VERSION "HINBNNNYYNNNYYNNNNNNNNNNNNYNNNYYYNNYNNNNNN/4//%%/4/'%**4NNN///"

NS_ :

BS_:

BU_: VirtualNMTMaster Master LadderDrive ControlPanel SupportFront SupportRear TTGateway

BO_ 1420 SSDO_012: 8 SupportFront
 SG_ supported_drive_modes_6502 m0 : 32|32@1+ (1,0) [0|4294967295] "" Vector__XXX
 SG_ SubIndex_6502 m25858M : 24|8@1+ (1,0) [0|0] "" Vector__XXX
 SG_ motor_service_period_6407 m0 : 32|32@1+ (1,0) [0|4294967295] "" Vector__XXX
 SG_ SubIndex_6407 m25607M : 24|8@1+ (1,0) [0|0] "" Vector__XXX
 SG_ motor_type_6402 m0 : 32|16@1+ (1,0) [0|65535] "" Vector__XXX
 SG_ SubIndex_6402 m25602M : 24|8@1+ (1,0) [0|0] "" Vector__XXX
 SG_ bitmask_60FE_02 m2 : 32|32@1+ (1,0) [0|4294967295] "" Vector__XXX
 SG_ physical_outputs_60FE_01 m1 : 32|32@1+ (1,0) [0|4294967295] "" Vector__XXX
 SG_ NrOfObjects_60FE_00 m0 : 32|8@1+ (1,0) [0|255] "" Vector__XXX
 SG_ SubIndex_60FE m24830M : 24|8@1+ (1,0) [0|2] "" Vector__XXX
 SG_ digital_inputs_60FD m0 : 32|32@1+ (1,0) [0|4294967295] "" Vector__XXX
 SG_ SubIndex_60FD m24829M : 24|8@1+ (1,0) [0|0] "" Vector__XXX
 SG_ polarity_607E m0 : 32|8@1+ (1,0) [0|255] "" Vector__XXX
 SG_ SubIndex_607E m24702M : 24|8@1+ (1,0) [0|0] "" Vector__XXX
 SG_ position_window_6067 m0 : 32|32@1+ (1,0) [0|4294967295] "" Vector__XXX
 SG_ SubIndex_6067 m24679M : 24|8@1+ (1,0) [0|0] "" Vector__XXX
 SG_ position_actual_value_6064 m0 : 32|32@1- (1,0) [-2147483648|2147483647] "" Vector__XXX
 SG_ SubIndex_6064 m24676M : 24|8@1+ (1,0) [0|0] "" Vector__XXX
 SG_ position_actual_value_6063 m0 : 32|32@1- (1,0) [-2147483648|2147483647] "" Vector__XXX
 SG_ SubIndex_6063 m24675M : 24|8@1+ (1,0) [0|0] "" Vector__XXX
 SG_ position_demand_value_6062 m0 : 32|32@1- (1,0) [-2147483648|2147483647] "" Vector__XXX
 SG_ SubIndex_6062 m24674M : 24|8@1+ (1,0) [0|0] "" Vector__XXX
 SG_ modes_of_operation_display_6061 m0 : 32|8@1- (1,0) [-128|127] "" Vector__XXX
 SG_ SubIndex_6061 m24673M : 24|8@1+ (1,0) [0|0] "" Vector__XXX
 SG_ modes_of_operation_6060 m0 : 32|8@1- (1,0) [-128|127] "" Vector__XXX
 SG_ SubIndex_6060 m24672M : 24|8@1+ (1,0) [0|0] "" Vector__XXX
 SG_ fault_reaction_option_code_605E m0 : 32|16@1- (1,0) [-32768|32767] "" Vector__XXX
 SG_ SubIndex_605E m24670M : 24|8@1+ (1,0) [0|0] "" Vector__XXX
 SG_ stop_option_code_605D m0 : 32|16@1- (1,0) [-32768|32767] "" Vector__XXX
 SG_ SubIndex_605D m24669M : 24|8@1+ (1,0) [0|0] "" Vector__XXX
 SG_ disable_operation_option_co_0001 m0 : 32|16@1- (1,0) [-32768|32767] "" Vector__XXX
 SG_ SubIndex_605C m24668M : 24|8@1+ (1,0) [0|0] "" Vector__XXX
 SG_ shutdown_option_code_605B m0 : 32|16@1- (1,0) [-32768|32767] "" Vector__XXX
 SG_ SubIndex_605B m24667M : 24|8@1+ (1,0) [0|0] "" Vector__XXX
 SG_ quick_stop_option_code_605A m0 : 32|16@1- (1,0) [-32768|32767] "" Vector__XXX
 SG_ SubIndex_605A m24666M : 24|8@1+ (1,0) [0|0] "" Vector__XXX
 SG_ delta_time_6049_02 m2 : 32|16@1+ (1,0) [0|65535] "" Vector__XXX
 SG_ delta_speed_6049_01 m1 : 32|32@1+ (1,0) [0|4294967295] "" Vector__XXX
 SG_ NrOfObjects_6049_00 m0 : 32|8@1+ (1,0) [0|255] "" Vector__XXX
 SG_ SubIndex_6049 m24649M : 24|8@1+ (1,0) [0|2] "" Vector__XXX
 SG_ delta_time_6048_02 m2 : 32|16@1+ (1,0) [0|65535] "" Vector__XXX
 SG_ delta_speed_6048_01 m1 : 32|32@1+ (1,0) [0|4294967295] "" Vector__XXX
 SG_ NrOfObjects_6048_00 m0 : 32|8@1+ (1,0) [0|255] "" Vector__XXX
 SG_ SubIndex_6048 m24648M : 24|8@1+ (1,0) [0|2] "" Vector__XXX
 SG_ vl_velocity_max_amount_6046_02 m2 : 32|32@1+ (1,0) [0|4294967295] "" Vector__XXX
 SG_ vl_velocity_min_amount_6046_01 m1 : 32|32@1+ (1,0) [0|4294967295] "" Vector__XXX
 SG_ vl_velocity_min_max_amount__0001 m0 : 32|8@1+ (1,0) [0|255] "" Vector__XXX
 SG_ SubIndex_6046 m24646M : 24|8@1+ (1,0) [0|2] "" Vector__XXX
 SG_ vl_control_effort_6044 m0 : 32|16@1- (1,0) [-32768|32767] "" Vector__XXX
 SG_ SubIndex_6044 m24644M : 24|8@1+ (1,0) [0|0] "" Vector__XXX
 SG_ vl_velocity_demand_6043 m0 : 32|16@1- (1,0) [-32768|32767] "" Vector__XXX
 SG_ SubIndex_6043 m24643M : 24|8@1+ (1,0) [0|0] "" Vector__XXX
 SG_ vl_target_velocity_6042 m0 : 32|16@1- (1,0) [-32768|32767] "" Vector__XXX
 SG_ SubIndex_6042 m24642M : 24|8@1+ (1,0) [0|0] "" Vector__XXX
 SG_ statusword_6041 m0 : 32|16@1+ (1,0) [0|65535] "" Vector__XXX
 SG_ SubIndex_6041 m24641M : 24|8@1+ (1,0) [0|0] "" Vector__XXX
 SG_ controlword_6040 m0 : 32|16@1+ (1,0) [0|65535] "" Vector__XXX
 SG_ SubIndex_6040 m24640M : 24|8@1+ (1,0) [0|0] "" Vector__XXX
 SG_ error_code_603F m0 : 32|16@1+ (1,0) [0|65535] "" Vector__XXX
 SG_ SubIndex_603F m24639M : 24|8@1+ (1,0) [0|0] "" Vector__XXX
 SG_ abort_connection_option_cod_0001 m0 : 32|16@1- (1,0) [-32768|3] "" Vector__XXX
 SG_ SubIndex_6007 m24583M : 24|8@1+ (1,0) [0|0] "" Vector__XXX
 SG_ NrOfMappedObjects_1A06_00 m0 : 32|8@1+ (1,0) [0|8] "" Vector__XXX
 SG_ SubIndex_1A06 m6662M : 24|8@1+ (1,0) [0|0] "" Vector__XXX
 SG_ NrOfMappedObjects_1A05_00 m0 : 32|8@1+ (1,0) [0|8] "" Vector__XXX
 SG_ SubIndex_1A05 m6661M : 24|8@1+ (1,0) [0|0] "" Vector__XXX
 SG_ NrOfMappedObjects_1A04_00 m0 : 32|8@1+ (1,0) [0|8] "" Vector__XXX
 SG_ SubIndex_1A04 m6660M : 24|8@1+ (1,0) [0|0] "" Vector__XXX
 SG_ NrOfMappedObjects_1A03_00 m0 : 32|8@1+ (1,0) [0|8] "" Vector__XXX
 SG_ SubIndex_1A03 m6659M : 24|8@1+ (1,0) [0|0] "" Vector__XXX
 SG_ NrOfMappedObjects_1A02_00 m0 : 32|8@1+ (1,0) [0|8] "" Vector__XXX
 SG_ SubIndex_1A02 m6658M : 24|8@1+ (1,0) [0|0] "" Vector__XXX
 SG_ NrOfMappedObjects_1A01_00 m0 : 32|8@1+ (1,0) [0|8] "" Vector__XXX
 SG_ SubIndex_1A01 m6657M : 24|8@1+ (1,0) [0|0] "" Vector__XXX
 SG_ mappedObj2_1A00_02 m2 : 32|32@1+ (1,0) [0|4294967295] "" Vector__XXX
 SG_ mappedObj1_1A00_01 m1 : 32|32@1+ (1,0) [0|4294967295] "" Vector__XXX
 SG_ NrOfMappedObjects_1A00_00 m0 : 32|8@1+ (1,0) [0|8] "" Vector__XXX
 SG_ SubIndex_1A00 m6656M : 24|8@1+ (1,0) [0|2] "" Vector__XXX
 SG_ EventTimer_1806_05 m5 : 32|16@1+ (1,0) [0|65535] "" Vector__XXX
 SG_ TransmissionType_1806_02 m2 : 32|8@1+ (1,0) [0|255] "" Vector__XXX
 SG_ COB_ID_1806_01 m1 : 32|32@1+ (1,0) [128|4294967295] "" Vector__XXX
 SG_ NrOfEntries_1806_00 m0 : 32|8@1+ (1,0) [2|5] "" Vector__XXX
 SG_ SubIndex_1806 m6150M : 24|8@1+ (1,0) [0|5] "" Vector__XXX
 SG_ EventTimer_1805_05 m5 : 32|16@1+ (1,0) [0|65535] "" Vector__XXX
 SG_ TransmissionType_1805_02 m2 : 32|8@1+ (1,0) [0|255] "" Vector__XXX
 SG_ COB_ID_1805_01 m1 : 32|32@1+ (1,0) [128|4294967295] "" Vector__XXX
 SG_ NrOfEntries_1805_00 m0 : 32|8@1+ (1,0) [2|5] "" Vector__XXX
 SG_ SubIndex_1805 m6149M : 24|8@1+ (1,0) [0|5] "" Vector__XXX
 SG_ EventTimer_1804_05 m5 : 32|16@1+ (1,0) [0|65535] "" Vector__XXX
 SG_ TransmissionType_1804_02 m2 : 32|8@1+ (1,0) [0|255] "" Vector__XXX
 SG_ COB_ID_1804_01 m1 : 32|32@1+ (1,0) [128|4294967295] "" Vector__XXX
 SG_ NrOfEntries_1804_00 m0 : 32|8@1+ (1,0) [2|5] "" Vector__XXX
 SG_ SubIndex_1804 m6148M : 24|8@1+ (1,0) [0|5] "" Vector__XXX
 SG_ EventTimer_1803_05 m5 : 32|16@1+ (1,0) [0|65535] "" Vector__XXX
 SG_ TransmissionType_1803_02 m2 : 32|8@1+ (1,0) [0|255] "" Vector__XXX
 SG_ COB_ID_1803_01 m1 : 32|32@1+ (1,0) [128|4294967295] "" Vector__XXX
 SG_ NrOfEntries_1803_00 m0 : 32|8@1+ (1,0) [2|5] "" Vector__XXX
 SG_ SubIndex_1803 m6147M : 24|8@1+ (1,0) [0|5] "" Vector__XXX
 SG_ EventTimer_1802_05 m5 : 32|16@1+ (1,0) [0|65535] "" Vector__XXX
 SG_ TransmissionType_1802_02 m2 : 32|8@1+ (1,0) [0|255] "" Vector__XXX
 SG_ COB_ID_1802_01 m1 : 32|32@1+ (1,0) [128|4294967295] "" Vector__XXX
 SG_ NrOfEntries_1802_00 m0 : 32|8@1+ (1,0) [2|5] "" Vector__XXX
 SG_ SubIndex_1802 m6146M : 24|8@1+ (1,0) [0|5] "" Vector__XXX
 SG_ EventTimer_1801_05 m5 : 32|16@1+ (1,0) [0|65535] "" Vector__XXX
 SG_ TransmissionType_1801_02 m2 : 32|8@1+ (1,0) [0|255] "" Vector__XXX
 SG_ COB_ID_1801_01 m1 : 32|32@1+ (1,0) [128|4294967295] "" Vector__XXX
 SG_ NrOfEntries_1801_00 m0 : 32|8@1+ (1,0) [2|5] "" Vector__XXX
 SG_ SubIndex_1801 m6145M : 24|8@1+ (1,0) [0|5] "" Vector__XXX
 SG_ EventTimer_1800_05 m5 : 32|16@1+ (1,0) [0|65535] "" Vector__XXX
 SG_ TransmissionType_1800_02 m2 : 32|8@1+ (1,0) [0|255] "" Vector__XXX
 SG_ COB_ID_1800_01 m1 : 32|32@1+ (1,0) [128|4294967295] "" Vector__XXX
 SG_ NrOfEntries_1800_00 m0 : 32|8@1+ (1,0) [2|5] "" Vector__XXX
 SG_ SubIndex_1800 m6144M : 24|8@1+ (1,0) [0|5] "" Vector__XXX
 SG_ NrOfMappedObjects_1607_00 m0 : 32|8@1+ (1,0) [0|8] "" Vector__XXX
 SG_ SubIndex_1607 m5639M : 24|8@1+ (1,0) [0|0] "" Vector__XXX
 SG_ NrOfMappedObjects_1606_00 m0 : 32|8@1+ (1,0) [0|8] "" Vector__XXX
 SG_ SubIndex_1606 m5638M : 24|8@1+ (1,0) [0|0] "" Vector__XXX
 SG_ NrOfMappedObjects_1605_00 m0 : 32|8@1+ (1,0) [0|8] "" Vector__XXX
 SG_ SubIndex_1605 m5637M : 24|8@1+ (1,0) [0|0] "" Vector__XXX
 SG_ NrOfMappedObjects_1604_00 m0 : 32|8@1+ (1,0) [0|8] "" Vector__XXX
 SG_ SubIndex_1604 m5636M : 24|8@1+ (1,0) [0|0] "" Vector__XXX
 SG_ NrOfMappedObjects_1603_00 m0 : 32|8@1+ (1,0) [0|8] "" Vector__XXX
 SG_ SubIndex_1603 m5635M : 24|8@1+ (1,0) [0|0] "" Vector__XXX
 SG_ NrOfMappedObjects_1602_00 m0 : 32|8@1+ (1,0) [0|8] "" Vector__XXX
 SG_ SubIndex_1602 m5634M : 24|8@1+ (1,0) [0|0] "" Vector__XXX
 SG_ NrOfMappedObjects_1601_00 m0 : 32|8@1+ (1,0) [0|8] "" Vector__XXX
 SG_ SubIndex_1601 m5633M : 24|8@1+ (1,0) [0|0] "" Vector__XXX
 SG_ mappedObj2_1600_02 m2 : 32|32@1+ (1,0) [0|4294967295] "" Vector__XXX
 SG_ mappedObj1_1600_01 m1 : 32|32@1+ (1,0) [0|4294967295] "" Vector__XXX
 SG_ NrOfMappedObjects_1600_00 m0 : 32|8@1+ (1,0) [0|8] "" Vector__XXX
 SG_ SubIndex_1600 m5632M : 24|8@1+ (1,0) [0|2] "" Vector__XXX
 SG_ TransmissionType_1407_02 m2 : 32|8@1+ (1,0) [0|255] "" Vector__XXX
 SG_ COB_ID_1407_01 m1 : 32|32@1+ (1,0) [128|4294967295] "" Vector__XXX
 SG_ NrOfEntries_1407_00 m0 : 32|8@1+ (1,0) [2|5] "" Vector__XXX
 SG_ SubIndex_1407 m5127M : 24|8@1+ (1,0) [0|2] "" Vector__XXX
 SG_ TransmissionType_1406_02 m2 : 32|8@1+ (1,0) [0|255] "" Vector__XXX
 SG_ COB_ID_1406_01 m1 : 32|32@1+ (1,0) [128|4294967295] "" Vector__XXX
 SG_ NrOfEntries_1406_00 m0 : 32|8@1+ (1,0) [2|5] "" Vector__XXX
 SG_ SubIndex_1406 m5126M : 24|8@1+ (1,0) [0|2] "" Vector__XXX
 SG_ TransmissionType_1405_02 m2 : 32|8@1+ (1,0) [0|255] "" Vector__XXX
 SG_ COB_ID_1405_01 m1 : 32|32@1+ (1,0) [128|4294967295] "" Vector__XXX
 SG_ NrOfEntries_1405_00 m0 : 32|8@1+ (1,0) [2|5] "" Vector__XXX
 SG_ SubIndex_1405 m5125M : 24|8@1+ (1,0) [0|2] "" Vector__XXX
 SG_ TransmissionType_1404_02 m2 : 32|8@1+ (1,0) [0|255] "" Vector__XXX
 SG_ COB_ID_1404_01 m1 : 32|32@1+ (1,0) [128|4294967295] "" Vector__XXX
 SG_ NrOfEntries_1404_00 m0 : 32|8@1+ (1,0) [2|5] "" Vector__XXX
 SG_ SubIndex_1404 m5124M : 24|8@1+ (1,0) [0|2] "" Vector__XXX
 SG_ TransmissionType_1403_02 m2 : 32|8@1+ (1,0) [0|255] "" Vector__XXX
 SG_ COB_ID_1403_01 m1 : 32|32@1+ (1,0) [128|4294967295] "" Vector__XXX
 SG_ NrOfEntries_1403_00 m0 : 32|8@1+ (1,0) [2|5] "" Vector__XXX
 SG_ SubIndex_1403 m5123M : 24|8@1+ (1,0) [0|2] "" Vector__XXX
 SG_ TransmissionType_1402_02 m2 : 32|8@1+ (1,0) [0|255] "" Vector__XXX
 SG_ COB_ID_1402_01 m1 : 32|32@1+ (1,0) [128|4294967295] "" Vector__XXX
 SG_ NrOfEntries_1402_00 m0 : 32|8@1+ (1,0) [2|5] "" Vector__XXX
 SG_ SubIndex_1402 m5122M : 24|8@1+ (1,0) [0|2] "" Vector__XXX
 SG_ TransmissionType_1401_02 m2 : 32|8@1+ (1,0) [0|255] "" Vector__XXX
 SG_ COB_ID_1401_01 m1 : 32|32@1+ (1,0) [128|4294967295] "" Vector__XXX
 SG_ NrOfEntries_1401_00 m0 : 32|8@1+ (1,0) [2|5] "" Vector__XXX
 SG_ SubIndex_1401 m5121M : 24|8@1+ (1,0) [0|2] "" Vector__XXX
 SG_ TransmissionType_1400_02 m2 : 32|8@1+ (1,0) [0|255] "" Vector__XXX
 SG_ COB_ID_1400_01 m1 : 32|32@1+ (1,0) [128|4294967295] "" Vector__XXX
 SG_ NrOfEntries_1400_00 m0 : 32|8@1+ (1,0) [2|5] "" Vector__XXX
 SG_ SubIndex_1400 m5120M : 24|8@1+ (1,0) [0|2] "" Vector__XXX
 SG_ Serial_number_1018_04 m4 : 32|32@1+ (1,0) [0|4294967295] "" Vector__XXX
 SG_ Revision_number_1018_03 m3 : 32|32@1+ (1,0) [0|4294967295] "" Vector__XXX
 SG_ Product_Code_1018_02 m2 : 32|32@1+ (1,0) [0|4294967295] "" Vector__XXX
 SG_ Vendor_Id_1018_01 m1 : 32|32@1+ (1,0) [0|4294967295] "" Vector__XXX
 SG_ number_of_entries_1018_00 m0 : 32|8@1+ (1,0) [1|4] "" Vector__XXX
 SG_ SubIndex_1018 m4120M : 24|8@1+ (1,0) [0|4] "" Vector__XXX
 SG_ Producer_Heartbeat_Time_1017 m0 : 32|16@1+ (1,0) [0|65535] "" Vector__XXX
 SG_ SubIndex_1017 m4119M : 24|8@1+ (1,0) [0|0] "" Vector__XXX
 SG_ Consumer_heartbeat_time_1016_7E m126 : 32|32@1+ (1,0) [0|4294967295] "" Vector__XXX
 SG_ Consumer_heartbeat_time_1016_7D m125 : 32|32@1+ (1,0) [0|4294967295] "" Vector__XXX
 SG_ Consumer_heartbeat_time_1016_7C m124 : 32|32@1+ (1,0) [0|4294967295] "" Vector__XXX
 SG_ Consumer_heartbeat_time_1016_7B m123 : 32|32@1+ (1,0) [0|4294967295] "" Vector__XXX
 SG_ Consumer_heartbeat_time_1016_7A m122 : 32|32@1+ (1,0) [0|4294967295] "" Vector__XXX
 SG_ Consumer_heartbeat_time_1016_79 m121 : 32|32@1+ (1,0) [0|4294967295] "" Vector__XXX
 SG_ Consumer_heartbeat_time_1016_78 m120 : 32|32@1+ (1,0) [0|4294967295] "" Vector__XXX
 SG_ Consumer_heartbeat_time_1016_77 m119 : 32|32@1+ (1,0) [0|4294967295] "" Vector__XXX
 SG_ Consumer_heartbeat_time_1016_76 m118 : 32|32@1+ (1,0) [0|4294967295] "" Vector__XXX
 SG_ Consumer_heartbeat_time_1016_75 m117 : 32|32@1+ (1,0) [0|4294967295] "" Vector__XXX
 SG_ Consumer_heartbeat_time_1016_74 m116 : 32|32@1+ (1,0) [0|4294967295] "" Vector__XXX
 SG_ Consumer_heartbeat_time_1016_73 m115 : 32|32@1+ (1,0) [0|4294967295] "" Vector__XXX
 SG_ Consumer_heartbeat_time_1016_72 m114 : 32|32@1+ (1,0) [0|4294967295] "" Vector__XXX
 SG_ Consumer_heartbeat_time_1016_71 m113 : 32|32@1+ (1,0) [0|4294967295] "" Vector__XXX
 SG_ Consumer_heartbeat_time_1016_70 m112 : 32|32@1+ (1,0) [0|4294967295] "" Vector__XXX
 SG_ Consumer_heartbeat_time_1016_6F m111 : 32|32@1+ (1,0) [0|4294967295] "" Vector__XXX
 SG_ Consumer_heartbeat_time_1016_6E m110 : 32|32@1+ (1,0) [0|4294967295] "" Vector__XXX
 SG_ Consumer_heartbeat_time_1016_6D m109 : 32|32@1+ (1,0) [0|4294967295] "" Vector__XXX
 SG_ Consumer_heartbeat_time_1016_6C m108 : 32|32@1+ (1,0) [0|4294967295] "" Vector__XXX
 SG_ Consumer_heartbeat_time_1016_6B m107 : 32|32@1+ (1,0) [0|4294967295] "" Vector__XXX
 SG_ Consumer_heartbeat_time_1016_6A m106 : 32|32@1+ (1,0) [0|4294967295] "" Vector__XXX
 SG_ Consumer_heartbeat_time_1016_69 m105 : 32|32@1+ (1,0) [0|4294967295] "" Vector__XXX
 SG_ Consumer_heartbeat_time_1016_68 m104 : 32|32@1+ (1,0) [0|4294967295] "" Vector__XXX
 SG_ Consumer_heartbeat_time_1016_67 m103 : 32|32@1+ (1,0) [0|4294967295] "" Vector__XXX
 SG_ Consumer_heartbeat_time_1016_66 m102 : 32|32@1+ (1,0) [0|4294967295] "" Vector__XXX
 SG_ Consumer_heartbeat_time_1016_65 m101 : 32|32@1+ (1,0) [0|4294967295] "" Vector__XXX
 SG_ Consumer_heartbeat_time_1016_64 m100 : 32|32@1+ (1,0) [0|4294967295] "" Vector__XXX
 SG_ Consumer_heartbeat_time_1016_63 m99 : 32|32@1+ (1,0) [0|4294967295] "" Vector__XXX
 SG_ Consumer_heartbeat_time_1016_62 m98 : 32|32@1+ (1,0) [0|4294967295] "" Vector__XXX
 SG_ Consumer_heartbeat_time_1016_61 m97 : 32|32@1+ (1,0) [0|4294967295] "" Vector__XXX
 SG_ Consumer_heartbeat_time_1016_60 m96 : 32|32@1+ (1,0) [0|4294967295] "" Vector__XXX
 SG_ Consumer_heartbeat_time_1016_5F m95 : 32|32@1+ (1,0) [0|4294967295] "" Vector__XXX
 SG_ Consumer_heartbeat_time_1016_5E m94 : 32|32@1+ (1,0) [0|4294967295] "" Vector__XXX
 SG_ Consumer_heartbeat_time_1016_5D m93 : 32|32@1+ (1,0) [0|4294967295] "" Vector__XXX
 SG_ Consumer_heartbeat_time_1016_5C m92 : 32|32@1+ (1,0) [0|4294967295] "" Vector__XXX
 SG_ Consumer_heartbeat_time_1016_5B m91 : 32|32@1+ (1,0) [0|4294967295] "" Vector__XXX
 SG_ Consumer_heartbeat_time_1016_5A m90 : 32|32@1+ (1,0) [0|4294967295] "" Vector__XXX
 SG_ Consumer_heartbeat_time_1016_59 m89 : 32|32@1+ (1,0) [0|4294967295] "" Vector__XXX
 SG_ Consumer_heartbeat_time_1016_58 m88 : 32|32@1+ (1,0) [0|4294967295] "" Vector__XXX
 SG_ Consumer_heartbeat_time_1016_57 m87 : 32|32@1+ (1,0) [0|4294967295] "" Vector__XXX
 SG_ Consumer_heartbeat_time_1016_56 m86 : 32|32@1+ (1,0) [0|4294967295] "" Vector__XXX
 SG_ Consumer_heartbeat_time_1016_55 m85 : 32|32@1+ (1,0) [0|4294967295] "" Vector__XXX
 SG_ Consumer_heartbeat_time_1016_54 m84 : 32|32@1+ (1,0) [0|4294967295] "" Vector__XXX
 SG_ Consumer_heartbeat_time_1016_53 m83 : 32|32@1+ (1,0) [0|4294967295] "" Vector__XXX
 SG_ Consumer_heartbeat_time_1016_52 m82 : 32|32@1+ (1,0) [0|4294967295] "" Vector__XXX
 SG_ Consumer_heartbeat_time_1016_51 m81 : 32|32@1+ (1,0) [0|4294967295] "" Vector__XXX
 SG_ Consumer_heartbeat_time_1016_50 m80 : 32|32@1+ (1,0) [0|4294967295] "" Vector__XXX
 SG_ Consumer_heartbeat_time_1016_4F m79 : 32|32@1+ (1,0) [0|4294967295] "" Vector__XXX
 SG_ Consumer_heartbeat_time_1016_4E m78 : 32|32@1+ (1,0) [0|4294967295] "" Vector__XXX
 SG_ Consumer_heartbeat_time_1016_4D m77 : 32|32@1+ (1,0) [0|4294967295] "" Vector__XXX
 SG_ Consumer_heartbeat_time_1016_4C m76 : 32|32@1+ (1,0) [0|4294967295] "" Vector__XXX
 SG_ Consumer_heartbeat_time_1016_4B m75 : 32|32@1+ (1,0) [0|4294967295] "" Vector__XXX
 SG_ Consumer_heartbeat_time_1016_4A m74 : 32|32@1+ (1,0) [0|4294967295] "" Vector__XXX
 SG_ Consumer_heartbeat_time_1016_49 m73 : 32|32@1+ (1,0) [0|4294967295] "" Vector__XXX
 SG_ Consumer_heartbeat_time_1016_48 m72 : 32|32@1+ (1,0) [0|4294967295] "" Vector__XXX
 SG_ Consumer_heartbeat_time_1016_47 m71 : 32|32@1+ (1,0) [0|4294967295] "" Vector__XXX
 SG_ Consumer_heartbeat_time_1016_46 m70 : 32|32@1+ (1,0) [0|4294967295] "" Vector__XXX
 SG_ Consumer_heartbeat_time_1016_45 m69 : 32|32@1+ (1,0) [0|4294967295] "" Vector__XXX
 SG_ Consumer_heartbeat_time_1016_44 m68 : 32|32@1+ (1,0) [0|4294967295] "" Vector__XXX
 SG_ Consumer_heartbeat_time_1016_43 m67 : 32|32@1+ (1,0) [0|4294967295] "" Vector__XXX
 SG_ Consumer_heartbeat_time_1016_42 m66 : 32|32@1+ (1,0) [0|4294967295] "" Vector__XXX
 SG_ Consumer_heartbeat_time_1016_41 m65 : 32|32@1+ (1,0) [0|4294967295] "" Vector__XXX
 SG_ Consumer_heartbeat_time_1016_40 m64 : 32|32@1+ (1,0) [0|4294967295] "" Vector__XXX
 SG_ Consumer_heartbeat_time_1016_3F m63 : 32|32@1+ (1,0) [0|4294967295] "" Vector__XXX
 SG_ Consumer_heartbeat_time_1016_3E m62 : 32|32@1+ (1,0) [0|4294967295] "" Vector__XXX
 SG_ Consumer_heartbeat_time_1016_3D m61 : 32|32@1+ (1,0) [0|4294967295] "" Vector__XXX
 SG_ Consumer_heartbeat_time_1016_3C m60 : 32|32@1+ (1,0) [0|4294967295] "" Vector__XXX
 SG_ Consumer_heartbeat_time_1016_3B m59 : 32|32@1+ (1,0) [0|4294967295] "" Vector__XXX
 SG_ Consumer_heartbeat_time_1016_3A m58 : 32|32@1+ (1,0) [0|4294967295] "" Vector__XXX
 SG_ Consumer_heartbeat_time_1016_39 m57 : 32|32@1+ (1,0) [0|4294967295] "" Vector__XXX
 SG_ Consumer_heartbeat_time_1016_38 m56 : 32|32@1+ (1,0) [0|4294967295] "" Vector__XXX
 SG_ Consumer_heartbeat_time_1016_37 m55 : 32|32@1+ (1,0) [0|4294967295] "" Vector__XXX
 SG_ Consumer_heartbeat_time_1016_36 m54 : 32|32@1+ (1,0) [0|4294967295] "" Vector__XXX
 SG_ Consumer_heartbeat_time_1016_35 m53 : 32|32@1+ (1,0) [0|4294967295] "" Vector__XXX
 SG_ Consumer_heartbeat_time_1016_34 m52 : 32|32@1+ (1,0) [0|4294967295] "" Vector__XXX
 SG_ Consumer_heartbeat_time_1016_33 m51 : 32|32@1+ (1,0) [0|4294967295] "" Vector__XXX
 SG_ Consumer_heartbeat_time_1016_32 m50 : 32|32@1+ (1,0) [0|4294967295] "" Vector__XXX
 SG_ Consumer_heartbeat_time_1016_31 m49 : 32|32@1+ (1,0) [0|4294967295] "" Vector__XXX
 SG_ Consumer_heartbeat_time_1016_30 m48 : 32|32@1+ (1,0) [0|4294967295] "" Vector__XXX
 SG_ Consumer_heartbeat_time_1016_2F m47 : 32|32@1+ (1,0) [0|4294967295] "" Vector__XXX
 SG_ Consumer_heartbeat_time_1016_2E m46 : 32|32@1+ (1,0) [0|4294967295] "" Vector__XXX
 SG_ Consumer_heartbeat_time_1016_2D m45 : 32|32@1+ (1,0) [0|4294967295] "" Vector__XXX
 SG_ Consumer_heartbeat_time_1016_2C m44 : 32|32@1+ (1,0) [0|4294967295] "" Vector__XXX
 SG_ Consumer_heartbeat_time_1016_2B m43 : 32|32@1+ (1,0) [0|4294967295] "" Vector__XXX
 SG_ Consumer_heartbeat_time_1016_2A m42 : 32|32@1+ (1,0) [0|4294967295] "" Vector__XXX
 SG_ Consumer_heartbeat_time_1016_29 m41 : 32|32@1+ (1,0) [0|4294967295] "" Vector__XXX
 SG_ Consumer_heartbeat_time_1016_28 m40 : 32|32@1+ (1,0) [0|4294967295] "" Vector__XXX
 SG_ Consumer_heartbeat_time_1016_27 m39 : 32|32@1+ (1,0) [0|4294967295] "" Vector__XXX
 SG_ Consumer_heartbeat_time_1016_26 m38 : 32|32@1+ (1,0) [0|4294967295] "" Vector__XXX
 SG_ Consumer_heartbeat_time_1016_25 m37 : 32|32@1+ (1,0) [0|4294967295] "" Vector__XXX
 SG_ Consumer_heartbeat_time_1016_24 m36 : 32|32@1+ (1,0) [0|4294967295] "" Vector__XXX
 SG_ Consumer_heartbeat_time_1016_23 m35 : 32|32@1+ (1,0) [0|4294967295] "" Vector__XXX
 SG_ Consumer_heartbeat_time_1016_22 m34 : 32|32@1+ (1,0) [0|4294967295] "" Vector__XXX
 SG_ Consumer_heartbeat_time_1016_21 m33 : 32|32@1+ (1,0) [0|4294967295] "" Vector__XXX
 SG_ Consumer_heartbeat_time_1016_20 m32 : 32|32@1+ (1,0) [0|4294967295] "" Vector__XXX
 SG_ Consumer_heartbeat_time_1016_1F m31 : 32|32@1+ (1,0) [0|4294967295] "" Vector__XXX
 SG_ Consumer_heartbeat_time_1016_1E m30 : 32|32@1+ (1,0) [0|4294967295] "" Vector__XXX
 SG_ Consumer_heartbeat_time_1016_1D m29 : 32|32@1+ (1,0) [0|4294967295] "" Vector__XXX
 SG_ Consumer_heartbeat_time_1016_1C m28 : 32|32@1+ (1,0) [0|4294967295] "" Vector__XXX
 SG_ Consumer_heartbeat_time_1016_1B m27 : 32|32@1+ (1,0) [0|4294967295] "" Vector__XXX
 SG_ Consumer_heartbeat_time_1016_1A m26 : 32|32@1+ (1,0) [0|4294967295] "" Vector__XXX
 SG_ Consumer_heartbeat_time_1016_19 m25 : 32|32@1+ (1,0) [0|4294967295] "" Vector__XXX
 SG_ Consumer_heartbeat_time_1016_18 m24 : 32|32@1+ (1,0) [0|4294967295] "" Vector__XXX
 SG_ Consumer_heartbeat_time_1016_17 m23 : 32|32@1+ (1,0) [0|4294967295] "" Vector__XXX
 SG_ Consumer_heartbeat_time_1016_16 m22 : 32|32@1+ (1,0) [0|4294967295] "" Vector__XXX
 SG_ Consumer_heartbeat_time_1016_15 m21 : 32|32@1+ (1,0) [0|4294967295] "" Vector__XXX
 SG_ Consumer_heartbeat_time_1016_14 m20 : 32|32@1+ (1,0) [0|4294967295] "" Vector__XXX
 SG_ Consumer_heartbeat_time_1016_13 m19 : 32|32@1+ (1,0) [0|4294967295] "" Vector__XXX
 SG_ Consumer_heartbeat_time_1016_12 m18 : 32|32@1+ (1,0) [0|4294967295] "" Vector__XXX
 SG_ Consumer_heartbeat_time_1016_11 m17 : 32|32@1+ (1,0) [0|4294967295] "" Vector__XXX
 SG_ Consumer_heartbeat_time_1016_10 m16 : 32|32@1+ (1,0) [0|4294967295] "" Vector__XXX
 SG_ Consumer_heartbeat_time_1016_0F m15 : 32|32@1+ (1,0) [0|4294967295] "" Vector__XXX
 SG_ Consumer_heartbeat_time_1016_0E m14 : 32|32@1+ (1,0) [0|4294967295] "" Vector__XXX
 SG_ Consumer_heartbeat_time_1016_0D m13 : 32|32@1+ (1,0) [0|4294967295] "" Vector__XXX
 SG_ Consumer_heartbeat_time_1016_0C m12 : 32|32@1+ (1,0) [0|4294967295] "" Vector__XXX
 SG_ Consumer_heartbeat_time_1016_0B m11 : 32|32@1+ (1,0) [0|4294967295] "" Vector__XXX
 SG_ Consumer_heartbeat_time_1016_0A m10 : 32|32@1+ (1,0) [0|4294967295] "" Vector__XXX
 SG_ Consumer_Heartbeat_Time_1016_09 m9 : 32|32@1+ (1,0) [0|4294967295] "" Vector__XXX
 SG_ Consumer_Heartbeat_Time_1016_08 m8 : 32|32@1+ (1,0) [0|4294967295] "" Vector__XXX
 SG_ Consumer_Heartbeat_Time_1016_07 m7 : 32|32@1+ (1,0) [0|4294967295] "" Vector__XXX
 SG_ Consumer_Heartbeat_Time_1016_06 m6 : 32|32@1+ (1,0) [0|4294967295] "" Vector__XXX
 SG_ Consumer_Heartbeat_Time_1016_05 m5 : 32|32@1+ (1,0) [0|4294967295] "" Vector__XXX
 SG_ Consumer_Heartbeat_Time_1016_04 m4 : 32|32@1+ (1,0) [0|4294967295] "" Vector__XXX
 SG_ Consumer_Heartbeat_Time_1016_03 m3 : 32|32@1+ (1,0) [0|4294967295] "" Vector__XXX
 SG_ Consumer_Heartbeat_Time_1016_02 m2 : 32|32@1+ (1,0) [0|4294967295] "" Vector__XXX
 SG_ Consumer_Heartbeat_Time_1016_01 m1 : 32|32@1+ (1,0) [0|4294967295] "" Vector__XXX
 SG_ Highest_sub_index_supported_1016 m0 : 32|8@1+ (1,0) [0|255] "" Vector__XXX
 SG_ SubIndex_1016 m4118M : 24|8@1+ (1,0) [0|126] "" Vector__XXX
 SG_ Save_all_Parameters_1010_01 m1 : 32|32@1+ (1,0) [0|4294967295] "" Vector__XXX
 SG_ Number_of_Entries_1010_00 m0 : 32|8@1+ (1,0) [0|255] "" Vector__XXX
 SG_ SubIndex_1010 m4112M : 24|8@1+ (1,0) [0|1] "" Vector__XXX
 SG_ Life_Time_Factor_100D m0 : 32|8@1+ (1,0) [0|255] "" Vector__XXX
 SG_ SubIndex_100D m4109M : 24|8@1+ (1,0) [0|0] "" Vector__XXX
 SG_ Guard_Time_100C m0 : 32|16@1+ (1,0) [0|65535] "" Vector__XXX
 SG_ SubIndex_100C m4108M : 24|8@1+ (1,0) [0|0] "" Vector__XXX
 SG_ Sync_Window_Length_1007 m0 : 32|32@1+ (1,0) [0|4294967295] "" Vector__XXX
 SG_ SubIndex_1007 m4103M : 24|8@1+ (1,0) [0|0] "" Vector__XXX
 SG_ Communication_Cycle_Period_1006 m0 : 32|32@1+ (1,0) [0|4294967295] "" Vector__XXX
 SG_ SubIndex_1006 m4102M : 24|8@1+ (1,0) [0|0] "" Vector__XXX
 SG_ COB_ID_SYNC_1005 m0 : 32|32@1+ (1,0) [128|4294967295] "" Vector__XXX
 SG_ SubIndex_1005 m4101M : 24|8@1+ (1,0) [0|0] "" Vector__XXX
 SG_ Manufacturer_Status_Registe_0005 m0 : 32|32@1+ (1,0) [0|4294967295] "" Vector__XXX
 SG_ SubIndex_1002 m4098M : 24|8@1+ (1,0) [0|0] "" Vector__XXX
 SG_ Error_Register_1001 m0 : 32|8@1+ (1,0) [0|255] "" Vector__XXX
 SG_ SubIndex_1001 m4097M : 24|8@1+ (1,0) [0|0] "" Vector__XXX
 SG_ Device_Type_1000 m0 : 32|32@1+ (1,0) [0|4294967295] "" Vector__XXX
 SG_ SubIndex_1000 m4096M : 24|8@1+ (1,0) [0|0] "" Vector__XXX
 SG_ Index m1M : 8|16@1+ (1,0) [4096|25861] "" Vector__XXX
 SG_ TransferType m1M : 1|1@1+ (1,0) [0|1] "" Vector__XXX
 SG_ NotUsedBytes m1 : 2|2@1+ (1,0) [0|3] "" Vector__XXX
 SG_ SizeIndicator m1 : 0|1@1+ (1,0) [0|1] "" Vector__XXX
 SG_ SCS M : 5|3@1+ (1,0) [0|6] "" Vector__XXX

BO_ 1548 CSDO_012: 8 Vector__XXX
 SG_ supported_drive_modes_6502 m0 : 32|32@1+ (1,0) [0|4294967295] ""  SupportFront
 SG_ SubIndex_6502 m25858M : 24|8@1+ (1,0) [0|0] ""  SupportFront
 SG_ motor_service_period_6407 m0 : 32|32@1+ (1,0) [0|4294967295] ""  SupportFront
 SG_ SubIndex_6407 m25607M : 24|8@1+ (1,0) [0|0] ""  SupportFront
 SG_ motor_type_6402 m0 : 32|16@1+ (1,0) [0|65535] ""  SupportFront
 SG_ SubIndex_6402 m25602M : 24|8@1+ (1,0) [0|0] ""  SupportFront
 SG_ bitmask_60FE_02 m2 : 32|32@1+ (1,0) [0|4294967295] ""  SupportFront
 SG_ physical_outputs_60FE_01 m1 : 32|32@1+ (1,0) [0|4294967295] ""  SupportFront
 SG_ NrOfObjects_60FE_00 m0 : 32|8@1+ (1,0) [0|255] ""  SupportFront
 SG_ SubIndex_60FE m24830M : 24|8@1+ (1,0) [0|2] ""  SupportFront
 SG_ digital_inputs_60FD m0 : 32|32@1+ (1,0) [0|4294967295] ""  SupportFront
 SG_ SubIndex_60FD m24829M : 24|8@1+ (1,0) [0|0] ""  SupportFront
 SG_ polarity_607E m0 : 32|8@1+ (1,0) [0|255] ""  SupportFront
 SG_ SubIndex_607E m24702M : 24|8@1+ (1,0) [0|0] ""  SupportFront
 SG_ position_window_6067 m0 : 32|32@1+ (1,0) [0|4294967295] ""  SupportFront
 SG_ SubIndex_6067 m24679M : 24|8@1+ (1,0) [0|0] ""  SupportFront
 SG_ position_actual_value_6064 m0 : 32|32@1- (1,0) [-2147483648|2147483647] ""  SupportFront
 SG_ SubIndex_6064 m24676M : 24|8@1+ (1,0) [0|0] ""  SupportFront
 SG_ position_actual_value_6063 m0 : 32|32@1- (1,0) [-2147483648|2147483647] ""  SupportFront
 SG_ SubIndex_6063 m24675M : 24|8@1+ (1,0) [0|0] ""  SupportFront
 SG_ position_demand_value_6062 m0 : 32|32@1- (1,0) [-2147483648|2147483647] ""  SupportFront
 SG_ SubIndex_6062 m24674M : 24|8@1+ (1,0) [0|0] ""  SupportFront
 SG_ modes_of_operation_display_6061 m0 : 32|8@1- (1,0) [-128|127] ""  SupportFront
 SG_ SubIndex_6061 m24673M : 24|8@1+ (1,0) [0|0] ""  SupportFront
 SG_ modes_of_operation_6060 m0 : 32|8@1- (1,0) [-128|127] ""  SupportFront
 SG_ SubIndex_6060 m24672M : 24|8@1+ (1,0) [0|0] ""  SupportFront
 SG_ fault_reaction_option_code_605E m0 : 32|16@1- (1,0) [-32768|32767] ""  SupportFront
 SG_ SubIndex_605E m24670M : 24|8@1+ (1,0) [0|0] ""  SupportFront
 SG_ stop_option_code_605D m0 : 32|16@1- (1,0) [-32768|32767] ""  SupportFront
 SG_ SubIndex_605D m24669M : 24|8@1+ (1,0) [0|0] ""  SupportFront
 SG_ disable_operation_option_co_0002 m0 : 32|16@1- (1,0) [-32768|32767] ""  SupportFront
 SG_ SubIndex_605C m24668M : 24|8@1+ (1,0) [0|0] ""  SupportFront
 SG_ shutdown_option_code_605B m0 : 32|16@1- (1,0) [-32768|32767] ""  SupportFront
 SG_ SubIndex_605B m24667M : 24|8@1+ (1,0) [0|0] ""  SupportFront
 SG_ quick_stop_option_code_605A m0 : 32|16@1- (1,0) [-32768|32767] ""  SupportFront
 SG_ SubIndex_605A m24666M : 24|8@1+ (1,0) [0|0] ""  SupportFront
 SG_ delta_time_6049_02 m2 : 32|16@1+ (1,0) [0|65535] ""  SupportFront
 SG_ delta_speed_6049_01 m1 : 32|32@1+ (1,0) [0|4294967295] ""  SupportFront
 SG_ NrOfObjects_6049_00 m0 : 32|8@1+ (1,0) [0|255] ""  SupportFront
 SG_ SubIndex_6049 m24649M : 24|8@1+ (1,0) [0|2] ""  SupportFront
 SG_ delta_time_6048_02 m2 : 32|16@1+ (1,0) [0|65535] ""  SupportFront
 SG_ delta_speed_6048_01 m1 : 32|32@1+ (1,0) [0|4294967295] ""  SupportFront
 SG_ NrOfObjects_6048_00 m0 : 32|8@1+ (1,0) [0|255] ""  SupportFront
 SG_ SubIndex_6048 m24648M : 24|8@1+ (1,0) [0|2] ""  SupportFront
 SG_ vl_velocity_max_amount_6046_02 m2 : 32|32@1+ (1,0) [0|4294967295] ""  SupportFront
 SG_ vl_velocity_min_amount_6046_01 m1 : 32|32@1+ (1,0) [0|4294967295] ""  SupportFront
 SG_ vl_velocity_min_max_amount__0002 m0 : 32|8@1+ (1,0) [0|255] ""  SupportFront
 SG_ SubIndex_6046 m24646M : 24|8@1+ (1,0) [0|2] ""  SupportFront
 SG_ vl_control_effort_6044 m0 : 32|16@1- (1,0) [-32768|32767] ""  SupportFront
 SG_ SubIndex_6044 m24644M : 24|8@1+ (1,0) [0|0] ""  SupportFront
 SG_ vl_velocity_demand_6043 m0 : 32|16@1- (1,0) [-32768|32767] ""  SupportFront
 SG_ SubIndex_6043 m24643M : 24|8@1+ (1,0) [0|0] ""  SupportFront
 SG_ vl_target_velocity_6042 m0 : 32|16@1- (1,0) [-32768|32767] ""  SupportFront
 SG_ SubIndex_6042 m24642M : 24|8@1+ (1,0) [0|0] ""  SupportFront
 SG_ statusword_6041 m0 : 32|16@1+ (1,0) [0|65535] ""  SupportFront
 SG_ SubIndex_6041 m24641M : 24|8@1+ (1,0) [0|0] ""  SupportFront
 SG_ controlword_6040 m0 : 32|16@1+ (1,0) [0|65535] ""  SupportFront
 SG_ SubIndex_6040 m24640M : 24|8@1+ (1,0) [0|0] ""  SupportFront
 SG_ error_code_603F m0 : 32|16@1+ (1,0) [0|65535] ""  SupportFront
 SG_ SubIndex_603F m24639M : 24|8@1+ (1,0) [0|0] ""  SupportFront
 SG_ abort_connection_option_cod_0002 m0 : 32|16@1- (1,0) [-32768|3] ""  SupportFront
 SG_ SubIndex_6007 m24583M : 24|8@1+ (1,0) [0|0] ""  SupportFront
 SG_ NrOfMappedObjects_1A06_00 m0 : 32|8@1+ (1,0) [0|8] ""  SupportFront
 SG_ SubIndex_1A06 m6662M : 24|8@1+ (1,0) [0|0] ""  SupportFront
 SG_ NrOfMappedObjects_1A05_00 m0 : 32|8@1+ (1,0) [0|8] ""  SupportFront
 SG_ SubIndex_1A05 m6661M : 24|8@1+ (1,0) [0|0] ""  SupportFront
 SG_ NrOfMappedObjects_1A04_00 m0 : 32|8@1+ (1,0) [0|8] ""  SupportFront
 SG_ SubIndex_1A04 m6660M : 24|8@1+ (1,0) [0|0] ""  SupportFront
 SG_ NrOfMappedObjects_1A03_00 m0 : 32|8@1+ (1,0) [0|8] ""  SupportFront
 SG_ SubIndex_1A03 m6659M : 24|8@1+ (1,0) [0|0] ""  SupportFront
 SG_ NrOfMappedObjects_1A02_00 m0 : 32|8@1+ (1,0) [0|8] ""  SupportFront
 SG_ SubIndex_1A02 m6658M : 24|8@1+ (1,0) [0|0] ""  SupportFront
 SG_ NrOfMappedObjects_1A01_00 m0 : 32|8@1+ (1,0) [0|8] ""  SupportFront
 SG_ SubIndex_1A01 m6657M : 24|8@1+ (1,0) [0|0] ""  SupportFront
 SG_ mappedObj2_1A00_02 m2 : 32|32@1+ (1,0) [0|4294967295] ""  SupportFront
 SG_ mappedObj1_1A00_01 m1 : 32|32@1+ (1,0) [0|4294967295] ""  SupportFront
 SG_ NrOfMappedObjects_1A00_00 m0 : 32|8@1+ (1,0) [0|8] ""  SupportFront
 SG_ SubIndex_1A00 m6656M : 24|8@1+ (1,0) [0|2] ""  SupportFront
 SG_ EventTimer_1806_05 m5 : 32|16@1+ (1,0) [0|65535] ""  SupportFront
 SG_ TransmissionType_1806_02 m2 : 32|8@1+ (1,0) [0|255] ""  SupportFront
 SG_ COB_ID_1806_01 m1 : 32|32@1+ (1,0) [128|4294967295] ""  SupportFront
 SG_ NrOfEntries_1806_00 m0 : 32|8@1+ (1,0) [2|5] ""  SupportFront
 SG_ SubIndex_1806 m6150M : 24|8@1+ (1,0) [0|5] ""  SupportFront
 SG_ EventTimer_1805_05 m5 : 32|16@1+ (1,0) [0|65535] ""  SupportFront
 SG_ TransmissionType_1805_02 m2 : 32|8@1+ (1,0) [0|255] ""  SupportFront
 SG_ COB_ID_1805_01 m1 : 32|32@1+ (1,0) [128|4294967295] ""  SupportFront
 SG_ NrOfEntries_1805_00 m0 : 32|8@1+ (1,0) [2|5] ""  SupportFront
 SG_ SubIndex_1805 m6149M : 24|8@1+ (1,0) [0|5] ""  SupportFront
 SG_ EventTimer_1804_05 m5 : 32|16@1+ (1,0) [0|65535] ""  SupportFront
 SG_ TransmissionType_1804_02 m2 : 32|8@1+ (1,0) [0|255] ""  SupportFront
 SG_ COB_ID_1804_01 m1 : 32|32@1+ (1,0) [128|4294967295] ""  SupportFront
 SG_ NrOfEntries_1804_00 m0 : 32|8@1+ (1,0) [2|5] ""  SupportFront
 SG_ SubIndex_1804 m6148M : 24|8@1+ (1,0) [0|5] ""  SupportFront
 SG_ EventTimer_1803_05 m5 : 32|16@1+ (1,0) [0|65535] ""  SupportFront
 SG_ TransmissionType_1803_02 m2 : 32|8@1+ (1,0) [0|255] ""  SupportFront
 SG_ COB_ID_1803_01 m1 : 32|32@1+ (1,0) [128|4294967295] ""  SupportFront
 SG_ NrOfEntries_1803_00 m0 : 32|8@1+ (1,0) [2|5] ""  SupportFront
 SG_ SubIndex_1803 m6147M : 24|8@1+ (1,0) [0|5] ""  SupportFront
 SG_ EventTimer_1802_05 m5 : 32|16@1+ (1,0) [0|65535] ""  SupportFront
 SG_ TransmissionType_1802_02 m2 : 32|8@1+ (1,0) [0|255] ""  SupportFront
 SG_ COB_ID_1802_01 m1 : 32|32@1+ (1,0) [128|4294967295] ""  SupportFront
 SG_ NrOfEntries_1802_00 m0 : 32|8@1+ (1,0) [2|5] ""  SupportFront
 SG_ SubIndex_1802 m6146M : 24|8@1+ (1,0) [0|5] ""  SupportFront
 SG_ EventTimer_1801_05 m5 : 32|16@1+ (1,0) [0|65535] ""  SupportFront
 SG_ TransmissionType_1801_02 m2 : 32|8@1+ (1,0) [0|255] ""  SupportFront
 SG_ COB_ID_1801_01 m1 : 32|32@1+ (1,0) [128|4294967295] ""  SupportFront
 SG_ NrOfEntries_1801_00 m0 : 32|8@1+ (1,0) [2|5] ""  SupportFront
 SG_ SubIndex_1801 m6145M : 24|8@1+ (1,0) [0|5] ""  SupportFront
 SG_ EventTimer_1800_05 m5 : 32|16@1+ (1,0) [0|65535] ""  SupportFront
 SG_ TransmissionType_1800_02 m2 : 32|8@1+ (1,0) [0|255] ""  SupportFront
 SG_ COB_ID_1800_01 m1 : 32|32@1+ (1,0) [128|4294967295] ""  SupportFront
 SG_ NrOfEntries_1800_00 m0 : 32|8@1+ (1,0) [2|5] ""  SupportFront
 SG_ SubIndex_1800 m6144M : 24|8@1+ (1,0) [0|5] ""  SupportFront
 SG_ NrOfMappedObjects_1607_00 m0 : 32|8@1+ (1,0) [0|8] ""  SupportFront
 SG_ SubIndex_1607 m5639M : 24|8@1+ (1,0) [0|0] ""  SupportFront
 SG_ NrOfMappedObjects_1606_00 m0 : 32|8@1+ (1,0) [0|8] ""  SupportFront
 SG_ SubIndex_1606 m5638M : 24|8@1+ (1,0) [0|0] ""  SupportFront
 SG_ NrOfMappedObjects_1605_00 m0 : 32|8@1+ (1,0) [0|8] ""  SupportFront
 SG_ SubIndex_1605 m5637M : 24|8@1+ (1,0) [0|0] ""  SupportFront
 SG_ NrOfMappedObjects_1604_00 m0 : 32|8@1+ (1,0) [0|8] ""  SupportFront
 SG_ SubIndex_1604 m5636M : 24|8@1+ (1,0) [0|0] ""  SupportFront
 SG_ NrOfMappedObjects_1603_00 m0 : 32|8@1+ (1,0) [0|8] ""  SupportFront
 SG_ SubIndex_1603 m5635M : 24|8@1+ (1,0) [0|0] ""  SupportFront
 SG_ NrOfMappedObjects_1602_00 m0 : 32|8@1+ (1,0) [0|8] ""  SupportFront
 SG_ SubIndex_1602 m5634M : 24|8@1+ (1,0) [0|0] ""  SupportFront
 SG_ NrOfMappedObjects_1601_00 m0 : 32|8@1+ (1,0) [0|8] ""  SupportFront
 SG_ SubIndex_1601 m5633M : 24|8@1+ (1,0) [0|0] ""  SupportFront
 SG_ mappedObj2_1600_02 m2 : 32|32@1+ (1,0) [0|4294967295] ""  SupportFront
 SG_ mappedObj1_1600_01 m1 : 32|32@1+ (1,0) [0|4294967295] ""  SupportFront
 SG_ NrOfMappedObjects_1600_00 m0 : 32|8@1+ (1,0) [0|8] ""  SupportFront
 SG_ SubIndex_1600 m5632M : 24|8@1+ (1,0) [0|2] ""  SupportFront
 SG_ TransmissionType_1407_02 m2 : 32|8@1+ (1,0) [0|255] ""  SupportFront
 SG_ COB_ID_1407_01 m1 : 32|32@1+ (1,0) [128|4294967295] ""  SupportFront
 SG_ NrOfEntries_1407_00 m0 : 32|8@1+ (1,0) [2|5] ""  SupportFront
 SG_ SubIndex_1407 m5127M : 24|8@1+ (1,0) [0|2] ""  SupportFront
 SG_ TransmissionType_1406_02 m2 : 32|8@1+ (1,0) [0|255] ""  SupportFront
 SG_ COB_ID_1406_01 m1 : 32|32@1+ (1,0) [128|4294967295] ""  SupportFront
 SG_ NrOfEntries_1406_00 m0 : 32|8@1+ (1,0) [2|5] ""  SupportFront
 SG_ SubIndex_1406 m5126M : 24|8@1+ (1,0) [0|2] ""  SupportFront
 SG_ TransmissionType_1405_02 m2 : 32|8@1+ (1,0) [0|255] ""  SupportFront
 SG_ COB_ID_1405_01 m1 : 32|32@1+ (1,0) [128|4294967295] ""  SupportFront
 SG_ NrOfEntries_1405_00 m0 : 32|8@1+ (1,0) [2|5] ""  SupportFront
 SG_ SubIndex_1405 m5125M : 24|8@1+ (1,0) [0|2] ""  SupportFront
 SG_ TransmissionType_1404_02 m2 : 32|8@1+ (1,0) [0|255] ""  SupportFront
 SG_ COB_ID_1404_01 m1 : 32|32@1+ (1,0) [128|4294967295] ""  SupportFront
 SG_ NrOfEntries_1404_00 m0 : 32|8@1+ (1,0) [2|5] ""  SupportFront
 SG_ SubIndex_1404 m5124M : 24|8@1+ (1,0) [0|2] ""  SupportFront
 SG_ TransmissionType_1403_02 m2 : 32|8@1+ (1,0) [0|255] ""  SupportFront
 SG_ COB_ID_1403_01 m1 : 32|32@1+ (1,0) [128|4294967295] ""  SupportFront
 SG_ NrOfEntries_1403_00 m0 : 32|8@1+ (1,0) [2|5] ""  SupportFront
 SG_ SubIndex_1403 m5123M : 24|8@1+ (1,0) [0|2] ""  SupportFront
 SG_ TransmissionType_1402_02 m2 : 32|8@1+ (1,0) [0|255] ""  SupportFront
 SG_ COB_ID_1402_01 m1 : 32|32@1+ (1,0) [128|4294967295] ""  SupportFront
 SG_ NrOfEntries_1402_00 m0 : 32|8@1+ (1,0) [2|5] ""  SupportFront
 SG_ SubIndex_1402 m5122M : 24|8@1+ (1,0) [0|2] ""  SupportFront
 SG_ TransmissionType_1401_02 m2 : 32|8@1+ (1,0) [0|255] ""  SupportFront
 SG_ COB_ID_1401_01 m1 : 32|32@1+ (1,0) [128|4294967295] ""  SupportFront
 SG_ NrOfEntries_1401_00 m0 : 32|8@1+ (1,0) [2|5] ""  SupportFront
 SG_ SubIndex_1401 m5121M : 24|8@1+ (1,0) [0|2] ""  SupportFront
 SG_ TransmissionType_1400_02 m2 : 32|8@1+ (1,0) [0|255] ""  SupportFront
 SG_ COB_ID_1400_01 m1 : 32|32@1+ (1,0) [128|4294967295] ""  SupportFront
 SG_ NrOfEntries_1400_00 m0 : 32|8@1+ (1,0) [2|5] ""  SupportFront
 SG_ SubIndex_1400 m5120M : 24|8@1+ (1,0) [0|2] ""  SupportFront
 SG_ Serial_number_1018_04 m4 : 32|32@1+ (1,0) [0|4294967295] ""  SupportFront
 SG_ Revision_number_1018_03 m3 : 32|32@1+ (1,0) [0|4294967295] ""  SupportFront
 SG_ Product_Code_1018_02 m2 : 32|32@1+ (1,0) [0|4294967295] ""  SupportFront
 SG_ Vendor_Id_1018_01 m1 : 32|32@1+ (1,0) [0|4294967295] ""  SupportFront
 SG_ number_of_entries_1018_00 m0 : 32|8@1+ (1,0) [1|4] ""  SupportFront
 SG_ SubIndex_1018 m4120M : 24|8@1+ (1,0) [0|4] ""  SupportFront
 SG_ Producer_Heartbeat_Time_1017 m0 : 32|16@1+ (1,0) [0|65535] ""  SupportFront
 SG_ SubIndex_1017 m4119M : 24|8@1+ (1,0) [0|0] ""  SupportFront
 SG_ Consumer_heartbeat_time_1016_7E m126 : 32|32@1+ (1,0) [0|4294967295] ""  SupportFront
 SG_ Consumer_heartbeat_time_1016_7D m125 : 32|32@1+ (1,0) [0|4294967295] ""  SupportFront
 SG_ Consumer_heartbeat_time_1016_7C m124 : 32|32@1+ (1,0) [0|4294967295] ""  SupportFront
 SG_ Consumer_heartbeat_time_1016_7B m123 : 32|32@1+ (1,0) [0|4294967295] ""  SupportFront
 SG_ Consumer_heartbeat_time_1016_7A m122 : 32|32@1+ (1,0) [0|4294967295] ""  SupportFront
 SG_ Consumer_heartbeat_time_1016_79 m121 : 32|32@1+ (1,0) [0|4294967295] ""  SupportFront
 SG_ Consumer_heartbeat_time_1016_78 m120 : 32|32@1+ (1,0) [0|4294967295] ""  SupportFront
 SG_ Consumer_heartbeat_time_1016_77 m119 : 32|32@1+ (1,0) [0|4294967295] ""  SupportFront
 SG_ Consumer_heartbeat_time_1016_76 m118 : 32|32@1+ (1,0) [0|4294967295] ""  SupportFront
 SG_ Consumer_heartbeat_time_1016_75 m117 : 32|32@1+ (1,0) [0|4294967295] ""  SupportFront
 SG_ Consumer_heartbeat_time_1016_74 m116 : 32|32@1+ (1,0) [0|4294967295] ""  SupportFront
 SG_ Consumer_heartbeat_time_1016_73 m115 : 32|32@1+ (1,0) [0|4294967295] ""  SupportFront
 SG_ Consumer_heartbeat_time_1016_72 m114 : 32|32@1+ (1,0) [0|4294967295] ""  SupportFront
 SG_ Consumer_heartbeat_time_1016_71 m113 : 32|32@1+ (1,0) [0|4294967295] ""  SupportFront
 SG_ Consumer_heartbeat_time_1016_70 m112 : 32|32@1+ (1,0) [0|4294967295] ""  SupportFront
 SG_ Consumer_heartbeat_time_1016_6F m111 : 32|32@1+ (1,0) [0|4294967295] ""  SupportFront
 SG_ Consumer_heartbeat_time_1016_6E m110 : 32|32@1+ (1,0) [0|4294967295] ""  SupportFront
 SG_ Consumer_heartbeat_time_1016_6D m109 : 32|32@1+ (1,0) [0|4294967295] ""  SupportFront
 SG_ Consumer_heartbeat_time_1016_6C m108 : 32|32@1+ (1,0) [0|4294967295] ""  SupportFront
 SG_ Consumer_heartbeat_time_1016_6B m107 : 32|32@1+ (1,0) [0|4294967295] ""  SupportFront
 SG_ Consumer_heartbeat_time_1016_6A m106 : 32|32@1+ (1,0) [0|4294967295] ""  SupportFront
 SG_ Consumer_heartbeat_time_1016_69 m105 : 32|32@1+ (1,0) [0|4294967295] ""  SupportFront
 SG_ Consumer_heartbeat_time_1016_68 m104 : 32|32@1+ (1,0) [0|4294967295] ""  SupportFront
 SG_ Consumer_heartbeat_time_1016_67 m103 : 32|32@1+ (1,0) [0|4294967295] ""  SupportFront
 SG_ Consumer_heartbeat_time_1016_66 m102 : 32|32@1+ (1,0) [0|4294967295] ""  SupportFront
 SG_ Consumer_heartbeat_time_1016_65 m101 : 32|32@1+ (1,0) [0|4294967295] ""  SupportFront
 SG_ Consumer_heartbeat_time_1016_64 m100 : 32|32@1+ (1,0) [0|4294967295] ""  SupportFront
 SG_ Consumer_heartbeat_time_1016_63 m99 : 32|32@1+ (1,0) [0|4294967295] ""  SupportFront
 SG_ Consumer_heartbeat_time_1016_62 m98 : 32|32@1+ (1,0) [0|4294967295] ""  SupportFront
 SG_ Consumer_heartbeat_time_1016_61 m97 : 32|32@1+ (1,0) [0|4294967295] ""  SupportFront
 SG_ Consumer_heartbeat_time_1016_60 m96 : 32|32@1+ (1,0) [0|4294967295] ""  SupportFront
 SG_ Consumer_heartbeat_time_1016_5F m95 : 32|32@1+ (1,0) [0|4294967295] ""  SupportFront
 SG_ Consumer_heartbeat_time_1016_5E m94 : 32|32@1+ (1,0) [0|4294967295] ""  SupportFront
 SG_ Consumer_heartbeat_time_1016_5D m93 : 32|32@1+ (1,0) [0|4294967295] ""  SupportFront
 SG_ Consumer_heartbeat_time_1016_5C m92 : 32|32@1+ (1,0) [0|4294967295] ""  SupportFront
 SG_ Consumer_heartbeat_time_1016_5B m91 : 32|32@1+ (1,0) [0|4294967295] ""  SupportFront
 SG_ Consumer_heartbeat_time_1016_5A m90 : 32|32@1+ (1,0) [0|4294967295] ""  SupportFront
 SG_ Consumer_heartbeat_time_1016_59 m89 : 32|32@1+ (1,0) [0|4294967295] ""  SupportFront
 SG_ Consumer_heartbeat_time_1016_58 m88 : 32|32@1+ (1,0) [0|4294967295] ""  SupportFront
 SG_ Consumer_heartbeat_time_1016_57 m87 : 32|32@1+ (1,0) [0|4294967295] ""  SupportFront
 SG_ Consumer_heartbeat_time_1016_56 m86 : 32|32@1+ (1,0) [0|4294967295] ""  SupportFront
 SG_ Consumer_heartbeat_time_1016_55 m85 : 32|32@1+ (1,0) [0|4294967295] ""  SupportFront
 SG_ Consumer_heartbeat_time_1016_54 m84 : 32|32@1+ (1,0) [0|4294967295] ""  SupportFront
 SG_ Consumer_heartbeat_time_1016_53 m83 : 32|32@1+ (1,0) [0|4294967295] ""  SupportFront
 SG_ Consumer_heartbeat_time_1016_52 m82 : 32|32@1+ (1,0) [0|4294967295] ""  SupportFront
 SG_ Consumer_heartbeat_time_1016_51 m81 : 32|32@1+ (1,0) [0|4294967295] ""  SupportFront
 SG_ Consumer_heartbeat_time_1016_50 m80 : 32|32@1+ (1,0) [0|4294967295] ""  SupportFront
 SG_ Consumer_heartbeat_time_1016_4F m79 : 32|32@1+ (1,0) [0|4294967295] ""  SupportFront
 SG_ Consumer_heartbeat_time_1016_4E m78 : 32|32@1+ (1,0) [0|4294967295] ""  SupportFront
 SG_ Consumer_heartbeat_time_1016_4D m77 : 32|32@1+ (1,0) [0|4294967295] ""  SupportFront
 SG_ Consumer_heartbeat_time_1016_4C m76 : 32|32@1+ (1,0) [0|4294967295] ""  SupportFront
 SG_ Consumer_heartbeat_time_1016_4B m75 : 32|32@1+ (1,0) [0|4294967295] ""  SupportFront
 SG_ Consumer_heartbeat_time_1016_4A m74 : 32|32@1+ (1,0) [0|4294967295] ""  SupportFront
 SG_ Consumer_heartbeat_time_1016_49 m73 : 32|32@1+ (1,0) [0|4294967295] ""  SupportFront
 SG_ Consumer_heartbeat_time_1016_48 m72 : 32|32@1+ (1,0) [0|4294967295] ""  SupportFront
 SG_ Consumer_heartbeat_time_1016_47 m71 : 32|32@1+ (1,0) [0|4294967295] ""  SupportFront
 SG_ Consumer_heartbeat_time_1016_46 m70 : 32|32@1+ (1,0) [0|4294967295] ""  SupportFront
 SG_ Consumer_heartbeat_time_1016_45 m69 : 32|32@1+ (1,0) [0|4294967295] ""  SupportFront
 SG_ Consumer_heartbeat_time_1016_44 m68 : 32|32@1+ (1,0) [0|4294967295] ""  SupportFront
 SG_ Consumer_heartbeat_time_1016_43 m67 : 32|32@1+ (1,0) [0|4294967295] ""  SupportFront
 SG_ Consumer_heartbeat_time_1016_42 m66 : 32|32@1+ (1,0) [0|4294967295] ""  SupportFront
 SG_ Consumer_heartbeat_time_1016_41 m65 : 32|32@1+ (1,0) [0|4294967295] ""  SupportFront
 SG_ Consumer_heartbeat_time_1016_40 m64 : 32|32@1+ (1,0) [0|4294967295] ""  SupportFront
 SG_ Consumer_heartbeat_time_1016_3F m63 : 32|32@1+ (1,0) [0|4294967295] ""  SupportFront
 SG_ Consumer_heartbeat_time_1016_3E m62 : 32|32@1+ (1,0) [0|4294967295] ""  SupportFront
 SG_ Consumer_heartbeat_time_1016_3D m61 : 32|32@1+ (1,0) [0|4294967295] ""  SupportFront
 SG_ Consumer_heartbeat_time_1016_3C m60 : 32|32@1+ (1,0) [0|4294967295] ""  SupportFront
 SG_ Consumer_heartbeat_time_1016_3B m59 : 32|32@1+ (1,0) [0|4294967295] ""  SupportFront
 SG_ Consumer_heartbeat_time_1016_3A m58 : 32|32@1+ (1,0) [0|4294967295] ""  SupportFront
 SG_ Consumer_heartbeat_time_1016_39 m57 : 32|32@1+ (1,0) [0|4294967295] ""  SupportFront
 SG_ Consumer_heartbeat_time_1016_38 m56 : 32|32@1+ (1,0) [0|4294967295] ""  SupportFront
 SG_ Consumer_heartbeat_time_1016_37 m55 : 32|32@1+ (1,0) [0|4294967295] ""  SupportFront
 SG_ Consumer_heartbeat_time_1016_36 m54 : 32|32@1+ (1,0) [0|4294967295] ""  SupportFront
 SG_ Consumer_heartbeat_time_1016_35 m53 : 32|32@1+ (1,0) [0|4294967295] ""  SupportFront
 SG_ Consumer_heartbeat_time_1016_34 m52 : 32|32@1+ (1,0) [0|4294967295] ""  SupportFront
 SG_ Consumer_heartbeat_time_1016_33 m51 : 32|32@1+ (1,0) [0|4294967295] ""  SupportFront
 SG_ Consumer_heartbeat_time_1016_32 m50 : 32|32@1+ (1,0) [0|4294967295] ""  SupportFront
 SG_ Consumer_heartbeat_time_1016_31 m49 : 32|32@1+ (1,0) [0|4294967295] ""  SupportFront
 SG_ Consumer_heartbeat_time_1016_30 m48 : 32|32@1+ (1,0) [0|4294967295] ""  SupportFront
 SG_ Consumer_heartbeat_time_1016_2F m47 : 32|32@1+ (1,0) [0|4294967295] ""  SupportFront
 SG_ Consumer_heartbeat_time_1016_2E m46 : 32|32@1+ (1,0) [0|4294967295] ""  SupportFront
 SG_ Consumer_heartbeat_time_1016_2D m45 : 32|32@1+ (1,0) [0|4294967295] ""  SupportFront
 SG_ Consumer_heartbeat_time_1016_2C m44 : 32|32@1+ (1,0) [0|4294967295] ""  SupportFront
 SG_ Consumer_heartbeat_time_1016_2B m43 : 32|32@1+ (1,0) [0|4294967295] ""  SupportFront
 SG_ Consumer_heartbeat_time_1016_2A m42 : 32|32@1+ (1,0) [0|4294967295] ""  SupportFront
 SG_ Consumer_heartbeat_time_1016_29 m41 : 32|32@1+ (1,0) [0|4294967295] ""  SupportFront
 SG_ Consumer_heartbeat_time_1016_28 m40 : 32|32@1+ (1,0) [0|4294967295] ""  SupportFront
 SG_ Consumer_heartbeat_time_1016_27 m39 : 32|32@1+ (1,0) [0|4294967295] ""  SupportFront
 SG_ Consumer_heartbeat_time_1016_26 m38 : 32|32@1+ (1,0) [0|4294967295] ""  SupportFront
 SG_ Consumer_heartbeat_time_1016_25 m37 : 32|32@1+ (1,0) [0|4294967295] ""  SupportFront
 SG_ Consumer_heartbeat_time_1016_24 m36 : 32|32@1+ (1,0) [0|4294967295] ""  SupportFront
 SG_ Consumer_heartbeat_time_1016_23 m35 : 32|32@1+ (1,0) [0|4294967295] ""  SupportFront
 SG_ Consumer_heartbeat_time_1016_22 m34 : 32|32@1+ (1,0) [0|4294967295] ""  SupportFront
 SG_ Consumer_heartbeat_time_1016_21 m33 : 32|32@1+ (1,0) [0|4294967295] ""  SupportFront
 SG_ Consumer_heartbeat_time_1016_20 m32 : 32|32@1+ (1,0) [0|4294967295] ""  SupportFront
 SG_ Consumer_heartbeat_time_1016_1F m31 : 32|32@1+ (1,0) [0|4294967295] ""  SupportFront
 SG_ Consumer_heartbeat_time_1016_1E m30 : 32|32@1+ (1,0) [0|4294967295] ""  SupportFront
 SG_ Consumer_heartbeat_time_1016_1D m29 : 32|32@1+ (1,0) [0|4294967295] ""  SupportFront
 SG_ Consumer_heartbeat_time_1016_1C m28 : 32|32@1+ (1,0) [0|4294967295] ""  SupportFront
 SG_ Consumer_heartbeat_time_1016_1B m27 : 32|32@1+ (1,0) [0|4294967295] ""  SupportFront
 SG_ Consumer_heartbeat_time_1016_1A m26 : 32|32@1+ (1,0) [0|4294967295] ""  SupportFront
 SG_ Consumer_heartbeat_time_1016_19 m25 : 32|32@1+ (1,0) [0|4294967295] ""  SupportFront
 SG_ Consumer_heartbeat_time_1016_18 m24 : 32|32@1+ (1,0) [0|4294967295] ""  SupportFront
 SG_ Consumer_heartbeat_time_1016_17 m23 : 32|32@1+ (1,0) [0|4294967295] ""  SupportFront
 SG_ Consumer_heartbeat_time_1016_16 m22 : 32|32@1+ (1,0) [0|4294967295] ""  SupportFront
 SG_ Consumer_heartbeat_time_1016_15 m21 : 32|32@1+ (1,0) [0|4294967295] ""  SupportFront
 SG_ Consumer_heartbeat_time_1016_14 m20 : 32|32@1+ (1,0) [0|4294967295] ""  SupportFront
 SG_ Consumer_heartbeat_time_1016_13 m19 : 32|32@1+ (1,0) [0|4294967295] ""  SupportFront
 SG_ Consumer_heartbeat_time_1016_12 m18 : 32|32@1+ (1,0) [0|4294967295] ""  SupportFront
 SG_ Consumer_heartbeat_time_1016_11 m17 : 32|32@1+ (1,0) [0|4294967295] ""  SupportFront
 SG_ Consumer_heartbeat_time_1016_10 m16 : 32|32@1+ (1,0) [0|4294967295] ""  SupportFront
 SG_ Consumer_heartbeat_time_1016_0F m15 : 32|32@1+ (1,0) [0|4294967295] ""  SupportFront
 SG_ Consumer_heartbeat_time_1016_0E m14 : 32|32@1+ (1,0) [0|4294967295] ""  SupportFront
 SG_ Consumer_heartbeat_time_1016_0D m13 : 32|32@1+ (1,0) [0|4294967295] ""  SupportFront
 SG_ Consumer_heartbeat_time_1016_0C m12 : 32|32@1+ (1,0) [0|4294967295] ""  SupportFront
 SG_ Consumer_heartbeat_time_1016_0B m11 : 32|32@1+ (1,0) [0|4294967295] ""  SupportFront
 SG_ Consumer_heartbeat_time_1016_0A m10 : 32|32@1+ (1,0) [0|4294967295] ""  SupportFront
 SG_ Consumer_Heartbeat_Time_1016_09 m9 : 32|32@1+ (1,0) [0|4294967295] ""  SupportFront
 SG_ Consumer_Heartbeat_Time_1016_08 m8 : 32|32@1+ (1,0) [0|4294967295] ""  SupportFront
 SG_ Consumer_Heartbeat_Time_1016_07 m7 : 32|32@1+ (1,0) [0|4294967295] ""  SupportFront
 SG_ Consumer_Heartbeat_Time_1016_06 m6 : 32|32@1+ (1,0) [0|4294967295] ""  SupportFront
 SG_ Consumer_Heartbeat_Time_1016_05 m5 : 32|32@1+ (1,0) [0|4294967295] ""  SupportFront
 SG_ Consumer_Heartbeat_Time_1016_04 m4 : 32|32@1+ (1,0) [0|4294967295] ""  SupportFront
 SG_ Consumer_Heartbeat_Time_1016_03 m3 : 32|32@1+ (1,0) [0|4294967295] ""  SupportFront
 SG_ Consumer_Heartbeat_Time_1016_02 m2 : 32|32@1+ (1,0) [0|4294967295] ""  SupportFront
 SG_ Consumer_Heartbeat_Time_1016_01 m1 : 32|32@1+ (1,0) [0|4294967295] ""  SupportFront
 SG_ Highest_sub_index_supported_0000 m0 : 32|8@1+ (1,0) [0|255] ""  SupportFront
 SG_ SubIndex_1016 m4118M : 24|8@1+ (1,0) [0|126] ""  SupportFront
 SG_ Save_all_Parameters_1010_01 m1 : 32|32@1+ (1,0) [0|4294967295] ""  SupportFront
 SG_ Number_of_Entries_1010_00 m0 : 32|8@1+ (1,0) [0|255] ""  SupportFront
 SG_ SubIndex_1010 m4112M : 24|8@1+ (1,0) [0|1] ""  SupportFront
 SG_ Life_Time_Factor_100D m0 : 32|8@1+ (1,0) [0|255] ""  SupportFront
 SG_ SubIndex_100D m4109M : 24|8@1+ (1,0) [0|0] ""  SupportFront
 SG_ Guard_Time_100C m0 : 32|16@1+ (1,0) [0|65535] ""  SupportFront
 SG_ SubIndex_100C m4108M : 24|8@1+ (1,0) [0|0] ""  SupportFront
 SG_ Sync_Window_Length_1007 m0 : 32|32@1+ (1,0) [0|4294967295] ""  SupportFront
 SG_ SubIndex_1007 m4103M : 24|8@1+ (1,0) [0|0] ""  SupportFront
 SG_ Communication_Cycle_Period_1006 m0 : 32|32@1+ (1,0) [0|4294967295] ""  SupportFront
 SG_ SubIndex_1006 m4102M : 24|8@1+ (1,0) [0|0] ""  SupportFront
 SG_ COB_ID_SYNC_1005 m0 : 32|32@1+ (1,0) [128|4294967295] ""  SupportFront
 SG_ SubIndex_1005 m4101M : 24|8@1+ (1,0) [0|0] ""  SupportFront
 SG_ Manufacturer_Status_Registe_0006 m0 : 32|32@1+ (1,0) [0|4294967295] ""  SupportFront
 SG_ SubIndex_1002 m4098M : 24|8@1+ (1,0) [0|0] ""  SupportFront
 SG_ Error_Register_1001 m0 : 32|8@1+ (1,0) [0|255] ""  SupportFront
 SG_ SubIndex_1001 m4097M : 24|8@1+ (1,0) [0|0] ""  SupportFront
 SG_ Device_Type_1000 m0 : 32|32@1+ (1,0) [0|4294967295] ""  SupportFront
 SG_ SubIndex_1000 m4096M : 24|8@1+ (1,0) [0|0] ""  SupportFront
 SG_ Index m1M : 8|16@1+ (1,0) [4096|25861] ""  SupportFront
 SG_ TransferType m1M : 1|1@1+ (1,0) [0|1] ""  SupportFront
 SG_ NotUsedBytes m1 : 2|2@1+ (1,0) [0|3] ""  SupportFront
 SG_ SizeIndicator m1 : 0|1@1+ (1,0) [0|1] ""  SupportFront
 SG_ CCS M : 5|3@1+ (1,0) [0|6] ""  SupportFront

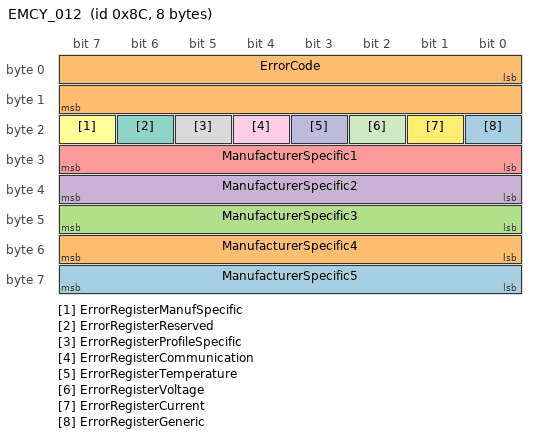
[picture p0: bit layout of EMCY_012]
BO_ 140 EMCY_012: 8 SupportFront
 SG_ ManufacturerSpecific5 : 56|8@1+ (1,0) [0|0] "" Vector__XXX
 SG_ ManufacturerSpecific4 : 48|8@1+ (1,0) [0|0] "" Vector__XXX
 SG_ ManufacturerSpecific3 : 40|8@1+ (1,0) [0|0] "" Vector__XXX
 SG_ ManufacturerSpecific2 : 32|8@1+ (1,0) [0|0] "" Vector__XXX
 SG_ ManufacturerSpecific1 : 24|8@1+ (1,0) [0|0] "" Vector__XXX
 SG_ ErrorRegisterManufSpecific : 23|1@1+ (1,0) [0|0] "" Vector__XXX
 SG_ ErrorRegisterReserved : 22|1@1+ (1,0) [0|0] "" Vector__XXX
 SG_ ErrorRegisterProfileSpecific : 21|1@1+ (1,0) [0|0] "" Vector__XXX
 SG_ ErrorRegisterCommunication : 20|1@1+ (1,0) [0|0] "" Vector__XXX
 SG_ ErrorRegisterTemperature : 19|1@1+ (1,0) [0|0] "" Vector__XXX
 SG_ ErrorRegisterVoltage : 18|1@1+ (1,0) [0|0] "" Vector__XXX
 SG_ ErrorRegisterCurrent : 17|1@1+ (1,0) [0|0] "" Vector__XXX
 SG_ ErrorRegisterGeneric : 16|1@1+ (1,0) [0|0] "" Vector__XXX
 SG_ ErrorCode : 0|16@1+ (1,0) [0|0] "" Vector__XXX

BO_ 1805 HBGuard_013: 1 SupportRear
 SG_ Toggle : 7|1@1+ (1,0) [0|0] "" Vector__XXX
 SG_ State : 0|7@1+ (1,0) [0|0] "" Vector__XXX

BA_DEF_ BO_  "GenMsgSendType" ENUM  "Cyclic","SendType1","SendType2","SendType3","SendType4","SendType5","SendType6","SendType7","SendType8","SendType9";
BA_DEF_ BO_  "GenMsgCycleTime" INT 0 0;
BA_DEF_ SG_  "GenSigStartValue" INT 0 0;
BA_DEF_ BO_  "CO_MsgCategory" INT 0 0;
BA_DEF_ SG_  "SystemSignalLongSymbol" STRING ;
BA_DEF_DEF_  "GenMsgSendType" "";
BA_DEF_DEF_  "GenMsgCycleTime" 0;
BA_DEF_DEF_  "GenSigStartValue" 0;
BA_DEF_DEF_  "CO_MsgCategory" 0;
BA_DEF_DEF_  "SystemSignalLongSymbol" "";
BA_ "CO_MsgCategory" BO_ 1420 410;
BA_ "CO_MsgCategory" BO_ 1548 405;
BA_ "CO_MsgCategory" BO_ 140 205;
BA_ "GenMsgSendType" BO_ 1805 0;
BA_ "GenMsgCycleTime" BO_ 1805 1000;
BA_ "CO_MsgCategory" BO_ 1805 505;
BA_ "GenSigStartValue" SG_ 1420 supported_drive_modes_6502 2;
BA_ "GenSigStartValue" SG_ 1420 motor_service_period_6407 1000;
BA_ "GenSigStartValue" SG_ 1420 NrOfObjects_60FE_00 2;
BA_ "SystemSignalLongSymbol" SG_ 1420 disable_operation_option_co_0001 "disable_operation_option_code_605C";
BA_ "GenSigStartValue" SG_ 1420 delta_time_6049_02 1;
BA_ "GenSigStartValue" SG_ 1420 delta_speed_6049_01 1000;
BA_ "GenSigStartValue" SG_ 1420 NrOfObjects_6049_00 2;
BA_ "GenSigStartValue" SG_ 1420 delta_time_6048_02 1;
BA_ "GenSigStartValue" SG_ 1420 delta_speed_6048_01 500;
BA_ "GenSigStartValue" SG_ 1420 NrOfObjects_6048_00 2;
BA_ "GenSigStartValue" SG_ 1420 vl_velocity_max_amount_6046_02 1000;
BA_ "GenSigStartValue" SG_ 1420 vl_velocity_min_max_amount__0001 2;
BA_ "SystemSignalLongSymbol" SG_ 1420 vl_velocity_min_max_amount__0001 "vl_velocity_min_max_amount_highest_subindex_6046_00";
BA_ "SystemSignalLongSymbol" SG_ 1420 abort_connection_option_cod_0001 "abort_connection_option_code_6007";
BA_ "GenSigStartValue" SG_ 1420 mappedObj2_1A00_02 1615003664;
BA_ "GenSigStartValue" SG_ 1420 mappedObj1_1A00_01 1614872592;
BA_ "GenSigStartValue" SG_ 1420 NrOfMappedObjects_1A00_00 3;
BA_ "GenSigStartValue" SG_ 1420 TransmissionType_1806_02 255;
BA_ "GenSigStartValue" SG_ 1420 COB_ID_1806_01 2147484966;
BA_ "GenSigStartValue" SG_ 1420 NrOfEntries_1806_00 5;
BA_ "GenSigStartValue" SG_ 1420 TransmissionType_1805_02 255;
BA_ "GenSigStartValue" SG_ 1420 COB_ID_1805_01 2147484967;
BA_ "GenSigStartValue" SG_ 1420 NrOfEntries_1805_00 5;
BA_ "GenSigStartValue" SG_ 1420 TransmissionType_1804_02 255;
BA_ "GenSigStartValue" SG_ 1420 COB_ID_1804_01 2147484968;
BA_ "GenSigStartValue" SG_ 1420 NrOfEntries_1804_00 5;
BA_ "GenSigStartValue" SG_ 1420 TransmissionType_1803_02 255;
BA_ "GenSigStartValue" SG_ 1420 COB_ID_1803_01 2147484812;
BA_ "GenSigStartValue" SG_ 1420 NrOfEntries_1803_00 5;
BA_ "GenSigStartValue" SG_ 1420 TransmissionType_1802_02 255;
BA_ "GenSigStartValue" SG_ 1420 COB_ID_1802_01 2147484556;
BA_ "GenSigStartValue" SG_ 1420 NrOfEntries_1802_00 5;
BA_ "GenSigStartValue" SG_ 1420 TransmissionType_1801_02 255;
BA_ "GenSigStartValue" SG_ 1420 COB_ID_1801_01 2147484300;
BA_ "GenSigStartValue" SG_ 1420 NrOfEntries_1801_00 5;
BA_ "GenSigStartValue" SG_ 1420 TransmissionType_1800_02 255;
BA_ "GenSigStartValue" SG_ 1420 COB_ID_1800_01 1025;
BA_ "GenSigStartValue" SG_ 1420 NrOfEntries_1800_00 5;
BA_ "GenSigStartValue" SG_ 1420 mappedObj2_1600_02 1614807056;
BA_ "GenSigStartValue" SG_ 1420 mappedObj1_1600_01 1614938128;
BA_ "GenSigStartValue" SG_ 1420 NrOfMappedObjects_1600_00 2;
BA_ "GenSigStartValue" SG_ 1420 TransmissionType_1407_02 255;
BA_ "GenSigStartValue" SG_ 1420 COB_ID_1407_01 2147484962;
BA_ "GenSigStartValue" SG_ 1420 NrOfEntries_1407_00 2;
BA_ "GenSigStartValue" SG_ 1420 TransmissionType_1406_02 255;
BA_ "GenSigStartValue" SG_ 1420 COB_ID_1406_01 2147484963;
BA_ "GenSigStartValue" SG_ 1420 NrOfEntries_1406_00 2;
BA_ "GenSigStartValue" SG_ 1420 TransmissionType_1405_02 255;
BA_ "GenSigStartValue" SG_ 1420 COB_ID_1405_01 2147484964;
BA_ "GenSigStartValue" SG_ 1420 NrOfEntries_1405_00 2;
BA_ "GenSigStartValue" SG_ 1420 TransmissionType_1404_02 255;
BA_ "GenSigStartValue" SG_ 1420 COB_ID_1404_01 2147484965;
BA_ "GenSigStartValue" SG_ 1420 NrOfEntries_1404_00 2;
BA_ "GenSigStartValue" SG_ 1420 TransmissionType_1403_02 255;
BA_ "GenSigStartValue" SG_ 1420 COB_ID_1403_01 2147484940;
BA_ "GenSigStartValue" SG_ 1420 NrOfEntries_1403_00 2;
BA_ "GenSigStartValue" SG_ 1420 TransmissionType_1402_02 255;
BA_ "GenSigStartValue" SG_ 1420 COB_ID_1402_01 2147484684;
BA_ "GenSigStartValue" SG_ 1420 NrOfEntries_1402_00 2;
BA_ "GenSigStartValue" SG_ 1420 TransmissionType_1401_02 255;
BA_ "GenSigStartValue" SG_ 1420 COB_ID_1401_01 2147484428;
BA_ "GenSigStartValue" SG_ 1420 NrOfEntries_1401_00 2;
BA_ "GenSigStartValue" SG_ 1420 TransmissionType_1400_02 255;
BA_ "GenSigStartValue" SG_ 1420 COB_ID_1400_01 641;
BA_ "GenSigStartValue" SG_ 1420 NrOfEntries_1400_00 2;
BA_ "GenSigStartValue" SG_ 1420 Serial_number_1018_04 1;
BA_ "GenSigStartValue" SG_ 1420 Revision_number_1018_03 1;
BA_ "GenSigStartValue" SG_ 1420 Product_Code_1018_02 1;
BA_ "GenSigStartValue" SG_ 1420 Vendor_Id_1018_01 1;
BA_ "GenSigStartValue" SG_ 1420 number_of_entries_1018_00 4;
BA_ "GenSigStartValue" SG_ 1420 Producer_Heartbeat_Time_1017 1000;
BA_ "GenSigStartValue" SG_ 1420 Highest_sub_index_supported_1016 126;
BA_ "SystemSignalLongSymbol" SG_ 1420 Highest_sub_index_supported_1016 "Highest_sub_index_supported_1016_00";
BA_ "GenSigStartValue" SG_ 1420 Number_of_Entries_1010_00 1;
BA_ "GenSigStartValue" SG_ 1420 Sync_Window_Length_1007 100;
BA_ "GenSigStartValue" SG_ 1420 Communication_Cycle_Period_1006 200000;
BA_ "GenSigStartValue" SG_ 1420 COB_ID_SYNC_1005 2147483776;
BA_ "SystemSignalLongSymbol" SG_ 1420 Manufacturer_Status_Registe_0005 "Manufacturer_Status_Register_1002";
BA_ "GenSigStartValue" SG_ 1420 Device_Type_1000 402;
BA_ "GenSigStartValue" SG_ 1420 Index 4096;
BA_ "GenSigStartValue" SG_ 1548 supported_drive_modes_6502 2;
BA_ "GenSigStartValue" SG_ 1548 motor_service_period_6407 1000;
BA_ "GenSigStartValue" SG_ 1548 NrOfObjects_60FE_00 2;
BA_ "SystemSignalLongSymbol" SG_ 1548 disable_operation_option_co_0002 "disable_operation_option_code_605C";
BA_ "GenSigStartValue" SG_ 1548 delta_time_6049_02 1;
BA_ "GenSigStartValue" SG_ 1548 delta_speed_6049_01 1000;
BA_ "GenSigStartValue" SG_ 1548 NrOfObjects_6049_00 2;
BA_ "GenSigStartValue" SG_ 1548 delta_time_6048_02 1;
BA_ "GenSigStartValue" SG_ 1548 delta_speed_6048_01 500;
BA_ "GenSigStartValue" SG_ 1548 NrOfObjects_6048_00 2;
BA_ "GenSigStartValue" SG_ 1548 vl_velocity_max_amount_6046_02 1000;
BA_ "GenSigStartValue" SG_ 1548 vl_velocity_min_max_amount__0002 2;
BA_ "SystemSignalLongSymbol" SG_ 1548 vl_velocity_min_max_amount__0002 "vl_velocity_min_max_amount_highest_subindex_6046_00";
BA_ "SystemSignalLongSymbol" SG_ 1548 abort_connection_option_cod_0002 "abort_connection_option_code_6007";
BA_ "GenSigStartValue" SG_ 1548 mappedObj2_1A00_02 1615003664;
BA_ "GenSigStartValue" SG_ 1548 mappedObj1_1A00_01 1614872592;
BA_ "GenSigStartValue" SG_ 1548 NrOfMappedObjects_1A00_00 3;
BA_ "GenSigStartValue" SG_ 1548 TransmissionType_1806_02 255;
BA_ "GenSigStartValue" SG_ 1548 COB_ID_1806_01 2147484966;
BA_ "GenSigStartValue" SG_ 1548 NrOfEntries_1806_00 5;
BA_ "GenSigStartValue" SG_ 1548 TransmissionType_1805_02 255;
BA_ "GenSigStartValue" SG_ 1548 COB_ID_1805_01 2147484967;
BA_ "GenSigStartValue" SG_ 1548 NrOfEntries_1805_00 5;
BA_ "GenSigStartValue" SG_ 1548 TransmissionType_1804_02 255;
BA_ "GenSigStartValue" SG_ 1548 COB_ID_1804_01 2147484968;
BA_ "GenSigStartValue" SG_ 1548 NrOfEntries_1804_00 5;
BA_ "GenSigStartValue" SG_ 1548 TransmissionType_1803_02 255;
BA_ "GenSigStartValue" SG_ 1548 COB_ID_1803_01 2147484812;
BA_ "GenSigStartValue" SG_ 1548 NrOfEntries_1803_00 5;
BA_ "GenSigStartValue" SG_ 1548 TransmissionType_1802_02 255;
BA_ "GenSigStartValue" SG_ 1548 COB_ID_1802_01 2147484556;
BA_ "GenSigStartValue" SG_ 1548 NrOfEntries_1802_00 5;
BA_ "GenSigStartValue" SG_ 1548 TransmissionType_1801_02 255;
BA_ "GenSigStartValue" SG_ 1548 COB_ID_1801_01 2147484300;
BA_ "GenSigStartValue" SG_ 1548 NrOfEntries_1801_00 5;
BA_ "GenSigStartValue" SG_ 1548 TransmissionType_1800_02 255;
BA_ "GenSigStartValue" SG_ 1548 COB_ID_1800_01 1025;
BA_ "GenSigStartValue" SG_ 1548 NrOfEntries_1800_00 5;
BA_ "GenSigStartValue" SG_ 1548 mappedObj2_1600_02 1614807056;
BA_ "GenSigStartValue" SG_ 1548 mappedObj1_1600_01 1614938128;
BA_ "GenSigStartValue" SG_ 1548 NrOfMappedObjects_1600_00 2;
BA_ "GenSigStartValue" SG_ 1548 TransmissionType_1407_02 255;
BA_ "GenSigStartValue" SG_ 1548 COB_ID_1407_01 2147484962;
BA_ "GenSigStartValue" SG_ 1548 NrOfEntries_1407_00 2;
BA_ "GenSigStartValue" SG_ 1548 TransmissionType_1406_02 255;
BA_ "GenSigStartValue" SG_ 1548 COB_ID_1406_01 2147484963;
BA_ "GenSigStartValue" SG_ 1548 NrOfEntries_1406_00 2;
BA_ "GenSigStartValue" SG_ 1548 TransmissionType_1405_02 255;
BA_ "GenSigStartValue" SG_ 1548 COB_ID_1405_01 2147484964;
BA_ "GenSigStartValue" SG_ 1548 NrOfEntries_1405_00 2;
BA_ "GenSigStartValue" SG_ 1548 TransmissionType_1404_02 255;
BA_ "GenSigStartValue" SG_ 1548 COB_ID_1404_01 2147484965;
BA_ "GenSigStartValue" SG_ 1548 NrOfEntries_1404_00 2;
BA_ "GenSigStartValue" SG_ 1548 TransmissionType_1403_02 255;
BA_ "GenSigStartValue" SG_ 1548 COB_ID_1403_01 2147484940;
BA_ "GenSigStartValue" SG_ 1548 NrOfEntries_1403_00 2;
BA_ "GenSigStartValue" SG_ 1548 TransmissionType_1402_02 255;
BA_ "GenSigStartValue" SG_ 1548 COB_ID_1402_01 2147484684;
BA_ "GenSigStartValue" SG_ 1548 NrOfEntries_1402_00 2;
BA_ "GenSigStartValue" SG_ 1548 TransmissionType_1401_02 255;
BA_ "GenSigStartValue" SG_ 1548 COB_ID_1401_01 2147484428;
BA_ "GenSigStartValue" SG_ 1548 NrOfEntries_1401_00 2;
BA_ "GenSigStartValue" SG_ 1548 TransmissionType_1400_02 255;
BA_ "GenSigStartValue" SG_ 1548 COB_ID_1400_01 641;
BA_ "GenSigStartValue" SG_ 1548 NrOfEntries_1400_00 2;
BA_ "GenSigStartValue" SG_ 1548 Serial_number_1018_04 1;
BA_ "GenSigStartValue" SG_ 1548 Revision_number_1018_03 1;
BA_ "GenSigStartValue" SG_ 1548 Product_Code_1018_02 1;
BA_ "GenSigStartValue" SG_ 1548 Vendor_Id_1018_01 1;
BA_ "GenSigStartValue" SG_ 1548 number_of_entries_1018_00 4;
BA_ "GenSigStartValue" SG_ 1548 Producer_Heartbeat_Time_1017 1000;
BA_ "GenSigStartValue" SG_ 1548 Highest_sub_index_supported_0000 126;
BA_ "SystemSignalLongSymbol" SG_ 1548 Highest_sub_index_supported_0000 "Highest_sub_index_supported_1016_00";
BA_ "GenSigStartValue" SG_ 1548 Number_of_Entries_1010_00 1;
BA_ "GenSigStartValue" SG_ 1548 Sync_Window_Length_1007 100;
BA_ "GenSigStartValue" SG_ 1548 Communication_Cycle_Period_1006 200000;
BA_ "GenSigStartValue" SG_ 1548 COB_ID_SYNC_1005 2147483776;
BA_ "SystemSignalLongSymbol" SG_ 1548 Manufacturer_Status_Registe_0006 "Manufacturer_Status_Register_1002";
BA_ "GenSigStartValue" SG_ 1548 Device_Type_1000 402;
BA_ "GenSigStartValue" SG_ 1548 Index 4096;
VAL_ 1420 SubIndex_6502 0 "supported_drive_modes" ;
VAL_ 1420 SubIndex_6407 0 "motor_service_period" ;
VAL_ 1420 SubIndex_6402 0 "motor_type" ;
VAL_ 1420 SubIndex_60FE 2 "bitmask" 1 "physical_outputs" 0 "NrOfObjects" ;
VAL_ 1420 SubIndex_60FD 0 "digital_inputs" ;
VAL_ 1420 SubIndex_607E 0 "polarity" ;
VAL_ 1420 SubIndex_6067 0 "position_window" ;
VAL_ 1420 SubIndex_6064 0 "position_actual_value" ;
VAL_ 1420 SubIndex_6063 0 "position_actual_value" ;
VAL_ 1420 SubIndex_6062 0 "position_demand_value" ;
VAL_ 1420 SubIndex_6061 0 "modes_of_operation_display" ;
VAL_ 1420 SubIndex_6060 0 "modes_of_operation" ;
VAL_ 1420 SubIndex_605E 0 "fault_reaction_option_code" ;
VAL_ 1420 SubIndex_605D 0 "stop_option_code" ;
VAL_ 1420 SubIndex_605C 0 "disable_operation_option_code" ;
VAL_ 1420 SubIndex_605B 0 "shutdown_option_code" ;
VAL_ 1420 SubIndex_605A 0 "quick_stop_option_code" ;
VAL_ 1420 SubIndex_6049 2 "delta_time" 1 "delta_speed" 0 "NrOfObjects" ;
VAL_ 1420 SubIndex_6048 2 "delta_time" 1 "delta_speed" 0 "NrOfObjects" ;
VAL_ 1420 SubIndex_6046 2 "vl_velocity_max_amount" 1 "vl_velocity_min_amount" 0 "vl_velocity_min_max_amount_highest_subindex" ;
VAL_ 1420 SubIndex_6044 0 "vl_control_effort" ;
VAL_ 1420 SubIndex_6043 0 "vl_velocity_demand" ;
VAL_ 1420 SubIndex_6042 0 "vl_target_velocity" ;
VAL_ 1420 SubIndex_6041 0 "statusword" ;
VAL_ 1420 SubIndex_6040 0 "controlword" ;
VAL_ 1420 SubIndex_603F 0 "error_code" ;
VAL_ 1420 SubIndex_6007 0 "abort_connection_option_code" ;
VAL_ 1420 SubIndex_1A06 0 "NrOfMappedObjects" ;
VAL_ 1420 SubIndex_1A05 0 "NrOfMappedObjects" ;
VAL_ 1420 SubIndex_1A04 0 "NrOfMappedObjects" ;
VAL_ 1420 SubIndex_1A03 0 "NrOfMappedObjects" ;
VAL_ 1420 SubIndex_1A02 0 "NrOfMappedObjects" ;
VAL_ 1420 SubIndex_1A01 0 "NrOfMappedObjects" ;
VAL_ 1420 SubIndex_1A00 2 "mappedObj2" 1 "mappedObj1" 0 "NrOfMappedObjects" ;
VAL_ 1420 SubIndex_1806 5 "EventTimer" 2 "TransmissionType" 1 "COB-ID" 0 "NrOfEntries" ;
VAL_ 1420 SubIndex_1805 5 "EventTimer" 2 "TransmissionType" 1 "COB-ID" 0 "NrOfEntries" ;
VAL_ 1420 SubIndex_1804 5 "EventTimer" 2 "TransmissionType" 1 "COB-ID" 0 "NrOfEntries" ;
VAL_ 1420 SubIndex_1803 5 "EventTimer" 2 "TransmissionType" 1 "COB-ID" 0 "NrOfEntries" ;
VAL_ 1420 SubIndex_1802 5 "EventTimer" 2 "TransmissionType" 1 "COB-ID" 0 "NrOfEntries" ;
VAL_ 1420 SubIndex_1801 5 "EventTimer" 2 "TransmissionType" 1 "COB-ID" 0 "NrOfEntries" ;
VAL_ 1420 SubIndex_1800 5 "EventTimer" 2 "TransmissionType" 1 "COB-ID" 0 "NrOfEntries" ;
VAL_ 1420 SubIndex_1607 0 "NrOfMappedObjects" ;
VAL_ 1420 SubIndex_1606 0 "NrOfMappedObjects" ;
VAL_ 1420 SubIndex_1605 0 "NrOfMappedObjects" ;
VAL_ 1420 SubIndex_1604 0 "NrOfMappedObjects" ;
VAL_ 1420 SubIndex_1603 0 "NrOfMappedObjects" ;
VAL_ 1420 SubIndex_1602 0 "NrOfMappedObjects" ;
VAL_ 1420 SubIndex_1601 0 "NrOfMappedObjects" ;
VAL_ 1420 SubIndex_1600 2 "mappedObj2" 1 "mappedObj1" 0 "NrOfMappedObjects" ;
VAL_ 1420 SubIndex_1407 2 "TransmissionType" 1 "COB-ID" 0 "NrOfEntries" ;
VAL_ 1420 SubIndex_1406 2 "TransmissionType" 1 "COB-ID" 0 "NrOfEntries" ;
VAL_ 1420 SubIndex_1405 2 "TransmissionType" 1 "COB-ID" 0 "NrOfEntries" ;
VAL_ 1420 SubIndex_1404 2 "TransmissionType" 1 "COB-ID" 0 "NrOfEntries" ;
VAL_ 1420 SubIndex_1403 2 "TransmissionType" 1 "COB-ID" 0 "NrOfEntries" ;
VAL_ 1420 SubIndex_1402 2 "TransmissionType" 1 "COB-ID" 0 "NrOfEntries" ;
VAL_ 1420 SubIndex_1401 2 "TransmissionType" 1 "COB-ID" 0 "NrOfEntries" ;
VAL_ 1420 SubIndex_1400 2 "TransmissionType" 1 "COB-ID" 0 "NrOfEntries" ;
VAL_ 1420 SubIndex_1018 4 "Serial number" 3 "Revision number" 2 "Product Code" 1 "Vendor Id" 0 "number of entries" ;
VAL_ 1420 SubIndex_1017 0 "Producer Heartbeat Time" ;
VAL_ 1420 SubIndex_1016 126 "Consumer heartbeat time" 125 "Consumer heartbeat time" 124 "Consumer heartbeat time" 123 "Consumer heartbeat time" 122 "Consumer heartbeat time" 121 "Consumer heartbeat time" 120 "Consumer heartbeat time" 119 "Consumer heartbeat time" 118 "Consumer heartbeat time" 117 "Consumer heartbeat time" 116 "Consumer heartbeat time" 115 "Consumer heartbeat time" 114 "Consumer heartbeat time" 113 "Consumer heartbeat time" 112 "Consumer heartbeat time" 111 "Consumer heartbeat time" 110 "Consumer heartbeat time" 109 "Consumer heartbeat time" 108 "Consumer heartbeat time" 107 "Consumer heartbeat time" 106 "Consumer heartbeat time" 105 "Consumer heartbeat time" 104 "Consumer heartbeat time" 103 "Consumer heartbeat time" 102 "Consumer heartbeat time" 101 "Consumer heartbeat time" 100 "Consumer heartbeat time" 99 "Consumer heartbeat time" 98 "Consumer heartbeat time" 97 "Consumer heartbeat time" 96 "Consumer heartbeat time" 95 "Consumer heartbeat time" 94 "Consumer heartbeat time" 93 "Consumer heartbeat time" 92 "Consumer heartbeat time" 91 "Consumer heartbeat time" 90 "Consumer heartbeat time" 89 "Consumer heartbeat time" 88 "Consumer heartbeat time" 87 "Consumer heartbeat time" 86 "Consumer heartbeat time" 85 "Consumer heartbeat time" 84 "Consumer heartbeat time" 83 "Consumer heartbeat time" 82 "Consumer heartbeat time" 81 "Consumer heartbeat time" 80 "Consumer heartbeat time" 79 "Consumer heartbeat time" 78 "Consumer heartbeat time" 77 "Consumer heartbeat time" 76 "Consumer heartbeat time" 75 "Consumer heartbeat time" 74 "Consumer heartbeat time" 73 "Consumer heartbeat time" 72 "Consumer heartbeat time" 71 "Consumer heartbeat time" 70 "Consumer heartbeat time" 69 "Consumer heartbeat time" 68 "Consumer heartbeat time" 67 "Consumer heartbeat time" 66 "Consumer heartbeat time" 65 "Consumer heartbeat time" 64 "Consumer heartbeat time" 63 "Consumer heartbeat time" 62 "Consumer heartbeat time" 61 "Consumer heartbeat time" 60 "Consumer heartbeat time" 59 "Consumer heartbeat time" 58 "Consumer heartbeat time" 57 "Consumer heartbeat time" 56 "Consumer heartbeat time" 55 "Consumer heartbeat time" 54 "Consumer heartbeat time" 53 "Consumer heartbeat time" 52 "Consumer heartbeat time" 51 "Consumer heartbeat time" 50 "Consumer heartbeat time" 49 "Consumer heartbeat time" 48 "Consumer heartbeat time" 47 "Consumer heartbeat time" 46 "Consumer heartbeat time" 45 "Consumer heartbeat time" 44 "Consumer heartbeat time" 43 "Consumer heartbeat time" 42 "Consumer heartbeat time" 41 "Consumer heartbeat time" 40 "Consumer heartbeat time" 39 "Consumer heartbeat time" 38 "Consumer heartbeat time" 37 "Consumer heartbeat time" 36 "Consumer heartbeat time" 35 "Consumer heartbeat time" 34 "Consumer heartbeat time" 33 "Consumer heartbeat time" 32 "Consumer heartbeat time" 31 "Consumer heartbeat time" 30 "Consumer heartbeat time" 29 "Consumer heartbeat time" 28 "Consumer heartbeat time" 27 "Consumer heartbeat time" 26 "Consumer heartbeat time" 25 "Consumer heartbeat time" 24 "Consumer heartbeat time" 23 "Consumer heartbeat time" 22 "Consumer heartbeat time" 21 "Consumer heartbeat time" 20 "Consumer heartbeat time" 19 "Consumer heartbeat time" 18 "Consumer heartbeat time" 17 "Consumer heartbeat time" 16 "Consumer heartbeat time" 15 "Consumer heartbeat time" 14 "Consumer heartbeat time" 13 "Consumer heartbeat time" 12 "Consumer heartbeat time" 11 "Consumer heartbeat time" 10 "Consumer heartbeat time" 9 "Consumer Heartbeat Time" 8 "Consumer Heartbeat Time" 7 "Consumer Heartbeat Time" 6 "Consumer Heartbeat Time" 5 "Consumer Heartbeat Time" 4 "Consumer Heartbeat Time" 3 "Consumer Heartbeat Time" 2 "Consumer Heartbeat Time" 1 "Consumer Heartbeat Time" 0 "Highest sub-index supported" ;
VAL_ 1420 SubIndex_1010 1 "Save all Parameters" 0 "Number of Entries" ;
VAL_ 1420 SubIndex_100D 0 "Life Time Factor" ;
VAL_ 1420 SubIndex_100C 0 "Guard Time" ;
VAL_ 1420 SubIndex_1007 0 "Sync_Window Length" ;
VAL_ 1420 SubIndex_1006 0 "Communication Cycle Period" ;
VAL_ 1420 SubIndex_1005 0 "COB-ID SYNC" ;
VAL_ 1420 SubIndex_1002 0 "Manufacturer Status Register" ;
VAL_ 1420 SubIndex_1001 0 "Error Register" ;
VAL_ 1420 SubIndex_1000 0 "Device Type" ;
VAL_ 1420 Index 25858 "supported_drive_modes" 25607 "motor_service_period" 25602 "motor_type" 24830 "digital_outputs" 24829 "digital_inputs" 24702 "polarity" 24679 "position_window" 24676 "position_actual_value" 24675 "position_actual_value" 24674 "position_demand_value" 24673 "modes_of_operation_display" 24672 "modes_of_operation" 24670 "fault_reaction_option_code" 24669 "stop_option_code" 24668 "disable_operation_option_code" 24667 "shutdown_option_code" 24666 "quick_stop_option_code" 24649 "vl_velocity_deceleration" 24648 "vl_velocity_acceleration" 24646 "vl_velocity_min_max_amount" 24644 "vl_control_effort" 24643 "vl_velocity_demand" 24642 "vl_target_velocity" 24641 "statusword" 24640 "controlword" 24639 "error_code" 24583 "abort_connection_option_code" 6662 "TxPDOMapping" 6661 "TxPDOMapping" 6660 "TxPDOMapping" 6659 "TxPDOMapping" 6658 "TxPDOMapping" 6657 "TxPDOMapping" 6656 "TxPDOMapping" 6150 "TxPDOComPar" 6149 "TxPDOComPar" 6148 "TxPDOComPar" 6147 "TxPDOComPar" 6146 "TxPDOComPar" 6145 "TxPDOComPar" 6144 "TxPDOComPar" 5639 "RxPDOMapping" 5638 "RxPDOMapping" 5637 "RxPDOMapping" 5636 "RxPDOMapping" 5635 "RxPDOMapping" 5634 "RxPDOMapping" 5633 "RxPDOMapping" 5632 "RxPDOMapping" 5127 "RxPDOComPar" 5126 "RxPDOComPar" 5125 "RxPDOComPar" 5124 "RxPDOComPar" 5123 "RxPDOComPar" 5122 "RxPDOComPar" 5121 "RxPDOComPar" 5120 "RxPDOComPar" 4120 "Identity Object" 4119 "Producer Heartbeat Time" 4118 "Consumer Heartbeat Time" 4112 "Store Parameter Field" 4109 "Life Time Factor" 4108 "Guard Time" 4103 "Sync_Window Length" 4102 "Communication Cycle Period" 4101 "COB-ID SYNC" 4098 "Manufacturer Status Register" 4097 "Error Register" 4096 "Device Type" ;
VAL_ 1420 TransferType 1 "Expedited transfer" 0 "Normal transfer" ;
VAL_ 1420 SizeIndicator 1 "Size is indicated" 0 "Size is not indicated" ;
VAL_ 1420 SCS 2 "Upload" 1 "Download" ;
VAL_ 1548 SubIndex_6502 0 "supported_drive_modes" ;
VAL_ 1548 SubIndex_6407 0 "motor_service_period" ;
VAL_ 1548 SubIndex_6402 0 "motor_type" ;
VAL_ 1548 SubIndex_60FE 2 "bitmask" 1 "physical_outputs" 0 "NrOfObjects" ;
VAL_ 1548 SubIndex_60FD 0 "digital_inputs" ;
VAL_ 1548 SubIndex_607E 0 "polarity" ;
VAL_ 1548 SubIndex_6067 0 "position_window" ;
VAL_ 1548 SubIndex_6064 0 "position_actual_value" ;
VAL_ 1548 SubIndex_6063 0 "position_actual_value" ;
VAL_ 1548 SubIndex_6062 0 "position_demand_value" ;
VAL_ 1548 SubIndex_6061 0 "modes_of_operation_display" ;
VAL_ 1548 SubIndex_6060 0 "modes_of_operation" ;
VAL_ 1548 SubIndex_605E 0 "fault_reaction_option_code" ;
VAL_ 1548 SubIndex_605D 0 "stop_option_code" ;
VAL_ 1548 SubIndex_605C 0 "disable_operation_option_code" ;
VAL_ 1548 SubIndex_605B 0 "shutdown_option_code" ;
VAL_ 1548 SubIndex_605A 0 "quick_stop_option_code" ;
VAL_ 1548 SubIndex_6049 2 "delta_time" 1 "delta_speed" 0 "NrOfObjects" ;
VAL_ 1548 SubIndex_6048 2 "delta_time" 1 "delta_speed" 0 "NrOfObjects" ;
VAL_ 1548 SubIndex_6046 2 "vl_velocity_max_amount" 1 "vl_velocity_min_amount" 0 "vl_velocity_min_max_amount_highest_subindex" ;
VAL_ 1548 SubIndex_6044 0 "vl_control_effort" ;
VAL_ 1548 SubIndex_6043 0 "vl_velocity_demand" ;
VAL_ 1548 SubIndex_6042 0 "vl_target_velocity" ;
VAL_ 1548 SubIndex_6041 0 "statusword" ;
VAL_ 1548 SubIndex_6040 0 "controlword" ;
VAL_ 1548 SubIndex_603F 0 "error_code" ;
VAL_ 1548 SubIndex_6007 0 "abort_connection_option_code" ;
VAL_ 1548 SubIndex_1A06 0 "NrOfMappedObjects" ;
VAL_ 1548 SubIndex_1A05 0 "NrOfMappedObjects" ;
VAL_ 1548 SubIndex_1A04 0 "NrOfMappedObjects" ;
VAL_ 1548 SubIndex_1A03 0 "NrOfMappedObjects" ;
VAL_ 1548 SubIndex_1A02 0 "NrOfMappedObjects" ;
VAL_ 1548 SubIndex_1A01 0 "NrOfMappedObjects" ;
VAL_ 1548 SubIndex_1A00 2 "mappedObj2" 1 "mappedObj1" 0 "NrOfMappedObjects" ;
VAL_ 1548 SubIndex_1806 5 "EventTimer" 2 "TransmissionType" 1 "COB-ID" 0 "NrOfEntries" ;
VAL_ 1548 SubIndex_1805 5 "EventTimer" 2 "TransmissionType" 1 "COB-ID" 0 "NrOfEntries" ;
VAL_ 1548 SubIndex_1804 5 "EventTimer" 2 "TransmissionType" 1 "COB-ID" 0 "NrOfEntries" ;
VAL_ 1548 SubIndex_1803 5 "EventTimer" 2 "TransmissionType" 1 "COB-ID" 0 "NrOfEntries" ;
VAL_ 1548 SubIndex_1802 5 "EventTimer" 2 "TransmissionType" 1 "COB-ID" 0 "NrOfEntries" ;
VAL_ 1548 SubIndex_1801 5 "EventTimer" 2 "TransmissionType" 1 "COB-ID" 0 "NrOfEntries" ;
VAL_ 1548 SubIndex_1800 5 "EventTimer" 2 "TransmissionType" 1 "COB-ID" 0 "NrOfEntries" ;
VAL_ 1548 SubIndex_1607 0 "NrOfMappedObjects" ;
VAL_ 1548 SubIndex_1606 0 "NrOfMappedObjects" ;
VAL_ 1548 SubIndex_1605 0 "NrOfMappedObjects" ;
VAL_ 1548 SubIndex_1604 0 "NrOfMappedObjects" ;
VAL_ 1548 SubIndex_1603 0 "NrOfMappedObjects" ;
VAL_ 1548 SubIndex_1602 0 "NrOfMappedObjects" ;
VAL_ 1548 SubIndex_1601 0 "NrOfMappedObjects" ;
VAL_ 1548 SubIndex_1600 2 "mappedObj2" 1 "mappedObj1" 0 "NrOfMappedObjects" ;
VAL_ 1548 SubIndex_1407 2 "TransmissionType" 1 "COB-ID" 0 "NrOfEntries" ;
VAL_ 1548 SubIndex_1406 2 "TransmissionType" 1 "COB-ID" 0 "NrOfEntries" ;
VAL_ 1548 SubIndex_1405 2 "TransmissionType" 1 "COB-ID" 0 "NrOfEntries" ;
VAL_ 1548 SubIndex_1404 2 "TransmissionType" 1 "COB-ID" 0 "NrOfEntries" ;
VAL_ 1548 SubIndex_1403 2 "TransmissionType" 1 "COB-ID" 0 "NrOfEntries" ;
VAL_ 1548 SubIndex_1402 2 "TransmissionType" 1 "COB-ID" 0 "NrOfEntries" ;
VAL_ 1548 SubIndex_1401 2 "TransmissionType" 1 "COB-ID" 0 "NrOfEntries" ;
VAL_ 1548 SubIndex_1400 2 "TransmissionType" 1 "COB-ID" 0 "NrOfEntries" ;
VAL_ 1548 SubIndex_1018 4 "Serial number" 3 "Revision number" 2 "Product Code" 1 "Vendor Id" 0 "number of entries" ;
VAL_ 1548 SubIndex_1017 0 "Producer Heartbeat Time" ;
VAL_ 1548 SubIndex_1016 126 "Consumer heartbeat time" 125 "Consumer heartbeat time" 124 "Consumer heartbeat time" 123 "Consumer heartbeat time" 122 "Consumer heartbeat time" 121 "Consumer heartbeat time" 120 "Consumer heartbeat time" 119 "Consumer heartbeat time" 118 "Consumer heartbeat time" 117 "Consumer heartbeat time" 116 "Consumer heartbeat time" 115 "Consumer heartbeat time" 114 "Consumer heartbeat time" 113 "Consumer heartbeat time" 112 "Consumer heartbeat time" 111 "Consumer heartbeat time" 110 "Consumer heartbeat time" 109 "Consumer heartbeat time" 108 "Consumer heartbeat time" 107 "Consumer heartbeat time" 106 "Consumer heartbeat time" 105 "Consumer heartbeat time" 104 "Consumer heartbeat time" 103 "Consumer heartbeat time" 102 "Consumer heartbeat time" 101 "Consumer heartbeat time" 100 "Consumer heartbeat time" 99 "Consumer heartbeat time" 98 "Consumer heartbeat time" 97 "Consumer heartbeat time" 96 "Consumer heartbeat time" 95 "Consumer heartbeat time" 94 "Consumer heartbeat time" 93 "Consumer heartbeat time" 92 "Consumer heartbeat time" 91 "Consumer heartbeat time" 90 "Consumer heartbeat time" 89 "Consumer heartbeat time" 88 "Consumer heartbeat time" 87 "Consumer heartbeat time" 86 "Consumer heartbeat time" 85 "Consumer heartbeat time" 84 "Consumer heartbeat time" 83 "Consumer heartbeat time" 82 "Consumer heartbeat time" 81 "Consumer heartbeat time" 80 "Consumer heartbeat time" 79 "Consumer heartbeat time" 78 "Consumer heartbeat time" 77 "Consumer heartbeat time" 76 "Consumer heartbeat time" 75 "Consumer heartbeat time" 74 "Consumer heartbeat time" 73 "Consumer heartbeat time" 72 "Consumer heartbeat time" 71 "Consumer heartbeat time" 70 "Consumer heartbeat time" 69 "Consumer heartbeat time" 68 "Consumer heartbeat time" 67 "Consumer heartbeat time" 66 "Consumer heartbeat time" 65 "Consumer heartbeat time" 64 "Consumer heartbeat time" 63 "Consumer heartbeat time" 62 "Consumer heartbeat time" 61 "Consumer heartbeat time" 60 "Consumer heartbeat time" 59 "Consumer heartbeat time" 58 "Consumer heartbeat time" 57 "Consumer heartbeat time" 56 "Consumer heartbeat time" 55 "Consumer heartbeat time" 54 "Consumer heartbeat time" 53 "Consumer heartbeat time" 52 "Consumer heartbeat time" 51 "Consumer heartbeat time" 50 "Consumer heartbeat time" 49 "Consumer heartbeat time" 48 "Consumer heartbeat time" 47 "Consumer heartbeat time" 46 "Consumer heartbeat time" 45 "Consumer heartbeat time" 44 "Consumer heartbeat time" 43 "Consumer heartbeat time" 42 "Consumer heartbeat time" 41 "Consumer heartbeat time" 40 "Consumer heartbeat time" 39 "Consumer heartbeat time" 38 "Consumer heartbeat time" 37 "Consumer heartbeat time" 36 "Consumer heartbeat time" 35 "Consumer heartbeat time" 34 "Consumer heartbeat time" 33 "Consumer heartbeat time" 32 "Consumer heartbeat time" 31 "Consumer heartbeat time" 30 "Consumer heartbeat time" 29 "Consumer heartbeat time" 28 "Consumer heartbeat time" 27 "Consumer heartbeat time" 26 "Consumer heartbeat time" 25 "Consumer heartbeat time" 24 "Consumer heartbeat time" 23 "Consumer heartbeat time" 22 "Consumer heartbeat time" 21 "Consumer heartbeat time" 20 "Consumer heartbeat time" 19 "Consumer heartbeat time" 18 "Consumer heartbeat time" 17 "Consumer heartbeat time" 16 "Consumer heartbeat time" 15 "Consumer heartbeat time" 14 "Consumer heartbeat time" 13 "Consumer heartbeat time" 12 "Consumer heartbeat time" 11 "Consumer heartbeat time" 10 "Consumer heartbeat time" 9 "Consumer Heartbeat Time" 8 "Consumer Heartbeat Time" 7 "Consumer Heartbeat Time" 6 "Consumer Heartbeat Time" 5 "Consumer Heartbeat Time" 4 "Consumer Heartbeat Time" 3 "Consumer Heartbeat Time" 2 "Consumer Heartbeat Time" 1 "Consumer Heartbeat Time" 0 "Highest sub-index supported" ;
VAL_ 1548 SubIndex_1010 1 "Save all Parameters" 0 "Number of Entries" ;
VAL_ 1548 SubIndex_100D 0 "Life Time Factor" ;
VAL_ 1548 SubIndex_100C 0 "Guard Time" ;
VAL_ 1548 SubIndex_1007 0 "Sync_Window Length" ;
VAL_ 1548 SubIndex_1006 0 "Communication Cycle Period" ;
VAL_ 1548 SubIndex_1005 0 "COB-ID SYNC" ;
VAL_ 1548 SubIndex_1002 0 "Manufacturer Status Register" ;
VAL_ 1548 SubIndex_1001 0 "Error Register" ;
VAL_ 1548 SubIndex_1000 0 "Device Type" ;
VAL_ 1548 Index 25858 "supported_drive_modes" 25607 "motor_service_period" 25602 "motor_type" 24830 "digital_outputs" 24829 "digital_inputs" 24702 "polarity" 24679 "position_window" 24676 "position_actual_value" 24675 "position_actual_value" 24674 "position_demand_value" 24673 "modes_of_operation_display" 24672 "modes_of_operation" 24670 "fault_reaction_option_code" 24669 "stop_option_code" 24668 "disable_operation_option_code" 24667 "shutdown_option_code" 24666 "quick_stop_option_code" 24649 "vl_velocity_deceleration" 24648 "vl_velocity_acceleration" 24646 "vl_velocity_min_max_amount" 24644 "vl_control_effort" 24643 "vl_velocity_demand" 24642 "vl_target_velocity" 24641 "statusword" 24640 "controlword" 24639 "error_code" 24583 "abort_connection_option_code" 6662 "TxPDOMapping" 6661 "TxPDOMapping" 6660 "TxPDOMapping" 6659 "TxPDOMapping" 6658 "TxPDOMapping" 6657 "TxPDOMapping" 6656 "TxPDOMapping" 6150 "TxPDOComPar" 6149 "TxPDOComPar" 6148 "TxPDOComPar" 6147 "TxPDOComPar" 6146 "TxPDOComPar" 6145 "TxPDOComPar" 6144 "TxPDOComPar" 5639 "RxPDOMapping" 5638 "RxPDOMapping" 5637 "RxPDOMapping" 5636 "RxPDOMapping" 5635 "RxPDOMapping" 5634 "RxPDOMapping" 5633 "RxPDOMapping" 5632 "RxPDOMapping" 5127 "RxPDOComPar" 5126 "RxPDOComPar" 5125 "RxPDOComPar" 5124 "RxPDOComPar" 5123 "RxPDOComPar" 5122 "RxPDOComPar" 5121 "RxPDOComPar" 5120 "RxPDOComPar" 4120 "Identity Object" 4119 "Producer Heartbeat Time" 4118 "Consumer Heartbeat Time" 4112 "Store Parameter Field" 4109 "Life Time Factor" 4108 "Guard Time" 4103 "Sync_Window Length" 4102 "Communication Cycle Period" 4101 "COB-ID SYNC" 4098 "Manufacturer Status Register" 4097 "Error Register" 4096 "Device Type" ;
VAL_ 1548 TransferType 1 "Expedited transfer" 0 "Normal transfer" ;
VAL_ 1548 SizeIndicator 1 "Size is indicated" 0 "Size is not indicated" ;
VAL_ 1548 CCS 2 "Upload" 1 "Download" ;
VAL_ 140 ErrorCode 61444 "(DS-402) Control error" 61443 "(DS-402) Control, stroke operation" 61442 "(DS-402) Control, sub-synchronous run" 61441 "(DS-402) Control, deceleration" 35328 "(DS-402) Control" 35072 "(DS-402) Winding controller - process data monitoring" 34816 "(DS-402) Winding controller" 34560 "(DS-402) Sync controller" 34322 "(DS-402) Positioning - reference limit" 34321 "(DS-402) Positioning - following error" 34304 "(DS-402) Positioning controller" 34048 "(DS-402) Position controller" 33792 "(DS-402) Velocity speed controller" 33585 "(DS-402) Torque fault" 33569 "(DS-402) Insufficient torque" 33555 "(DS-402) Standstill torque" 33554 "(DS-402) Difficult start up" 33553 "(DS-402) Excess torque" 33536 "(DS-402) Torque control" 30208 "(DS-402) Data storage (external)" 29984 "(DS-402) Serial interface no. 2" 29968 "(DS-402) Serial interface no. 1" 29952 "(DS-402) Communication" 29696 "(DS-402) Computation circuit" 29472 "(DS-402) Position" 29456 "(DS-402) Speed" 29447 "(DS-402) Incremental sensor 3 fault" 29446 "(DS-402) Incremental sensor 2 fault" 29445 "(DS-402) Incremental sensor 1 fault" 29444 "(DS-402) Resolver 2 fault" 29443 "(DS-402) Resolver 1 fault" 29442 "(DS-402) Tacho wrong polarity" 29441 "(DS-402) Tacho fault" 29440 "(DS-402) Sensor" 29184 "(DS-402) Measurement circuit  " 28963 "(DS-402) Motor tilted" 28962 "(DS-402) Motor error or commutation malfunction" 28961 "(DS-402) Motor blocked" 28960 "(DS-402) Motor" 28947 "(DS-402) Protective circuit brake chopper" 28946 "(DS-402) Over current brake chopper" 28945 "(DS-402) Failure brake chopper" 28944 "(DS-402) Brake chopper" 28928 "(DS-402) Power" 25376 "(DS-402) Parameter error" 25360 "(DS-402) Loss of parameters" 25359 "(DS-402) Reset watchdog - data record no. 15" 25358 "(DS-402) Reset watchdog - data record no. 14" 25357 "(DS-402) Reset watchdog - data record no. 13" 25356 "(DS-402) Reset watchdog - data record no. 12" 25355 "(DS-402) Reset watchdog - data record no. 11" 25354 "(DS-402) Reset watchdog - data record no. 10" 25353 "(DS-402) Reset watchdog - data record no. 9" 25352 "(DS-402) Reset watchdog - data record no. 8" 25351 "(DS-402) Reset watchdog - data record no. 7" 25350 "(DS-402) Reset watchdog - data record no. 6" 25349 "(DS-402) Reset watchdog - data record no. 5" 25348 "(DS-402) Reset watchdog - data record no. 4" 25347 "(DS-402) Reset watchdog - data record no. 3" 25346 "(DS-402) Reset watchdog - data record no. 2" 25345 "(DS-402) Reset watchdog - data record no. 1" 24592 "(DS-402) Software reset (watchdog)" 21808 "(DS-402) EEPROM" 21792 "(DS-402) ROM/EPROM" 21776 "(DS-402) RAM" 21760 "(DS-402) Hardware memory" 21593 "(DS-402) Fuses S9 = manufacturer-specific" 21592 "(DS-402) Fuses S8 = manufacturer-specific" 21591 "(DS-402) Fuses S7 = manufacturer-specific" 21590 "(DS-402) Fuses S6 = manufacturer-specific" 21589 "(DS-402) Fuses S5 = manufacturer-specific" 21588 "(DS-402) Fuses S4 = manufacturer-specific" 21587 "(DS-402) Fuses S3 = l3" 21586 "(DS-402) Fuses S2 = l2" 21585 "(DS-402) Fuses S1 = l1" 21584 "(DS-402) Fuses" 21573 "(DS-402) Contact 5 = manufacturer-specific" 21572 "(DS-402) Contact 4 = manufacturer-specific" 21571 "(DS-402) Contact 3 = manufacturer-specific" 21570 "(DS-402) Contact 2 = manufacturer-specific" 21569 "(DS-402) Contact 1 = manufacturer-specific" 21568 "(DS-402) Contacts" 21552 "(DS-402) Input stages" 21536 "(DS-402) Chopper" 21520 "(DS-402) Output stages" 21504 "(DS-402) Power section" 21248 "(DS-402) Operating unit" 21024 "(DS-402) Control, computing circuit" 21008 "(DS-402) Control, measurement circuit" 20992 "(DS-402) Control" 20768 "(DS-402) Supply intermediate circuit" 20761 "(DS-402) Supply low voltage U9 = manufacturer-specific" 20760 "(DS-402) Supply low voltage U8 = manufacturer-specific" 20759 "(DS-402) Supply low voltage U7 = manufacturer-specific" 20758 "(DS-402) Supply low voltage U6 = manufacturer-specific" 20757 "(DS-402) Supply low voltage U5 = manufacturer-specific" 20756 "(DS-402) Supply low voltage U4 = manufacturer-specific" 20755 "(DS-402) Supply low voltage U3 = supply +5 V" 20754 "(DS-402) Supply low voltage U2 = supply +24V" 20753 "(DS-402) Supply low voltage U1 = supply ±15V" 20752 "(DS-402) Supply low voltage" 20736 "(DS-402) Supply" 17440 "(DS-402) Too low temperature supply" 17424 "(DS-402) Excess temperature supply" 17408 "(DS-402) Temperature supply" 17184 "(DS-402) Too low temperature drive" 17168 "(DS-402) Excess temperature drive" 17152 "(DS-402) Temperature drive" 16928 "(DS-402) Field circ. interrupted, too low temperature device" 16912 "(DS-402) Field circ. interrupted, excess temperature device" 16704 "(DS-402) Field circ. interrupted, temperature air outlet" 16688 "(DS-402) Field circ. interrupted, temperature supply air" 16672 "(DS-402) Field circ. interrupted, too low ambient temperature" 16656 "(DS-402) Field circ. interrupted, Excess ambient temperature" 13105 "(DS-402) Field circuit interrupted" 13104 "(DS-402) Field circuit" 13089 "(DS-402) Armature circuit interrupted" 13088 "(DS-402) Armature circuit" 13075 "(DS-402) Output over-voltage phase W " 13074 "(DS-402) Output over-voltage phase V " 13073 "(DS-402) Output over-voltage phase U " 13072 "(DS-402) Output over-voltage" 12848 "(DS-402) Load error" 12834 "(DS-402) DC link under-voltage no. 2" 12833 "(DS-402) DC link under-voltage no. 1" 12832 "(DS-402) DC link under-voltage" 12818 "(DS-402) DC link over voltage no. 2" 12817 "(DS-402) DC link over-voltage no. 1" 12816 "(DS-402) DC link over-voltage" 12610 "(DS-402) Mains frequency too small" 12609 "(DS-402) Mains frequency too great" 12608 "(DS-402) Mains frequency" 12596 "(DS-402) Phase sequence" 12595 "(DS-402) Phase failure L3" 12594 "(DS-402) Phase failure L2" 12593 "(DS-402) Phase failure L1" 12592 "(DS-402) Phase failure" 12579 "(DS-402) Mains under-voltage phase L3" 12578 "(DS-402) Mains under-voltage phase L2" 12577 "(DS-402) Mains under-voltage phase L1" 12576 "(DS-402) Mains under-voltage" 12563 "(DS-402) Mains over-voltage phase L3 " 12562 "(DS-402) Mains over-voltage phase L2" 12561 "(DS-402) Mains over-voltage phase L1" 12560 "(DS-402) Mains over-voltage" 9041 "(DS-402) Load level warning (I2t, thermal state)" 9040 "(DS-402) Load level fault (I2t, thermal state)" 9027 "(DS-402) Earth leakage (motor-side) phase W-U" 9026 "(DS-402) Earth leakage (motor-side) phase V-W" 9025 "(DS-402) Short circuit (motor-side) phases U-V" 9024 "(DS-402) Short circuit (motor-side)" 9011 "(DS-402) Earth leakage (motor-side) phase W" 9010 "(DS-402) Earth leakage (motor-side) phase V" 9009 "(DS-402) Earth leakage (motor-side) phase U" 9008 "(DS-402) Earth leakage (motor-side)" 8992 "(DS-402) Short circuit/earth leakage (motor-side)" 8978 "(DS-402) Device internal, continuous over current no. 2" 8977 "(DS-402) Device internal, continuous over current no. 1" 8976 "(DS-402) Device internal, continuous over current" 8784 "(DS-402) Short circuit (device internal) " 8768 "(DS-402) Earth leakage (device internal)" 8752 "(DS-402) Short circuit/earth leakage (device internal)" 8738 "(DS-402) Continuous over current no.2" 8737 "(DS-402) Continuous over current no.1" 8736 "(DS-402) Continuous over current (device internal)" 8724 "(DS-402) Short circuit (input), over-current in the sequence" 8723 "(DS-402) Short circuit (input), over-current in ramp function" 8722 "(DS-402) Short circuit (input), internal current no.2" 8721 "(DS-402) Short circuit (input), internal current no.1" 8499 "(DS-402) Short circuit phases (input) L3-L1" 8498 "(DS-402) Short circuit phases (input) L2-L3" 8497 "(DS-402) Short circuit phases (input) L1-L2" 8496 "(DS-402) Short circuit (input)" 8483 "(DS-402) Earth leakage (input) phase L3" 8482 "(DS-402) Earth leakage (input) phase L2" 8481 "(DS-402) Earth leakage (input) phase L1" 8480 "(DS-402) Earth leakage (input)" 8464 "(DS-402) Short circuit/earth leakage (input)" 33360 "RPDO timeout" 33344 "Unexpected SYNC data length" 33328 "DAM MPDO not processed, destination object not available" 33312 "PDO length exceeded" 33296 "PDO not processed due to length error" 33104 "Transmit COB-ID collision" 33088 "Recovered from bus off state" 33072 "Life guard error or heartbeat error" 33056 "CAN in error passive mode" 33040 "CAN overrun (objects lost)" ;
VAL_ 1805 State 127 "PreOperational" 5 "Operational" 4 "Stopped" 0 "Bootup" ;
SG_MUL_VAL_ 1420 supported_drive_modes_6502 SubIndex_6502 0-0;
SG_MUL_VAL_ 1420 SubIndex_6502 Index 25858-25858;
SG_MUL_VAL_ 1420 motor_service_period_6407 SubIndex_6407 0-0;
SG_MUL_VAL_ 1420 SubIndex_6407 Index 25607-25607;
SG_MUL_VAL_ 1420 motor_type_6402 SubIndex_6402 0-0;
SG_MUL_VAL_ 1420 SubIndex_6402 Index 25602-25602;
SG_MUL_VAL_ 1420 bitmask_60FE_02 SubIndex_60FE 2-2;
SG_MUL_VAL_ 1420 physical_outputs_60FE_01 SubIndex_60FE 1-1;
SG_MUL_VAL_ 1420 NrOfObjects_60FE_00 SubIndex_60FE 0-0;
SG_MUL_VAL_ 1420 SubIndex_60FE Index 24830-24830;
SG_MUL_VAL_ 1420 digital_inputs_60FD SubIndex_60FD 0-0;
SG_MUL_VAL_ 1420 SubIndex_60FD Index 24829-24829;
SG_MUL_VAL_ 1420 polarity_607E SubIndex_607E 0-0;
SG_MUL_VAL_ 1420 SubIndex_607E Index 24702-24702;
SG_MUL_VAL_ 1420 position_window_6067 SubIndex_6067 0-0;
SG_MUL_VAL_ 1420 SubIndex_6067 Index 24679-24679;
SG_MUL_VAL_ 1420 position_actual_value_6064 SubIndex_6064 0-0;
SG_MUL_VAL_ 1420 SubIndex_6064 Index 24676-24676;
SG_MUL_VAL_ 1420 position_actual_value_6063 SubIndex_6063 0-0;
SG_MUL_VAL_ 1420 SubIndex_6063 Index 24675-24675;
SG_MUL_VAL_ 1420 position_demand_value_6062 SubIndex_6062 0-0;
SG_MUL_VAL_ 1420 SubIndex_6062 Index 24674-24674;
SG_MUL_VAL_ 1420 modes_of_operation_display_6061 SubIndex_6061 0-0;
SG_MUL_VAL_ 1420 SubIndex_6061 Index 24673-24673;
SG_MUL_VAL_ 1420 modes_of_operation_6060 SubIndex_6060 0-0;
SG_MUL_VAL_ 1420 SubIndex_6060 Index 24672-24672;
SG_MUL_VAL_ 1420 fault_reaction_option_code_605E SubIndex_605E 0-0;
SG_MUL_VAL_ 1420 SubIndex_605E Index 24670-24670;
SG_MUL_VAL_ 1420 stop_option_code_605D SubIndex_605D 0-0;
SG_MUL_VAL_ 1420 SubIndex_605D Index 24669-24669;
SG_MUL_VAL_ 1420 disable_operation_option_co_0001 SubIndex_605C 0-0;
SG_MUL_VAL_ 1420 SubIndex_605C Index 24668-24668;
SG_MUL_VAL_ 1420 shutdown_option_code_605B SubIndex_605B 0-0;
SG_MUL_VAL_ 1420 SubIndex_605B Index 24667-24667;
SG_MUL_VAL_ 1420 quick_stop_option_code_605A SubIndex_605A 0-0;
SG_MUL_VAL_ 1420 SubIndex_605A Index 24666-24666;
SG_MUL_VAL_ 1420 delta_time_6049_02 SubIndex_6049 2-2;
SG_MUL_VAL_ 1420 delta_speed_6049_01 SubIndex_6049 1-1;
SG_MUL_VAL_ 1420 NrOfObjects_6049_00 SubIndex_6049 0-0;
SG_MUL_VAL_ 1420 SubIndex_6049 Index 24649-24649;
SG_MUL_VAL_ 1420 delta_time_6048_02 SubIndex_6048 2-2;
SG_MUL_VAL_ 1420 delta_speed_6048_01 SubIndex_6048 1-1;
SG_MUL_VAL_ 1420 NrOfObjects_6048_00 SubIndex_6048 0-0;
SG_MUL_VAL_ 1420 SubIndex_6048 Index 24648-24648;
SG_MUL_VAL_ 1420 vl_velocity_max_amount_6046_02 SubIndex_6046 2-2;
SG_MUL_VAL_ 1420 vl_velocity_min_amount_6046_01 SubIndex_6046 1-1;
SG_MUL_VAL_ 1420 vl_velocity_min_max_amount__0001 SubIndex_6046 0-0;
SG_MUL_VAL_ 1420 SubIndex_6046 Index 24646-24646;
SG_MUL_VAL_ 1420 vl_control_effort_6044 SubIndex_6044 0-0;
SG_MUL_VAL_ 1420 SubIndex_6044 Index 24644-24644;
SG_MUL_VAL_ 1420 vl_velocity_demand_6043 SubIndex_6043 0-0;
SG_MUL_VAL_ 1420 SubIndex_6043 Index 24643-24643;
SG_MUL_VAL_ 1420 vl_target_velocity_6042 SubIndex_6042 0-0;
SG_MUL_VAL_ 1420 SubIndex_6042 Index 24642-24642;
SG_MUL_VAL_ 1420 statusword_6041 SubIndex_6041 0-0;
SG_MUL_VAL_ 1420 SubIndex_6041 Index 24641-24641;
SG_MUL_VAL_ 1420 controlword_6040 SubIndex_6040 0-0;
SG_MUL_VAL_ 1420 SubIndex_6040 Index 24640-24640;
SG_MUL_VAL_ 1420 error_code_603F SubIndex_603F 0-0;
SG_MUL_VAL_ 1420 SubIndex_603F Index 24639-24639;
SG_MUL_VAL_ 1420 abort_connection_option_cod_0001 SubIndex_6007 0-0;
SG_MUL_VAL_ 1420 SubIndex_6007 Index 24583-24583;
SG_MUL_VAL_ 1420 NrOfMappedObjects_1A06_00 SubIndex_1A06 0-0;
SG_MUL_VAL_ 1420 SubIndex_1A06 Index 6662-6662;
SG_MUL_VAL_ 1420 NrOfMappedObjects_1A05_00 SubIndex_1A05 0-0;
SG_MUL_VAL_ 1420 SubIndex_1A05 Index 6661-6661;
SG_MUL_VAL_ 1420 NrOfMappedObjects_1A04_00 SubIndex_1A04 0-0;
SG_MUL_VAL_ 1420 SubIndex_1A04 Index 6660-6660;
SG_MUL_VAL_ 1420 NrOfMappedObjects_1A03_00 SubIndex_1A03 0-0;
SG_MUL_VAL_ 1420 SubIndex_1A03 Index 6659-6659;
SG_MUL_VAL_ 1420 NrOfMappedObjects_1A02_00 SubIndex_1A02 0-0;
SG_MUL_VAL_ 1420 SubIndex_1A02 Index 6658-6658;
SG_MUL_VAL_ 1420 NrOfMappedObjects_1A01_00 SubIndex_1A01 0-0;
SG_MUL_VAL_ 1420 SubIndex_1A01 Index 6657-6657;
SG_MUL_VAL_ 1420 mappedObj2_1A00_02 SubIndex_1A00 2-2;
SG_MUL_VAL_ 1420 mappedObj1_1A00_01 SubIndex_1A00 1-1;
SG_MUL_VAL_ 1420 NrOfMappedObjects_1A00_00 SubIndex_1A00 0-0;
SG_MUL_VAL_ 1420 SubIndex_1A00 Index 6656-6656;
SG_MUL_VAL_ 1420 EventTimer_1806_05 SubIndex_1806 5-5;
SG_MUL_VAL_ 1420 TransmissionType_1806_02 SubIndex_1806 2-2;
SG_MUL_VAL_ 1420 COB_ID_1806_01 SubIndex_1806 1-1;
SG_MUL_VAL_ 1420 NrOfEntries_1806_00 SubIndex_1806 0-0;
SG_MUL_VAL_ 1420 SubIndex_1806 Index 6150-6150;
SG_MUL_VAL_ 1420 EventTimer_1805_05 SubIndex_1805 5-5;
SG_MUL_VAL_ 1420 TransmissionType_1805_02 SubIndex_1805 2-2;
SG_MUL_VAL_ 1420 COB_ID_1805_01 SubIndex_1805 1-1;
SG_MUL_VAL_ 1420 NrOfEntries_1805_00 SubIndex_1805 0-0;
SG_MUL_VAL_ 1420 SubIndex_1805 Index 6149-6149;
SG_MUL_VAL_ 1420 EventTimer_1804_05 SubIndex_1804 5-5;
SG_MUL_VAL_ 1420 TransmissionType_1804_02 SubIndex_1804 2-2;
SG_MUL_VAL_ 1420 COB_ID_1804_01 SubIndex_1804 1-1;
SG_MUL_VAL_ 1420 NrOfEntries_1804_00 SubIndex_1804 0-0;
SG_MUL_VAL_ 1420 SubIndex_1804 Index 6148-6148;
SG_MUL_VAL_ 1420 EventTimer_1803_05 SubIndex_1803 5-5;
SG_MUL_VAL_ 1420 TransmissionType_1803_02 SubIndex_1803 2-2;
SG_MUL_VAL_ 1420 COB_ID_1803_01 SubIndex_1803 1-1;
SG_MUL_VAL_ 1420 NrOfEntries_1803_00 SubIndex_1803 0-0;
SG_MUL_VAL_ 1420 SubIndex_1803 Index 6147-6147;
SG_MUL_VAL_ 1420 EventTimer_1802_05 SubIndex_1802 5-5;
SG_MUL_VAL_ 1420 TransmissionType_1802_02 SubIndex_1802 2-2;
SG_MUL_VAL_ 1420 COB_ID_1802_01 SubIndex_1802 1-1;
SG_MUL_VAL_ 1420 NrOfEntries_1802_00 SubIndex_1802 0-0;
SG_MUL_VAL_ 1420 SubIndex_1802 Index 6146-6146;
SG_MUL_VAL_ 1420 EventTimer_1801_05 SubIndex_1801 5-5;
SG_MUL_VAL_ 1420 TransmissionType_1801_02 SubIndex_1801 2-2;
SG_MUL_VAL_ 1420 COB_ID_1801_01 SubIndex_1801 1-1;
SG_MUL_VAL_ 1420 NrOfEntries_1801_00 SubIndex_1801 0-0;
SG_MUL_VAL_ 1420 SubIndex_1801 Index 6145-6145;
SG_MUL_VAL_ 1420 EventTimer_1800_05 SubIndex_1800 5-5;
SG_MUL_VAL_ 1420 TransmissionType_1800_02 SubIndex_1800 2-2;
SG_MUL_VAL_ 1420 COB_ID_1800_01 SubIndex_1800 1-1;
SG_MUL_VAL_ 1420 NrOfEntries_1800_00 SubIndex_1800 0-0;
SG_MUL_VAL_ 1420 SubIndex_1800 Index 6144-6144;
SG_MUL_VAL_ 1420 NrOfMappedObjects_1607_00 SubIndex_1607 0-0;
SG_MUL_VAL_ 1420 SubIndex_1607 Index 5639-5639;
SG_MUL_VAL_ 1420 NrOfMappedObjects_1606_00 SubIndex_1606 0-0;
SG_MUL_VAL_ 1420 SubIndex_1606 Index 5638-5638;
SG_MUL_VAL_ 1420 NrOfMappedObjects_1605_00 SubIndex_1605 0-0;
SG_MUL_VAL_ 1420 SubIndex_1605 Index 5637-5637;
SG_MUL_VAL_ 1420 NrOfMappedObjects_1604_00 SubIndex_1604 0-0;
SG_MUL_VAL_ 1420 SubIndex_1604 Index 5636-5636;
SG_MUL_VAL_ 1420 NrOfMappedObjects_1603_00 SubIndex_1603 0-0;
SG_MUL_VAL_ 1420 SubIndex_1603 Index 5635-5635;
SG_MUL_VAL_ 1420 NrOfMappedObjects_1602_00 SubIndex_1602 0-0;
SG_MUL_VAL_ 1420 SubIndex_1602 Index 5634-5634;
SG_MUL_VAL_ 1420 NrOfMappedObjects_1601_00 SubIndex_1601 0-0;
SG_MUL_VAL_ 1420 SubIndex_1601 Index 5633-5633;
SG_MUL_VAL_ 1420 mappedObj2_1600_02 SubIndex_1600 2-2;
SG_MUL_VAL_ 1420 mappedObj1_1600_01 SubIndex_1600 1-1;
SG_MUL_VAL_ 1420 NrOfMappedObjects_1600_00 SubIndex_1600 0-0;
SG_MUL_VAL_ 1420 SubIndex_1600 Index 5632-5632;
SG_MUL_VAL_ 1420 TransmissionType_1407_02 SubIndex_1407 2-2;
SG_MUL_VAL_ 1420 COB_ID_1407_01 SubIndex_1407 1-1;
SG_MUL_VAL_ 1420 NrOfEntries_1407_00 SubIndex_1407 0-0;
SG_MUL_VAL_ 1420 SubIndex_1407 Index 5127-5127;
SG_MUL_VAL_ 1420 TransmissionType_1406_02 SubIndex_1406 2-2;
SG_MUL_VAL_ 1420 COB_ID_1406_01 SubIndex_1406 1-1;
SG_MUL_VAL_ 1420 NrOfEntries_1406_00 SubIndex_1406 0-0;
SG_MUL_VAL_ 1420 SubIndex_1406 Index 5126-5126;
SG_MUL_VAL_ 1420 TransmissionType_1405_02 SubIndex_1405 2-2;
SG_MUL_VAL_ 1420 COB_ID_1405_01 SubIndex_1405 1-1;
SG_MUL_VAL_ 1420 NrOfEntries_1405_00 SubIndex_1405 0-0;
SG_MUL_VAL_ 1420 SubIndex_1405 Index 5125-5125;
SG_MUL_VAL_ 1420 TransmissionType_1404_02 SubIndex_1404 2-2;
SG_MUL_VAL_ 1420 COB_ID_1404_01 SubIndex_1404 1-1;
SG_MUL_VAL_ 1420 NrOfEntries_1404_00 SubIndex_1404 0-0;
SG_MUL_VAL_ 1420 SubIndex_1404 Index 5124-5124;
SG_MUL_VAL_ 1420 TransmissionType_1403_02 SubIndex_1403 2-2;
SG_MUL_VAL_ 1420 COB_ID_1403_01 SubIndex_1403 1-1;
SG_MUL_VAL_ 1420 NrOfEntries_1403_00 SubIndex_1403 0-0;
SG_MUL_VAL_ 1420 SubIndex_1403 Index 5123-5123;
SG_MUL_VAL_ 1420 TransmissionType_1402_02 SubIndex_1402 2-2;
SG_MUL_VAL_ 1420 COB_ID_1402_01 SubIndex_1402 1-1;
SG_MUL_VAL_ 1420 NrOfEntries_1402_00 SubIndex_1402 0-0;
SG_MUL_VAL_ 1420 SubIndex_1402 Index 5122-5122;
SG_MUL_VAL_ 1420 TransmissionType_1401_02 SubIndex_1401 2-2;
SG_MUL_VAL_ 1420 COB_ID_1401_01 SubIndex_1401 1-1;
SG_MUL_VAL_ 1420 NrOfEntries_1401_00 SubIndex_1401 0-0;
SG_MUL_VAL_ 1420 SubIndex_1401 Index 5121-5121;
SG_MUL_VAL_ 1420 TransmissionType_1400_02 SubIndex_1400 2-2;
SG_MUL_VAL_ 1420 COB_ID_1400_01 SubIndex_1400 1-1;
SG_MUL_VAL_ 1420 NrOfEntries_1400_00 SubIndex_1400 0-0;
SG_MUL_VAL_ 1420 SubIndex_1400 Index 5120-5120;
SG_MUL_VAL_ 1420 Serial_number_1018_04 SubIndex_1018 4-4;
SG_MUL_VAL_ 1420 Revision_number_1018_03 SubIndex_1018 3-3;
SG_MUL_VAL_ 1420 Product_Code_1018_02 SubIndex_1018 2-2;
SG_MUL_VAL_ 1420 Vendor_Id_1018_01 SubIndex_1018 1-1;
SG_MUL_VAL_ 1420 number_of_entries_1018_00 SubIndex_1018 0-0;
SG_MUL_VAL_ 1420 SubIndex_1018 Index 4120-4120;
SG_MUL_VAL_ 1420 Producer_Heartbeat_Time_1017 SubIndex_1017 0-0;
SG_MUL_VAL_ 1420 SubIndex_1017 Index 4119-4119;
SG_MUL_VAL_ 1420 Consumer_heartbeat_time_1016_7E SubIndex_1016 126-126;
SG_MUL_VAL_ 1420 Consumer_heartbeat_time_1016_7D SubIndex_1016 125-125;
SG_MUL_VAL_ 1420 Consumer_heartbeat_time_1016_7C SubIndex_1016 124-124;
SG_MUL_VAL_ 1420 Consumer_heartbeat_time_1016_7B SubIndex_1016 123-123;
SG_MUL_VAL_ 1420 Consumer_heartbeat_time_1016_7A SubIndex_1016 122-122;
SG_MUL_VAL_ 1420 Consumer_heartbeat_time_1016_79 SubIndex_1016 121-121;
SG_MUL_VAL_ 1420 Consumer_heartbeat_time_1016_78 SubIndex_1016 120-120;
SG_MUL_VAL_ 1420 Consumer_heartbeat_time_1016_77 SubIndex_1016 119-119;
SG_MUL_VAL_ 1420 Consumer_heartbeat_time_1016_76 SubIndex_1016 118-118;
SG_MUL_VAL_ 1420 Consumer_heartbeat_time_1016_75 SubIndex_1016 117-117;
SG_MUL_VAL_ 1420 Consumer_heartbeat_time_1016_74 SubIndex_1016 116-116;
SG_MUL_VAL_ 1420 Consumer_heartbeat_time_1016_73 SubIndex_1016 115-115;
SG_MUL_VAL_ 1420 Consumer_heartbeat_time_1016_72 SubIndex_1016 114-114;
SG_MUL_VAL_ 1420 Consumer_heartbeat_time_1016_71 SubIndex_1016 113-113;
SG_MUL_VAL_ 1420 Consumer_heartbeat_time_1016_70 SubIndex_1016 112-112;
SG_MUL_VAL_ 1420 Consumer_heartbeat_time_1016_6F SubIndex_1016 111-111;
SG_MUL_VAL_ 1420 Consumer_heartbeat_time_1016_6E SubIndex_1016 110-110;
SG_MUL_VAL_ 1420 Consumer_heartbeat_time_1016_6D SubIndex_1016 109-109;
SG_MUL_VAL_ 1420 Consumer_heartbeat_time_1016_6C SubIndex_1016 108-108;
SG_MUL_VAL_ 1420 Consumer_heartbeat_time_1016_6B SubIndex_1016 107-107;
SG_MUL_VAL_ 1420 Consumer_heartbeat_time_1016_6A SubIndex_1016 106-106;
SG_MUL_VAL_ 1420 Consumer_heartbeat_time_1016_69 SubIndex_1016 105-105;
SG_MUL_VAL_ 1420 Consumer_heartbeat_time_1016_68 SubIndex_1016 104-104;
SG_MUL_VAL_ 1420 Consumer_heartbeat_time_1016_67 SubIndex_1016 103-103;
SG_MUL_VAL_ 1420 Consumer_heartbeat_time_1016_66 SubIndex_1016 102-102;
SG_MUL_VAL_ 1420 Consumer_heartbeat_time_1016_65 SubIndex_1016 101-101;
SG_MUL_VAL_ 1420 Consumer_heartbeat_time_1016_64 SubIndex_1016 100-100;
SG_MUL_VAL_ 1420 Consumer_heartbeat_time_1016_63 SubIndex_1016 99-99;
SG_MUL_VAL_ 1420 Consumer_heartbeat_time_1016_62 SubIndex_1016 98-98;
SG_MUL_VAL_ 1420 Consumer_heartbeat_time_1016_61 SubIndex_1016 97-97;
SG_MUL_VAL_ 1420 Consumer_heartbeat_time_1016_60 SubIndex_1016 96-96;
SG_MUL_VAL_ 1420 Consumer_heartbeat_time_1016_5F SubIndex_1016 95-95;
SG_MUL_VAL_ 1420 Consumer_heartbeat_time_1016_5E SubIndex_1016 94-94;
SG_MUL_VAL_ 1420 Consumer_heartbeat_time_1016_5D SubIndex_1016 93-93;
SG_MUL_VAL_ 1420 Consumer_heartbeat_time_1016_5C SubIndex_1016 92-92;
SG_MUL_VAL_ 1420 Consumer_heartbeat_time_1016_5B SubIndex_1016 91-91;
SG_MUL_VAL_ 1420 Consumer_heartbeat_time_1016_5A SubIndex_1016 90-90;
SG_MUL_VAL_ 1420 Consumer_heartbeat_time_1016_59 SubIndex_1016 89-89;
SG_MUL_VAL_ 1420 Consumer_heartbeat_time_1016_58 SubIndex_1016 88-88;
SG_MUL_VAL_ 1420 Consumer_heartbeat_time_1016_57 SubIndex_1016 87-87;
SG_MUL_VAL_ 1420 Consumer_heartbeat_time_1016_56 SubIndex_1016 86-86;
SG_MUL_VAL_ 1420 Consumer_heartbeat_time_1016_55 SubIndex_1016 85-85;
SG_MUL_VAL_ 1420 Consumer_heartbeat_time_1016_54 SubIndex_1016 84-84;
SG_MUL_VAL_ 1420 Consumer_heartbeat_time_1016_53 SubIndex_1016 83-83;
SG_MUL_VAL_ 1420 Consumer_heartbeat_time_1016_52 SubIndex_1016 82-82;
SG_MUL_VAL_ 1420 Consumer_heartbeat_time_1016_51 SubIndex_1016 81-81;
SG_MUL_VAL_ 1420 Consumer_heartbeat_time_1016_50 SubIndex_1016 80-80;
SG_MUL_VAL_ 1420 Consumer_heartbeat_time_1016_4F SubIndex_1016 79-79;
SG_MUL_VAL_ 1420 Consumer_heartbeat_time_1016_4E SubIndex_1016 78-78;
SG_MUL_VAL_ 1420 Consumer_heartbeat_time_1016_4D SubIndex_1016 77-77;
SG_MUL_VAL_ 1420 Consumer_heartbeat_time_1016_4C SubIndex_1016 76-76;
SG_MUL_VAL_ 1420 Consumer_heartbeat_time_1016_4B SubIndex_1016 75-75;
SG_MUL_VAL_ 1420 Consumer_heartbeat_time_1016_4A SubIndex_1016 74-74;
SG_MUL_VAL_ 1420 Consumer_heartbeat_time_1016_49 SubIndex_1016 73-73;
SG_MUL_VAL_ 1420 Consumer_heartbeat_time_1016_48 SubIndex_1016 72-72;
SG_MUL_VAL_ 1420 Consumer_heartbeat_time_1016_47 SubIndex_1016 71-71;
SG_MUL_VAL_ 1420 Consumer_heartbeat_time_1016_46 SubIndex_1016 70-70;
SG_MUL_VAL_ 1420 Consumer_heartbeat_time_1016_45 SubIndex_1016 69-69;
SG_MUL_VAL_ 1420 Consumer_heartbeat_time_1016_44 SubIndex_1016 68-68;
SG_MUL_VAL_ 1420 Consumer_heartbeat_time_1016_43 SubIndex_1016 67-67;
SG_MUL_VAL_ 1420 Consumer_heartbeat_time_1016_42 SubIndex_1016 66-66;
SG_MUL_VAL_ 1420 Consumer_heartbeat_time_1016_41 SubIndex_1016 65-65;
SG_MUL_VAL_ 1420 Consumer_heartbeat_time_1016_40 SubIndex_1016 64-64;
SG_MUL_VAL_ 1420 Consumer_heartbeat_time_1016_3F SubIndex_1016 63-63;
SG_MUL_VAL_ 1420 Consumer_heartbeat_time_1016_3E SubIndex_1016 62-62;
SG_MUL_VAL_ 1420 Consumer_heartbeat_time_1016_3D SubIndex_1016 61-61;
SG_MUL_VAL_ 1420 Consumer_heartbeat_time_1016_3C SubIndex_1016 60-60;
SG_MUL_VAL_ 1420 Consumer_heartbeat_time_1016_3B SubIndex_1016 59-59;
SG_MUL_VAL_ 1420 Consumer_heartbeat_time_1016_3A SubIndex_1016 58-58;
SG_MUL_VAL_ 1420 Consumer_heartbeat_time_1016_39 SubIndex_1016 57-57;
SG_MUL_VAL_ 1420 Consumer_heartbeat_time_1016_38 SubIndex_1016 56-56;
SG_MUL_VAL_ 1420 Consumer_heartbeat_time_1016_37 SubIndex_1016 55-55;
SG_MUL_VAL_ 1420 Consumer_heartbeat_time_1016_36 SubIndex_1016 54-54;
SG_MUL_VAL_ 1420 Consumer_heartbeat_time_1016_35 SubIndex_1016 53-53;
SG_MUL_VAL_ 1420 Consumer_heartbeat_time_1016_34 SubIndex_1016 52-52;
SG_MUL_VAL_ 1420 Consumer_heartbeat_time_1016_33 SubIndex_1016 51-51;
SG_MUL_VAL_ 1420 Consumer_heartbeat_time_1016_32 SubIndex_1016 50-50;
SG_MUL_VAL_ 1420 Consumer_heartbeat_time_1016_31 SubIndex_1016 49-49;
SG_MUL_VAL_ 1420 Consumer_heartbeat_time_1016_30 SubIndex_1016 48-48;
SG_MUL_VAL_ 1420 Consumer_heartbeat_time_1016_2F SubIndex_1016 47-47;
SG_MUL_VAL_ 1420 Consumer_heartbeat_time_1016_2E SubIndex_1016 46-46;
SG_MUL_VAL_ 1420 Consumer_heartbeat_time_1016_2D SubIndex_1016 45-45;
SG_MUL_VAL_ 1420 Consumer_heartbeat_time_1016_2C SubIndex_1016 44-44;
SG_MUL_VAL_ 1420 Consumer_heartbeat_time_1016_2B SubIndex_1016 43-43;
SG_MUL_VAL_ 1420 Consumer_heartbeat_time_1016_2A SubIndex_1016 42-42;
SG_MUL_VAL_ 1420 Consumer_heartbeat_time_1016_29 SubIndex_1016 41-41;
SG_MUL_VAL_ 1420 Consumer_heartbeat_time_1016_28 SubIndex_1016 40-40;
SG_MUL_VAL_ 1420 Consumer_heartbeat_time_1016_27 SubIndex_1016 39-39;
SG_MUL_VAL_ 1420 Consumer_heartbeat_time_1016_26 SubIndex_1016 38-38;
SG_MUL_VAL_ 1420 Consumer_heartbeat_time_1016_25 SubIndex_1016 37-37;
SG_MUL_VAL_ 1420 Consumer_heartbeat_time_1016_24 SubIndex_1016 36-36;
SG_MUL_VAL_ 1420 Consumer_heartbeat_time_1016_23 SubIndex_1016 35-35;
SG_MUL_VAL_ 1420 Consumer_heartbeat_time_1016_22 SubIndex_1016 34-34;
SG_MUL_VAL_ 1420 Consumer_heartbeat_time_1016_21 SubIndex_1016 33-33;
SG_MUL_VAL_ 1420 Consumer_heartbeat_time_1016_20 SubIndex_1016 32-32;
SG_MUL_VAL_ 1420 Consumer_heartbeat_time_1016_1F SubIndex_1016 31-31;
SG_MUL_VAL_ 1420 Consumer_heartbeat_time_1016_1E SubIndex_1016 30-30;
SG_MUL_VAL_ 1420 Consumer_heartbeat_time_1016_1D SubIndex_1016 29-29;
SG_MUL_VAL_ 1420 Consumer_heartbeat_time_1016_1C SubIndex_1016 28-28;
SG_MUL_VAL_ 1420 Consumer_heartbeat_time_1016_1B SubIndex_1016 27-27;
SG_MUL_VAL_ 1420 Consumer_heartbeat_time_1016_1A SubIndex_1016 26-26;
SG_MUL_VAL_ 1420 Consumer_heartbeat_time_1016_19 SubIndex_1016 25-25;
SG_MUL_VAL_ 1420 Consumer_heartbeat_time_1016_18 SubIndex_1016 24-24;
SG_MUL_VAL_ 1420 Consumer_heartbeat_time_1016_17 SubIndex_1016 23-23;
SG_MUL_VAL_ 1420 Consumer_heartbeat_time_1016_16 SubIndex_1016 22-22;
SG_MUL_VAL_ 1420 Consumer_heartbeat_time_1016_15 SubIndex_1016 21-21;
SG_MUL_VAL_ 1420 Consumer_heartbeat_time_1016_14 SubIndex_1016 20-20;
SG_MUL_VAL_ 1420 Consumer_heartbeat_time_1016_13 SubIndex_1016 19-19;
SG_MUL_VAL_ 1420 Consumer_heartbeat_time_1016_12 SubIndex_1016 18-18;
SG_MUL_VAL_ 1420 Consumer_heartbeat_time_1016_11 SubIndex_1016 17-17;
SG_MUL_VAL_ 1420 Consumer_heartbeat_time_1016_10 SubIndex_1016 16-16;
SG_MUL_VAL_ 1420 Consumer_heartbeat_time_1016_0F SubIndex_1016 15-15;
SG_MUL_VAL_ 1420 Consumer_heartbeat_time_1016_0E SubIndex_1016 14-14;
SG_MUL_VAL_ 1420 Consumer_heartbeat_time_1016_0D SubIndex_1016 13-13;
SG_MUL_VAL_ 1420 Consumer_heartbeat_time_1016_0C SubIndex_1016 12-12;
SG_MUL_VAL_ 1420 Consumer_heartbeat_time_1016_0B SubIndex_1016 11-11;
SG_MUL_VAL_ 1420 Consumer_heartbeat_time_1016_0A SubIndex_1016 10-10;
SG_MUL_VAL_ 1420 Consumer_Heartbeat_Time_1016_09 SubIndex_1016 9-9;
SG_MUL_VAL_ 1420 Consumer_Heartbeat_Time_1016_08 SubIndex_1016 8-8;
SG_MUL_VAL_ 1420 Consumer_Heartbeat_Time_1016_07 SubIndex_1016 7-7;
SG_MUL_VAL_ 1420 Consumer_Heartbeat_Time_1016_06 SubIndex_1016 6-6;
SG_MUL_VAL_ 1420 Consumer_Heartbeat_Time_1016_05 SubIndex_1016 5-5;
SG_MUL_VAL_ 1420 Consumer_Heartbeat_Time_1016_04 SubIndex_1016 4-4;
SG_MUL_VAL_ 1420 Consumer_Heartbeat_Time_1016_03 SubIndex_1016 3-3;
SG_MUL_VAL_ 1420 Consumer_Heartbeat_Time_1016_02 SubIndex_1016 2-2;
SG_MUL_VAL_ 1420 Consumer_Heartbeat_Time_1016_01 SubIndex_1016 1-1;
SG_MUL_VAL_ 1420 Highest_sub_index_supported_1016 SubIndex_1016 0-0;
SG_MUL_VAL_ 1420 SubIndex_1016 Index 4118-4118;
SG_MUL_VAL_ 1420 Save_all_Parameters_1010_01 SubIndex_1010 1-1;
SG_MUL_VAL_ 1420 Number_of_Entries_1010_00 SubIndex_1010 0-0;
SG_MUL_VAL_ 1420 SubIndex_1010 Index 4112-4112;
SG_MUL_VAL_ 1420 Life_Time_Factor_100D SubIndex_100D 0-0;
SG_MUL_VAL_ 1420 SubIndex_100D Index 4109-4109;
SG_MUL_VAL_ 1420 Guard_Time_100C SubIndex_100C 0-0;
SG_MUL_VAL_ 1420 SubIndex_100C Index 4108-4108;
SG_MUL_VAL_ 1420 Sync_Window_Length_1007 SubIndex_1007 0-0;
SG_MUL_VAL_ 1420 SubIndex_1007 Index 4103-4103;
SG_MUL_VAL_ 1420 Communication_Cycle_Period_1006 SubIndex_1006 0-0;
SG_MUL_VAL_ 1420 SubIndex_1006 Index 4102-4102;
SG_MUL_VAL_ 1420 COB_ID_SYNC_1005 SubIndex_1005 0-0;
SG_MUL_VAL_ 1420 SubIndex_1005 Index 4101-4101;
SG_MUL_VAL_ 1420 Manufacturer_Status_Registe_0005 SubIndex_1002 0-0;
SG_MUL_VAL_ 1420 SubIndex_1002 Index 4098-4098;
SG_MUL_VAL_ 1420 Error_Register_1001 SubIndex_1001 0-0;
SG_MUL_VAL_ 1420 SubIndex_1001 Index 4097-4097;
SG_MUL_VAL_ 1420 Device_Type_1000 SubIndex_1000 0-0;
SG_MUL_VAL_ 1420 SubIndex_1000 Index 4096-4096;
SG_MUL_VAL_ 1420 Index TransferType 1-1;
SG_MUL_VAL_ 1420 TransferType SCS 1-2;
SG_MUL_VAL_ 1420 NotUsedBytes SCS 1-2;
SG_MUL_VAL_ 1420 SizeIndicator SCS 1-2;
SG_MUL_VAL_ 1548 supported_drive_modes_6502 SubIndex_6502 0-0;
SG_MUL_VAL_ 1548 SubIndex_6502 Index 25858-25858;
SG_MUL_VAL_ 1548 motor_service_period_6407 SubIndex_6407 0-0;
SG_MUL_VAL_ 1548 SubIndex_6407 Index 25607-25607;
SG_MUL_VAL_ 1548 motor_type_6402 SubIndex_6402 0-0;
SG_MUL_VAL_ 1548 SubIndex_6402 Index 25602-25602;
SG_MUL_VAL_ 1548 bitmask_60FE_02 SubIndex_60FE 2-2;
SG_MUL_VAL_ 1548 physical_outputs_60FE_01 SubIndex_60FE 1-1;
SG_MUL_VAL_ 1548 NrOfObjects_60FE_00 SubIndex_60FE 0-0;
SG_MUL_VAL_ 1548 SubIndex_60FE Index 24830-24830;
SG_MUL_VAL_ 1548 digital_inputs_60FD SubIndex_60FD 0-0;
SG_MUL_VAL_ 1548 SubIndex_60FD Index 24829-24829;
SG_MUL_VAL_ 1548 polarity_607E SubIndex_607E 0-0;
SG_MUL_VAL_ 1548 SubIndex_607E Index 24702-24702;
SG_MUL_VAL_ 1548 position_window_6067 SubIndex_6067 0-0;
SG_MUL_VAL_ 1548 SubIndex_6067 Index 24679-24679;
SG_MUL_VAL_ 1548 position_actual_value_6064 SubIndex_6064 0-0;
SG_MUL_VAL_ 1548 SubIndex_6064 Index 24676-24676;
SG_MUL_VAL_ 1548 position_actual_value_6063 SubIndex_6063 0-0;
SG_MUL_VAL_ 1548 SubIndex_6063 Index 24675-24675;
SG_MUL_VAL_ 1548 position_demand_value_6062 SubIndex_6062 0-0;
SG_MUL_VAL_ 1548 SubIndex_6062 Index 24674-24674;
SG_MUL_VAL_ 1548 modes_of_operation_display_6061 SubIndex_6061 0-0;
SG_MUL_VAL_ 1548 SubIndex_6061 Index 24673-24673;
SG_MUL_VAL_ 1548 modes_of_operation_6060 SubIndex_6060 0-0;
SG_MUL_VAL_ 1548 SubIndex_6060 Index 24672-24672;
SG_MUL_VAL_ 1548 fault_reaction_option_code_605E SubIndex_605E 0-0;
SG_MUL_VAL_ 1548 SubIndex_605E Index 24670-24670;
SG_MUL_VAL_ 1548 stop_option_code_605D SubIndex_605D 0-0;
SG_MUL_VAL_ 1548 SubIndex_605D Index 24669-24669;
SG_MUL_VAL_ 1548 disable_operation_option_co_0002 SubIndex_605C 0-0;
SG_MUL_VAL_ 1548 SubIndex_605C Index 24668-24668;
SG_MUL_VAL_ 1548 shutdown_option_code_605B SubIndex_605B 0-0;
SG_MUL_VAL_ 1548 SubIndex_605B Index 24667-24667;
SG_MUL_VAL_ 1548 quick_stop_option_code_605A SubIndex_605A 0-0;
SG_MUL_VAL_ 1548 SubIndex_605A Index 24666-24666;
SG_MUL_VAL_ 1548 delta_time_6049_02 SubIndex_6049 2-2;
SG_MUL_VAL_ 1548 delta_speed_6049_01 SubIndex_6049 1-1;
SG_MUL_VAL_ 1548 NrOfObjects_6049_00 SubIndex_6049 0-0;
SG_MUL_VAL_ 1548 SubIndex_6049 Index 24649-24649;
SG_MUL_VAL_ 1548 delta_time_6048_02 SubIndex_6048 2-2;
SG_MUL_VAL_ 1548 delta_speed_6048_01 SubIndex_6048 1-1;
SG_MUL_VAL_ 1548 NrOfObjects_6048_00 SubIndex_6048 0-0;
SG_MUL_VAL_ 1548 SubIndex_6048 Index 24648-24648;
SG_MUL_VAL_ 1548 vl_velocity_max_amount_6046_02 SubIndex_6046 2-2;
SG_MUL_VAL_ 1548 vl_velocity_min_amount_6046_01 SubIndex_6046 1-1;
SG_MUL_VAL_ 1548 vl_velocity_min_max_amount__0002 SubIndex_6046 0-0;
SG_MUL_VAL_ 1548 SubIndex_6046 Index 24646-24646;
SG_MUL_VAL_ 1548 vl_control_effort_6044 SubIndex_6044 0-0;
SG_MUL_VAL_ 1548 SubIndex_6044 Index 24644-24644;
SG_MUL_VAL_ 1548 vl_velocity_demand_6043 SubIndex_6043 0-0;
SG_MUL_VAL_ 1548 SubIndex_6043 Index 24643-24643;
SG_MUL_VAL_ 1548 vl_target_velocity_6042 SubIndex_6042 0-0;
SG_MUL_VAL_ 1548 SubIndex_6042 Index 24642-24642;
SG_MUL_VAL_ 1548 statusword_6041 SubIndex_6041 0-0;
SG_MUL_VAL_ 1548 SubIndex_6041 Index 24641-24641;
SG_MUL_VAL_ 1548 controlword_6040 SubIndex_6040 0-0;
SG_MUL_VAL_ 1548 SubIndex_6040 Index 24640-24640;
SG_MUL_VAL_ 1548 error_code_603F SubIndex_603F 0-0;
SG_MUL_VAL_ 1548 SubIndex_603F Index 24639-24639;
SG_MUL_VAL_ 1548 abort_connection_option_cod_0002 SubIndex_6007 0-0;
SG_MUL_VAL_ 1548 SubIndex_6007 Index 24583-24583;
SG_MUL_VAL_ 1548 NrOfMappedObjects_1A06_00 SubIndex_1A06 0-0;
SG_MUL_VAL_ 1548 SubIndex_1A06 Index 6662-6662;
SG_MUL_VAL_ 1548 NrOfMappedObjects_1A05_00 SubIndex_1A05 0-0;
SG_MUL_VAL_ 1548 SubIndex_1A05 Index 6661-6661;
SG_MUL_VAL_ 1548 NrOfMappedObjects_1A04_00 SubIndex_1A04 0-0;
SG_MUL_VAL_ 1548 SubIndex_1A04 Index 6660-6660;
SG_MUL_VAL_ 1548 NrOfMappedObjects_1A03_00 SubIndex_1A03 0-0;
SG_MUL_VAL_ 1548 SubIndex_1A03 Index 6659-6659;
SG_MUL_VAL_ 1548 NrOfMappedObjects_1A02_00 SubIndex_1A02 0-0;
SG_MUL_VAL_ 1548 SubIndex_1A02 Index 6658-6658;
SG_MUL_VAL_ 1548 NrOfMappedObjects_1A01_00 SubIndex_1A01 0-0;
SG_MUL_VAL_ 1548 SubIndex_1A01 Index 6657-6657;
SG_MUL_VAL_ 1548 mappedObj2_1A00_02 SubIndex_1A00 2-2;
SG_MUL_VAL_ 1548 mappedObj1_1A00_01 SubIndex_1A00 1-1;
SG_MUL_VAL_ 1548 NrOfMappedObjects_1A00_00 SubIndex_1A00 0-0;
SG_MUL_VAL_ 1548 SubIndex_1A00 Index 6656-6656;
SG_MUL_VAL_ 1548 EventTimer_1806_05 SubIndex_1806 5-5;
SG_MUL_VAL_ 1548 TransmissionType_1806_02 SubIndex_1806 2-2;
SG_MUL_VAL_ 1548 COB_ID_1806_01 SubIndex_1806 1-1;
SG_MUL_VAL_ 1548 NrOfEntries_1806_00 SubIndex_1806 0-0;
SG_MUL_VAL_ 1548 SubIndex_1806 Index 6150-6150;
SG_MUL_VAL_ 1548 EventTimer_1805_05 SubIndex_1805 5-5;
SG_MUL_VAL_ 1548 TransmissionType_1805_02 SubIndex_1805 2-2;
SG_MUL_VAL_ 1548 COB_ID_1805_01 SubIndex_1805 1-1;
SG_MUL_VAL_ 1548 NrOfEntries_1805_00 SubIndex_1805 0-0;
SG_MUL_VAL_ 1548 SubIndex_1805 Index 6149-6149;
SG_MUL_VAL_ 1548 EventTimer_1804_05 SubIndex_1804 5-5;
SG_MUL_VAL_ 1548 TransmissionType_1804_02 SubIndex_1804 2-2;
SG_MUL_VAL_ 1548 COB_ID_1804_01 SubIndex_1804 1-1;
SG_MUL_VAL_ 1548 NrOfEntries_1804_00 SubIndex_1804 0-0;
SG_MUL_VAL_ 1548 SubIndex_1804 Index 6148-6148;
SG_MUL_VAL_ 1548 EventTimer_1803_05 SubIndex_1803 5-5;
SG_MUL_VAL_ 1548 TransmissionType_1803_02 SubIndex_1803 2-2;
SG_MUL_VAL_ 1548 COB_ID_1803_01 SubIndex_1803 1-1;
SG_MUL_VAL_ 1548 NrOfEntries_1803_00 SubIndex_1803 0-0;
SG_MUL_VAL_ 1548 SubIndex_1803 Index 6147-6147;
SG_MUL_VAL_ 1548 EventTimer_1802_05 SubIndex_1802 5-5;
SG_MUL_VAL_ 1548 TransmissionType_1802_02 SubIndex_1802 2-2;
SG_MUL_VAL_ 1548 COB_ID_1802_01 SubIndex_1802 1-1;
SG_MUL_VAL_ 1548 NrOfEntries_1802_00 SubIndex_1802 0-0;
SG_MUL_VAL_ 1548 SubIndex_1802 Index 6146-6146;
SG_MUL_VAL_ 1548 EventTimer_1801_05 SubIndex_1801 5-5;
SG_MUL_VAL_ 1548 TransmissionType_1801_02 SubIndex_1801 2-2;
SG_MUL_VAL_ 1548 COB_ID_1801_01 SubIndex_1801 1-1;
SG_MUL_VAL_ 1548 NrOfEntries_1801_00 SubIndex_1801 0-0;
SG_MUL_VAL_ 1548 SubIndex_1801 Index 6145-6145;
SG_MUL_VAL_ 1548 EventTimer_1800_05 SubIndex_1800 5-5;
SG_MUL_VAL_ 1548 TransmissionType_1800_02 SubIndex_1800 2-2;
SG_MUL_VAL_ 1548 COB_ID_1800_01 SubIndex_1800 1-1;
SG_MUL_VAL_ 1548 NrOfEntries_1800_00 SubIndex_1800 0-0;
SG_MUL_VAL_ 1548 SubIndex_1800 Index 6144-6144;
SG_MUL_VAL_ 1548 NrOfMappedObjects_1607_00 SubIndex_1607 0-0;
SG_MUL_VAL_ 1548 SubIndex_1607 Index 5639-5639;
SG_MUL_VAL_ 1548 NrOfMappedObjects_1606_00 SubIndex_1606 0-0;
SG_MUL_VAL_ 1548 SubIndex_1606 Index 5638-5638;
SG_MUL_VAL_ 1548 NrOfMappedObjects_1605_00 SubIndex_1605 0-0;
SG_MUL_VAL_ 1548 SubIndex_1605 Index 5637-5637;
SG_MUL_VAL_ 1548 NrOfMappedObjects_1604_00 SubIndex_1604 0-0;
SG_MUL_VAL_ 1548 SubIndex_1604 Index 5636-5636;
SG_MUL_VAL_ 1548 NrOfMappedObjects_1603_00 SubIndex_1603 0-0;
SG_MUL_VAL_ 1548 SubIndex_1603 Index 5635-5635;
SG_MUL_VAL_ 1548 NrOfMappedObjects_1602_00 SubIndex_1602 0-0;
SG_MUL_VAL_ 1548 SubIndex_1602 Index 5634-5634;
SG_MUL_VAL_ 1548 NrOfMappedObjects_1601_00 SubIndex_1601 0-0;
SG_MUL_VAL_ 1548 SubIndex_1601 Index 5633-5633;
SG_MUL_VAL_ 1548 mappedObj2_1600_02 SubIndex_1600 2-2;
SG_MUL_VAL_ 1548 mappedObj1_1600_01 SubIndex_1600 1-1;
SG_MUL_VAL_ 1548 NrOfMappedObjects_1600_00 SubIndex_1600 0-0;
SG_MUL_VAL_ 1548 SubIndex_1600 Index 5632-5632;
SG_MUL_VAL_ 1548 TransmissionType_1407_02 SubIndex_1407 2-2;
SG_MUL_VAL_ 1548 COB_ID_1407_01 SubIndex_1407 1-1;
SG_MUL_VAL_ 1548 NrOfEntries_1407_00 SubIndex_1407 0-0;
SG_MUL_VAL_ 1548 SubIndex_1407 Index 5127-5127;
SG_MUL_VAL_ 1548 TransmissionType_1406_02 SubIndex_1406 2-2;
SG_MUL_VAL_ 1548 COB_ID_1406_01 SubIndex_1406 1-1;
SG_MUL_VAL_ 1548 NrOfEntries_1406_00 SubIndex_1406 0-0;
SG_MUL_VAL_ 1548 SubIndex_1406 Index 5126-5126;
SG_MUL_VAL_ 1548 TransmissionType_1405_02 SubIndex_1405 2-2;
SG_MUL_VAL_ 1548 COB_ID_1405_01 SubIndex_1405 1-1;
SG_MUL_VAL_ 1548 NrOfEntries_1405_00 SubIndex_1405 0-0;
SG_MUL_VAL_ 1548 SubIndex_1405 Index 5125-5125;
SG_MUL_VAL_ 1548 TransmissionType_1404_02 SubIndex_1404 2-2;
SG_MUL_VAL_ 1548 COB_ID_1404_01 SubIndex_1404 1-1;
SG_MUL_VAL_ 1548 NrOfEntries_1404_00 SubIndex_1404 0-0;
SG_MUL_VAL_ 1548 SubIndex_1404 Index 5124-5124;
SG_MUL_VAL_ 1548 TransmissionType_1403_02 SubIndex_1403 2-2;
SG_MUL_VAL_ 1548 COB_ID_1403_01 SubIndex_1403 1-1;
SG_MUL_VAL_ 1548 NrOfEntries_1403_00 SubIndex_1403 0-0;
SG_MUL_VAL_ 1548 SubIndex_1403 Index 5123-5123;
SG_MUL_VAL_ 1548 TransmissionType_1402_02 SubIndex_1402 2-2;
SG_MUL_VAL_ 1548 COB_ID_1402_01 SubIndex_1402 1-1;
SG_MUL_VAL_ 1548 NrOfEntries_1402_00 SubIndex_1402 0-0;
SG_MUL_VAL_ 1548 SubIndex_1402 Index 5122-5122;
SG_MUL_VAL_ 1548 TransmissionType_1401_02 SubIndex_1401 2-2;
SG_MUL_VAL_ 1548 COB_ID_1401_01 SubIndex_1401 1-1;
SG_MUL_VAL_ 1548 NrOfEntries_1401_00 SubIndex_1401 0-0;
SG_MUL_VAL_ 1548 SubIndex_1401 Index 5121-5121;
SG_MUL_VAL_ 1548 TransmissionType_1400_02 SubIndex_1400 2-2;
SG_MUL_VAL_ 1548 COB_ID_1400_01 SubIndex_1400 1-1;
SG_MUL_VAL_ 1548 NrOfEntries_1400_00 SubIndex_1400 0-0;
SG_MUL_VAL_ 1548 SubIndex_1400 Index 5120-5120;
SG_MUL_VAL_ 1548 Serial_number_1018_04 SubIndex_1018 4-4;
SG_MUL_VAL_ 1548 Revision_number_1018_03 SubIndex_1018 3-3;
SG_MUL_VAL_ 1548 Product_Code_1018_02 SubIndex_1018 2-2;
SG_MUL_VAL_ 1548 Vendor_Id_1018_01 SubIndex_1018 1-1;
SG_MUL_VAL_ 1548 number_of_entries_1018_00 SubIndex_1018 0-0;
SG_MUL_VAL_ 1548 SubIndex_1018 Index 4120-4120;
SG_MUL_VAL_ 1548 Producer_Heartbeat_Time_1017 SubIndex_1017 0-0;
SG_MUL_VAL_ 1548 SubIndex_1017 Index 4119-4119;
SG_MUL_VAL_ 1548 Consumer_heartbeat_time_1016_7E SubIndex_1016 126-126;
SG_MUL_VAL_ 1548 Consumer_heartbeat_time_1016_7D SubIndex_1016 125-125;
SG_MUL_VAL_ 1548 Consumer_heartbeat_time_1016_7C SubIndex_1016 124-124;
SG_MUL_VAL_ 1548 Consumer_heartbeat_time_1016_7B SubIndex_1016 123-123;
SG_MUL_VAL_ 1548 Consumer_heartbeat_time_1016_7A SubIndex_1016 122-122;
SG_MUL_VAL_ 1548 Consumer_heartbeat_time_1016_79 SubIndex_1016 121-121;
SG_MUL_VAL_ 1548 Consumer_heartbeat_time_1016_78 SubIndex_1016 120-120;
SG_MUL_VAL_ 1548 Consumer_heartbeat_time_1016_77 SubIndex_1016 119-119;
SG_MUL_VAL_ 1548 Consumer_heartbeat_time_1016_76 SubIndex_1016 118-118;
SG_MUL_VAL_ 1548 Consumer_heartbeat_time_1016_75 SubIndex_1016 117-117;
SG_MUL_VAL_ 1548 Consumer_heartbeat_time_1016_74 SubIndex_1016 116-116;
SG_MUL_VAL_ 1548 Consumer_heartbeat_time_1016_73 SubIndex_1016 115-115;
SG_MUL_VAL_ 1548 Consumer_heartbeat_time_1016_72 SubIndex_1016 114-114;
SG_MUL_VAL_ 1548 Consumer_heartbeat_time_1016_71 SubIndex_1016 113-113;
SG_MUL_VAL_ 1548 Consumer_heartbeat_time_1016_70 SubIndex_1016 112-112;
SG_MUL_VAL_ 1548 Consumer_heartbeat_time_1016_6F SubIndex_1016 111-111;
SG_MUL_VAL_ 1548 Consumer_heartbeat_time_1016_6E SubIndex_1016 110-110;
SG_MUL_VAL_ 1548 Consumer_heartbeat_time_1016_6D SubIndex_1016 109-109;
SG_MUL_VAL_ 1548 Consumer_heartbeat_time_1016_6C SubIndex_1016 108-108;
SG_MUL_VAL_ 1548 Consumer_heartbeat_time_1016_6B SubIndex_1016 107-107;
SG_MUL_VAL_ 1548 Consumer_heartbeat_time_1016_6A SubIndex_1016 106-106;
SG_MUL_VAL_ 1548 Consumer_heartbeat_time_1016_69 SubIndex_1016 105-105;
SG_MUL_VAL_ 1548 Consumer_heartbeat_time_1016_68 SubIndex_1016 104-104;
SG_MUL_VAL_ 1548 Consumer_heartbeat_time_1016_67 SubIndex_1016 103-103;
SG_MUL_VAL_ 1548 Consumer_heartbeat_time_1016_66 SubIndex_1016 102-102;
SG_MUL_VAL_ 1548 Consumer_heartbeat_time_1016_65 SubIndex_1016 101-101;
SG_MUL_VAL_ 1548 Consumer_heartbeat_time_1016_64 SubIndex_1016 100-100;
SG_MUL_VAL_ 1548 Consumer_heartbeat_time_1016_63 SubIndex_1016 99-99;
SG_MUL_VAL_ 1548 Consumer_heartbeat_time_1016_62 SubIndex_1016 98-98;
SG_MUL_VAL_ 1548 Consumer_heartbeat_time_1016_61 SubIndex_1016 97-97;
SG_MUL_VAL_ 1548 Consumer_heartbeat_time_1016_60 SubIndex_1016 96-96;
SG_MUL_VAL_ 1548 Consumer_heartbeat_time_1016_5F SubIndex_1016 95-95;
SG_MUL_VAL_ 1548 Consumer_heartbeat_time_1016_5E SubIndex_1016 94-94;
SG_MUL_VAL_ 1548 Consumer_heartbeat_time_1016_5D SubIndex_1016 93-93;
SG_MUL_VAL_ 1548 Consumer_heartbeat_time_1016_5C SubIndex_1016 92-92;
SG_MUL_VAL_ 1548 Consumer_heartbeat_time_1016_5B SubIndex_1016 91-91;
SG_MUL_VAL_ 1548 Consumer_heartbeat_time_1016_5A SubIndex_1016 90-90;
SG_MUL_VAL_ 1548 Consumer_heartbeat_time_1016_59 SubIndex_1016 89-89;
SG_MUL_VAL_ 1548 Consumer_heartbeat_time_1016_58 SubIndex_1016 88-88;
SG_MUL_VAL_ 1548 Consumer_heartbeat_time_1016_57 SubIndex_1016 87-87;
SG_MUL_VAL_ 1548 Consumer_heartbeat_time_1016_56 SubIndex_1016 86-86;
SG_MUL_VAL_ 1548 Consumer_heartbeat_time_1016_55 SubIndex_1016 85-85;
SG_MUL_VAL_ 1548 Consumer_heartbeat_time_1016_54 SubIndex_1016 84-84;
SG_MUL_VAL_ 1548 Consumer_heartbeat_time_1016_53 SubIndex_1016 83-83;
SG_MUL_VAL_ 1548 Consumer_heartbeat_time_1016_52 SubIndex_1016 82-82;
SG_MUL_VAL_ 1548 Consumer_heartbeat_time_1016_51 SubIndex_1016 81-81;
SG_MUL_VAL_ 1548 Consumer_heartbeat_time_1016_50 SubIndex_1016 80-80;
SG_MUL_VAL_ 1548 Consumer_heartbeat_time_1016_4F SubIndex_1016 79-79;
SG_MUL_VAL_ 1548 Consumer_heartbeat_time_1016_4E SubIndex_1016 78-78;
SG_MUL_VAL_ 1548 Consumer_heartbeat_time_1016_4D SubIndex_1016 77-77;
SG_MUL_VAL_ 1548 Consumer_heartbeat_time_1016_4C SubIndex_1016 76-76;
SG_MUL_VAL_ 1548 Consumer_heartbeat_time_1016_4B SubIndex_1016 75-75;
SG_MUL_VAL_ 1548 Consumer_heartbeat_time_1016_4A SubIndex_1016 74-74;
SG_MUL_VAL_ 1548 Consumer_heartbeat_time_1016_49 SubIndex_1016 73-73;
SG_MUL_VAL_ 1548 Consumer_heartbeat_time_1016_48 SubIndex_1016 72-72;
SG_MUL_VAL_ 1548 Consumer_heartbeat_time_1016_47 SubIndex_1016 71-71;
SG_MUL_VAL_ 1548 Consumer_heartbeat_time_1016_46 SubIndex_1016 70-70;
SG_MUL_VAL_ 1548 Consumer_heartbeat_time_1016_45 SubIndex_1016 69-69;
SG_MUL_VAL_ 1548 Consumer_heartbeat_time_1016_44 SubIndex_1016 68-68;
SG_MUL_VAL_ 1548 Consumer_heartbeat_time_1016_43 SubIndex_1016 67-67;
SG_MUL_VAL_ 1548 Consumer_heartbeat_time_1016_42 SubIndex_1016 66-66;
SG_MUL_VAL_ 1548 Consumer_heartbeat_time_1016_41 SubIndex_1016 65-65;
SG_MUL_VAL_ 1548 Consumer_heartbeat_time_1016_40 SubIndex_1016 64-64;
SG_MUL_VAL_ 1548 Consumer_heartbeat_time_1016_3F SubIndex_1016 63-63;
SG_MUL_VAL_ 1548 Consumer_heartbeat_time_1016_3E SubIndex_1016 62-62;
SG_MUL_VAL_ 1548 Consumer_heartbeat_time_1016_3D SubIndex_1016 61-61;
SG_MUL_VAL_ 1548 Consumer_heartbeat_time_1016_3C SubIndex_1016 60-60;
SG_MUL_VAL_ 1548 Consumer_heartbeat_time_1016_3B SubIndex_1016 59-59;
SG_MUL_VAL_ 1548 Consumer_heartbeat_time_1016_3A SubIndex_1016 58-58;
SG_MUL_VAL_ 1548 Consumer_heartbeat_time_1016_39 SubIndex_1016 57-57;
SG_MUL_VAL_ 1548 Consumer_heartbeat_time_1016_38 SubIndex_1016 56-56;
SG_MUL_VAL_ 1548 Consumer_heartbeat_time_1016_37 SubIndex_1016 55-55;
SG_MUL_VAL_ 1548 Consumer_heartbeat_time_1016_36 SubIndex_1016 54-54;
SG_MUL_VAL_ 1548 Consumer_heartbeat_time_1016_35 SubIndex_1016 53-53;
SG_MUL_VAL_ 1548 Consumer_heartbeat_time_1016_34 SubIndex_1016 52-52;
SG_MUL_VAL_ 1548 Consumer_heartbeat_time_1016_33 SubIndex_1016 51-51;
SG_MUL_VAL_ 1548 Consumer_heartbeat_time_1016_32 SubIndex_1016 50-50;
SG_MUL_VAL_ 1548 Consumer_heartbeat_time_1016_31 SubIndex_1016 49-49;
SG_MUL_VAL_ 1548 Consumer_heartbeat_time_1016_30 SubIndex_1016 48-48;
SG_MUL_VAL_ 1548 Consumer_heartbeat_time_1016_2F SubIndex_1016 47-47;
SG_MUL_VAL_ 1548 Consumer_heartbeat_time_1016_2E SubIndex_1016 46-46;
SG_MUL_VAL_ 1548 Consumer_heartbeat_time_1016_2D SubIndex_1016 45-45;
SG_MUL_VAL_ 1548 Consumer_heartbeat_time_1016_2C SubIndex_1016 44-44;
SG_MUL_VAL_ 1548 Consumer_heartbeat_time_1016_2B SubIndex_1016 43-43;
SG_MUL_VAL_ 1548 Consumer_heartbeat_time_1016_2A SubIndex_1016 42-42;
SG_MUL_VAL_ 1548 Consumer_heartbeat_time_1016_29 SubIndex_1016 41-41;
SG_MUL_VAL_ 1548 Consumer_heartbeat_time_1016_28 SubIndex_1016 40-40;
SG_MUL_VAL_ 1548 Consumer_heartbeat_time_1016_27 SubIndex_1016 39-39;
SG_MUL_VAL_ 1548 Consumer_heartbeat_time_1016_26 SubIndex_1016 38-38;
SG_MUL_VAL_ 1548 Consumer_heartbeat_time_1016_25 SubIndex_1016 37-37;
SG_MUL_VAL_ 1548 Consumer_heartbeat_time_1016_24 SubIndex_1016 36-36;
SG_MUL_VAL_ 1548 Consumer_heartbeat_time_1016_23 SubIndex_1016 35-35;
SG_MUL_VAL_ 1548 Consumer_heartbeat_time_1016_22 SubIndex_1016 34-34;
SG_MUL_VAL_ 1548 Consumer_heartbeat_time_1016_21 SubIndex_1016 33-33;
SG_MUL_VAL_ 1548 Consumer_heartbeat_time_1016_20 SubIndex_1016 32-32;
SG_MUL_VAL_ 1548 Consumer_heartbeat_time_1016_1F SubIndex_1016 31-31;
SG_MUL_VAL_ 1548 Consumer_heartbeat_time_1016_1E SubIndex_1016 30-30;
SG_MUL_VAL_ 1548 Consumer_heartbeat_time_1016_1D SubIndex_1016 29-29;
SG_MUL_VAL_ 1548 Consumer_heartbeat_time_1016_1C SubIndex_1016 28-28;
SG_MUL_VAL_ 1548 Consumer_heartbeat_time_1016_1B SubIndex_1016 27-27;
SG_MUL_VAL_ 1548 Consumer_heartbeat_time_1016_1A SubIndex_1016 26-26;
SG_MUL_VAL_ 1548 Consumer_heartbeat_time_1016_19 SubIndex_1016 25-25;
SG_MUL_VAL_ 1548 Consumer_heartbeat_time_1016_18 SubIndex_1016 24-24;
SG_MUL_VAL_ 1548 Consumer_heartbeat_time_1016_17 SubIndex_1016 23-23;
SG_MUL_VAL_ 1548 Consumer_heartbeat_time_1016_16 SubIndex_1016 22-22;
SG_MUL_VAL_ 1548 Consumer_heartbeat_time_1016_15 SubIndex_1016 21-21;
SG_MUL_VAL_ 1548 Consumer_heartbeat_time_1016_14 SubIndex_1016 20-20;
SG_MUL_VAL_ 1548 Consumer_heartbeat_time_1016_13 SubIndex_1016 19-19;
SG_MUL_VAL_ 1548 Consumer_heartbeat_time_1016_12 SubIndex_1016 18-18;
SG_MUL_VAL_ 1548 Consumer_heartbeat_time_1016_11 SubIndex_1016 17-17;
SG_MUL_VAL_ 1548 Consumer_heartbeat_time_1016_10 SubIndex_1016 16-16;
SG_MUL_VAL_ 1548 Consumer_heartbeat_time_1016_0F SubIndex_1016 15-15;
SG_MUL_VAL_ 1548 Consumer_heartbeat_time_1016_0E SubIndex_1016 14-14;
SG_MUL_VAL_ 1548 Consumer_heartbeat_time_1016_0D SubIndex_1016 13-13;
SG_MUL_VAL_ 1548 Consumer_heartbeat_time_1016_0C SubIndex_1016 12-12;
SG_MUL_VAL_ 1548 Consumer_heartbeat_time_1016_0B SubIndex_1016 11-11;
SG_MUL_VAL_ 1548 Consumer_heartbeat_time_1016_0A SubIndex_1016 10-10;
SG_MUL_VAL_ 1548 Consumer_Heartbeat_Time_1016_09 SubIndex_1016 9-9;
SG_MUL_VAL_ 1548 Consumer_Heartbeat_Time_1016_08 SubIndex_1016 8-8;
SG_MUL_VAL_ 1548 Consumer_Heartbeat_Time_1016_07 SubIndex_1016 7-7;
SG_MUL_VAL_ 1548 Consumer_Heartbeat_Time_1016_06 SubIndex_1016 6-6;
SG_MUL_VAL_ 1548 Consumer_Heartbeat_Time_1016_05 SubIndex_1016 5-5;
SG_MUL_VAL_ 1548 Consumer_Heartbeat_Time_1016_04 SubIndex_1016 4-4;
SG_MUL_VAL_ 1548 Consumer_Heartbeat_Time_1016_03 SubIndex_1016 3-3;
SG_MUL_VAL_ 1548 Consumer_Heartbeat_Time_1016_02 SubIndex_1016 2-2;
SG_MUL_VAL_ 1548 Consumer_Heartbeat_Time_1016_01 SubIndex_1016 1-1;
SG_MUL_VAL_ 1548 Highest_sub_index_supported_0000 SubIndex_1016 0-0;
SG_MUL_VAL_ 1548 SubIndex_1016 Index 4118-4118;
SG_MUL_VAL_ 1548 Save_all_Parameters_1010_01 SubIndex_1010 1-1;
SG_MUL_VAL_ 1548 Number_of_Entries_1010_00 SubIndex_1010 0-0;
SG_MUL_VAL_ 1548 SubIndex_1010 Index 4112-4112;
SG_MUL_VAL_ 1548 Life_Time_Factor_100D SubIndex_100D 0-0;
SG_MUL_VAL_ 1548 SubIndex_100D Index 4109-4109;
SG_MUL_VAL_ 1548 Guard_Time_100C SubIndex_100C 0-0;
SG_MUL_VAL_ 1548 SubIndex_100C Index 4108-4108;
SG_MUL_VAL_ 1548 Sync_Window_Length_1007 SubIndex_1007 0-0;
SG_MUL_VAL_ 1548 SubIndex_1007 Index 4103-4103;
SG_MUL_VAL_ 1548 Communication_Cycle_Period_1006 SubIndex_1006 0-0;
SG_MUL_VAL_ 1548 SubIndex_1006 Index 4102-4102;
SG_MUL_VAL_ 1548 COB_ID_SYNC_1005 SubIndex_1005 0-0;
SG_MUL_VAL_ 1548 SubIndex_1005 Index 4101-4101;
SG_MUL_VAL_ 1548 Manufacturer_Status_Registe_0006 SubIndex_1002 0-0;
SG_MUL_VAL_ 1548 SubIndex_1002 Index 4098-4098;
SG_MUL_VAL_ 1548 Error_Register_1001 SubIndex_1001 0-0;
SG_MUL_VAL_ 1548 SubIndex_1001 Index 4097-4097;
SG_MUL_VAL_ 1548 Device_Type_1000 SubIndex_1000 0-0;
SG_MUL_VAL_ 1548 SubIndex_1000 Index 4096-4096;
SG_MUL_VAL_ 1548 Index TransferType 1-1;
SG_MUL_VAL_ 1548 TransferType CCS 1-2;
SG_MUL_VAL_ 1548 NotUsedBytes CCS 1-2;
SG_MUL_VAL_ 1548 SizeIndicator CCS 1-2;
